[part 11 of 12: packages /E40_Platform_System_SystemPackage/Components to /E40_Platform_System_SystemPackage/Types]
AUTOSAR XML (schema 4-2-1)
package /E40_Platform_System_SystemPackage/Components  (continued)
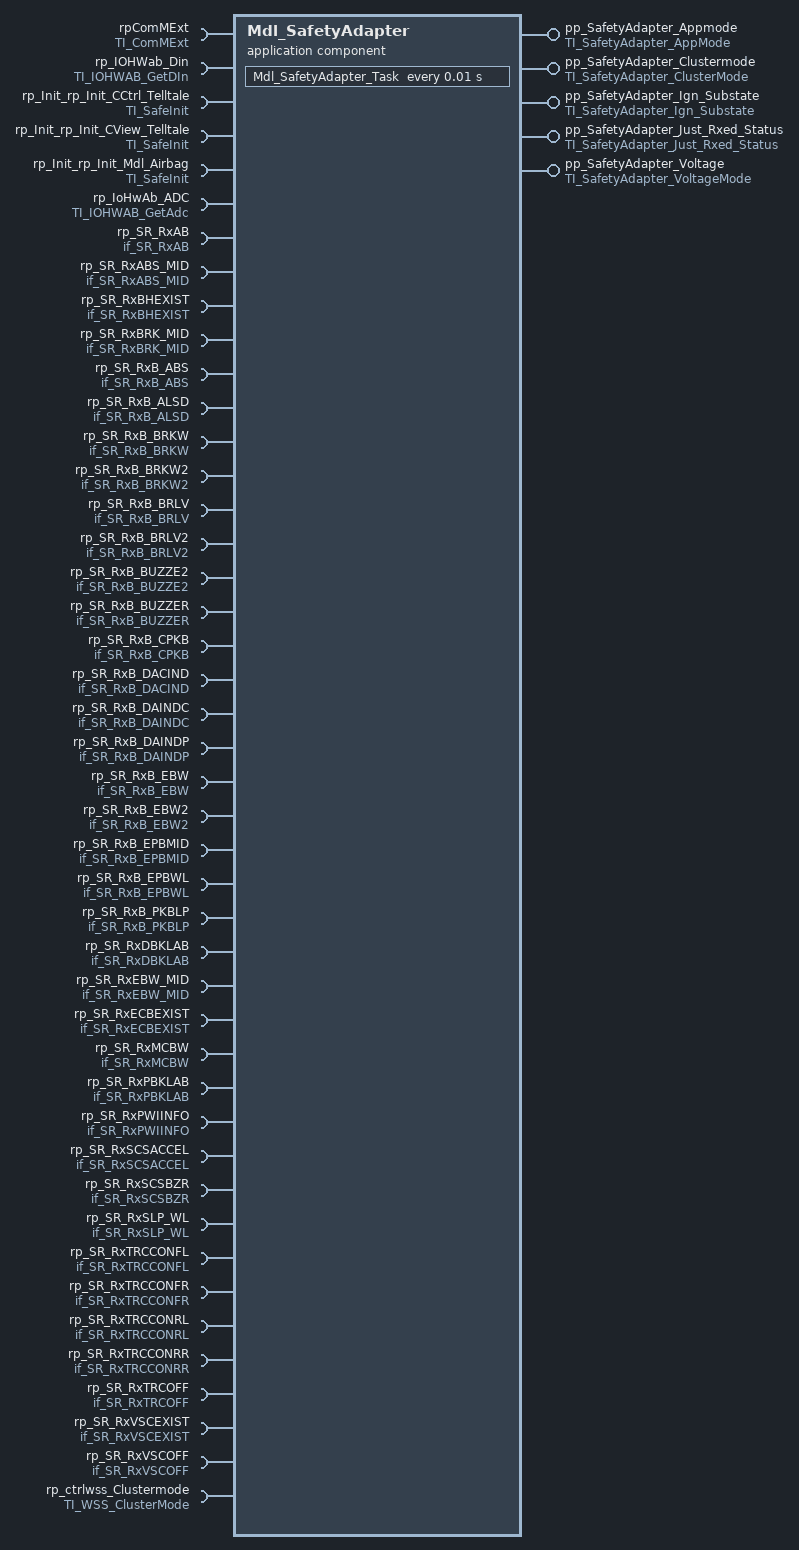
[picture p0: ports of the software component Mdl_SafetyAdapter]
  application sw component type Mdl_SafetyAdapter
    5 x provide port:
      pp_SafetyAdapter_Appmode: nonqueued-sender-com-spec{data-element=SafetyAdapter_AppMode, init-value=constant-reference=Mdl_SafetyAdapterSafetyAdapter_AppModeValue0}, provided-interface=TI_SafetyAdapter_AppMode
      pp_SafetyAdapter_Clustermode: nonqueued-sender-com-spec{data-element=SafetyAdapter_CurrentClusterMode, init-value=constant-reference=Mdl_SafetyAdapterSafetyAdapter_CurrentClusterModeValue0}, provided-interface=TI_SafetyAdapter_ClusterMode
      pp_SafetyAdapter_Ign_Substate: nonqueued-sender-com-spec{data-element=SafetyAdapter_Ign_Substate, init-value=constant-reference=Mdl_SafetyAdapterSafetyAdapter_Ign_SubstateValue0}, provided-interface=TI_SafetyAdapter_Ign_Substate
      pp_SafetyAdapter_Just_Rxed_Status: provided-interface=TI_SafetyAdapter_Just_Rxed_Status
        provided-com-specs:
          operation=TI_SafetyAdapter_Just_Rxed_Status/RxCan_SignalClearJustRcvdStatus, queue-length=1
          operation=TI_SafetyAdapter_Just_Rxed_Status/RxCan_SignalGetJustRcvdStatus, queue-length=1
      pp_SafetyAdapter_Voltage: provided-interface=TI_SafetyAdapter_VoltageMode
        provided-com-specs:
          data-element=SafetyAdapter_HVSD1, init-value=constant-reference=Mdl_SafetyAdapterSafetyAdapter_HVSD1Value0
          data-element=SafetyAdapter_LVSD1, init-value=constant-reference=Mdl_SafetyAdapterSafetyAdapter_LVSD1Value0
    44 x require port:
      rpComMExt: required-interface=TI_ComMExt
      rp_IOHWab_Din: required-interface=TI_IOHWAB_GetDIn
      rp_Init_rp_Init_CCtrl_Telltale: required-interface=TI_SafeInit
      rp_Init_rp_Init_CView_Telltale: required-interface=TI_SafeInit
      rp_Init_rp_Init_Mdl_Airbag: required-interface=TI_SafeInit
      rp_IoHwAb_ADC: required-interface=TI_IOHWAB_GetAdc
      rp_SR_RxAB: nonqueued-receiver-com-spec{data-element=AB, init-value=constant-reference=Mdl_SafetyAdapterABValue0}, required-interface=if_SR_RxAB
      rp_SR_RxABS_MID: nonqueued-receiver-com-spec{data-element=ABS_MID, init-value=constant-reference=Mdl_SafetyAdapterABS_MIDValue0}, required-interface=if_SR_RxABS_MID
      rp_SR_RxBHEXIST: nonqueued-receiver-com-spec{data-element=BHEXIST, init-value=constant-reference=Mdl_SafetyAdapterBHEXISTValue0}, required-interface=if_SR_RxBHEXIST
      rp_SR_RxBRK_MID: nonqueued-receiver-com-spec{data-element=BRK_MID, init-value=constant-reference=Mdl_SafetyAdapterBRK_MIDValue0}, required-interface=if_SR_RxBRK_MID
      rp_SR_RxB_ABS: nonqueued-receiver-com-spec{data-element=B_ABS, init-value=constant-reference=Mdl_SafetyAdapterB_ABSValue0}, required-interface=if_SR_RxB_ABS
      rp_SR_RxB_ALSD: nonqueued-receiver-com-spec{data-element=B_ALSD, init-value=constant-reference=Mdl_SafetyAdapterB_ALSDValue0}, required-interface=if_SR_RxB_ALSD
      rp_SR_RxB_BRKW: nonqueued-receiver-com-spec{data-element=B_BRKW, init-value=constant-reference=Mdl_SafetyAdapterB_BRKWValue0}, required-interface=if_SR_RxB_BRKW
      rp_SR_RxB_BRKW2: nonqueued-receiver-com-spec{data-element=B_BRKW2, init-value=constant-reference=Mdl_SafetyAdapterB_BRKW2Value0}, required-interface=if_SR_RxB_BRKW2
      rp_SR_RxB_BRLV: nonqueued-receiver-com-spec{data-element=B_BRLV, init-value=constant-reference=Mdl_SafetyAdapterB_BRLVValue0}, required-interface=if_SR_RxB_BRLV
      rp_SR_RxB_BRLV2: nonqueued-receiver-com-spec{data-element=B_BRLV2, init-value=constant-reference=Mdl_SafetyAdapterB_BRLV2Value0}, required-interface=if_SR_RxB_BRLV2
      rp_SR_RxB_BUZZE2: nonqueued-receiver-com-spec{data-element=B_BUZZE2, init-value=constant-reference=Mdl_SafetyAdapterB_BUZZE2Value0}, required-interface=if_SR_RxB_BUZZE2
      rp_SR_RxB_BUZZER: nonqueued-receiver-com-spec{data-element=B_BUZZER, init-value=constant-reference=Mdl_SafetyAdapterB_BUZZERValue0}, required-interface=if_SR_RxB_BUZZER
      rp_SR_RxB_CPKB: nonqueued-receiver-com-spec{data-element=B_CPKB, init-value=constant-reference=Mdl_SafetyAdapterB_CPKBValue0}, required-interface=if_SR_RxB_CPKB
      rp_SR_RxB_DACIND: nonqueued-receiver-com-spec{data-element=B_DACIND, init-value=constant-reference=Mdl_SafetyAdapterB_DACINDValue0}, required-interface=if_SR_RxB_DACIND
      rp_SR_RxB_DAINDC: nonqueued-receiver-com-spec{data-element=B_DAINDC, init-value=constant-reference=Mdl_SafetyAdapterB_DAINDCValue0}, required-interface=if_SR_RxB_DAINDC
      rp_SR_RxB_DAINDP: nonqueued-receiver-com-spec{data-element=B_DAINDP, init-value=constant-reference=Mdl_SafetyAdapterB_DAINDPValue0}, required-interface=if_SR_RxB_DAINDP
      rp_SR_RxB_EBW: nonqueued-receiver-com-spec{data-element=B_EBW, init-value=constant-reference=Mdl_SafetyAdapterB_EBWValue0}, required-interface=if_SR_RxB_EBW
      rp_SR_RxB_EBW2: nonqueued-receiver-com-spec{data-element=B_EBW2, init-value=constant-reference=Mdl_SafetyAdapterB_EBW2Value0}, required-interface=if_SR_RxB_EBW2
      rp_SR_RxB_EPBMID: nonqueued-receiver-com-spec{data-element=B_EPBMID, init-value=constant-reference=Mdl_SafetyAdapterB_EPBMIDValue0}, required-interface=if_SR_RxB_EPBMID
      rp_SR_RxB_EPBWL: nonqueued-receiver-com-spec{data-element=B_EPBWL, init-value=constant-reference=Mdl_SafetyAdapterB_EPBWLValue0}, required-interface=if_SR_RxB_EPBWL
      rp_SR_RxB_PKBLP: nonqueued-receiver-com-spec{data-element=B_PKBLP, init-value=constant-reference=Mdl_SafetyAdapterB_PKBLPValue0}, required-interface=if_SR_RxB_PKBLP
      rp_SR_RxDBKLAB: nonqueued-receiver-com-spec{data-element=DBKLAB, init-value=constant-reference=Mdl_SafetyAdapterDBKLABValue0}, required-interface=if_SR_RxDBKLAB
      rp_SR_RxEBW_MID: nonqueued-receiver-com-spec{data-element=EBW_MID, init-value=constant-reference=Mdl_SafetyAdapterEBW_MIDValue0}, required-interface=if_SR_RxEBW_MID
      rp_SR_RxECBEXIST: nonqueued-receiver-com-spec{data-element=ECBEXIST, init-value=constant-reference=Mdl_SafetyAdapterECBEXISTValue0}, required-interface=if_SR_RxECBEXIST
      rp_SR_RxMCBW: nonqueued-receiver-com-spec{data-element=MCBW, init-value=constant-reference=Mdl_SafetyAdapterMCBWValue0}, required-interface=if_SR_RxMCBW
      rp_SR_RxPBKLAB: nonqueued-receiver-com-spec{data-element=PBKLAB, init-value=constant-reference=Mdl_SafetyAdapterPBKLABValue0}, required-interface=if_SR_RxPBKLAB
      rp_SR_RxPWIINFO: nonqueued-receiver-com-spec{data-element=PWIINFO, init-value=constant-reference=Mdl_SafetyAdapterPWIINFOValue0}, required-interface=if_SR_RxPWIINFO
      rp_SR_RxSCSACCEL: nonqueued-receiver-com-spec{data-element=SCSACCEL, init-value=constant-reference=Mdl_SafetyAdapterSCSACCELValue0}, required-interface=if_SR_RxSCSACCEL
      rp_SR_RxSCSBZR: nonqueued-receiver-com-spec{data-element=SCSBZR, init-value=constant-reference=Mdl_SafetyAdapterSCSBZRValue0}, required-interface=if_SR_RxSCSBZR
      rp_SR_RxSLP_WL: nonqueued-receiver-com-spec{data-element=SLP_WL, init-value=constant-reference=Mdl_SafetyAdapterSLP_WLValue0}, required-interface=if_SR_RxSLP_WL
      rp_SR_RxTRCCONFL: nonqueued-receiver-com-spec{data-element=TRCCONFL, init-value=constant-reference=Mdl_SafetyAdapterTRCCONFLValue0}, required-interface=if_SR_RxTRCCONFL
      rp_SR_RxTRCCONFR: nonqueued-receiver-com-spec{data-element=TRCCONFR, init-value=constant-reference=Mdl_SafetyAdapterTRCCONFRValue0}, required-interface=if_SR_RxTRCCONFR
      rp_SR_RxTRCCONRL: nonqueued-receiver-com-spec{data-element=TRCCONRL, init-value=constant-reference=Mdl_SafetyAdapterTRCCONRLValue0}, required-interface=if_SR_RxTRCCONRL
      rp_SR_RxTRCCONRR: nonqueued-receiver-com-spec{data-element=TRCCONRR, init-value=constant-reference=Mdl_SafetyAdapterTRCCONRRValue0}, required-interface=if_SR_RxTRCCONRR
      rp_SR_RxTRCOFF: nonqueued-receiver-com-spec{data-element=TRCOFF, init-value=constant-reference=Mdl_SafetyAdapterTRCOFFValue0}, required-interface=if_SR_RxTRCOFF
      rp_SR_RxVSCEXIST: nonqueued-receiver-com-spec{data-element=VSCEXIST, init-value=constant-reference=Mdl_SafetyAdapterVSCEXISTValue0}, required-interface=if_SR_RxVSCEXIST
      rp_SR_RxVSCOFF: nonqueued-receiver-com-spec{data-element=VSCOFF, init-value=constant-reference=Mdl_SafetyAdapterVSCOFFValue0}, required-interface=if_SR_RxVSCOFF
      rp_ctrlwss_Clustermode: nonqueued-receiver-com-spec{data-element=WSSCurrentClusterMode, init-value=constant-reference=Mdl_SafetyAdapterWSSCurrentClusterModeValue0}, required-interface=TI_WSS_ClusterMode
    behavior IB_Mdl_SafetyAdapter
      4 x data received event:
        DREMdl_SafetyAdapter_OnDataRx_B_EBW2TrigByB_EBW2: start-on-event=Mdl_SafetyAdapter_OnDataRx_B_EBW2, data=rp_SR_RxB_EBW2.B_EBW2
        DREMdl_SafetyAdapter_OnDataRx_B_PKBLPTrigByB_PKBLP: start-on-event=Mdl_SafetyAdapter_OnDataRx_B_PKBLP, data=rp_SR_RxB_PKBLP.B_PKBLP
        DREMdl_SafetyAdapter_OnDataRx_SCSBZRTrigBySCSBZR: start-on-event=Mdl_SafetyAdapter_OnDataRx_SCSBZR, data=rp_SR_RxSCSBZR.SCSBZR
        DREMdl_SafetyAdapter_OnDataRx_VSCOFFTrigByVSCOFF: start-on-event=Mdl_SafetyAdapter_OnDataRx_VSCOFF, data=rp_SR_RxVSCOFF.VSCOFF
      operation invoked event OIE_pp_SafetyAdapter_Just_Rxed_Status_Mdl_SafetyAdapter_RxCan_SignalClearJustRcvdStatusTrigByRxCan_SignalClearJustRcvdStatus: start-on-event=Mdl_SafetyAdapter_RxCan_SignalClearJustRcvdStatus, operation=pp_SafetyAdapter_Just_Rxed_Status.RxCan_SignalClearJustRcvdStatus
      operation invoked event OIE_pp_SafetyAdapter_Just_Rxed_Status_Mdl_SafetyAdapter_RxCan_SignalGetJustRcvdStatusTrigByRxCan_SignalGetJustRcvdStatus: start-on-event=Mdl_SafetyAdapter_RxCan_SignalGetJustRcvdStatus, operation=pp_SafetyAdapter_Just_Rxed_Status.RxCan_SignalGetJustRcvdStatus
      timing event TEMdl_SafetyAdapter_Task: start-on-event=Mdl_SafetyAdapter_Task, period=0.01
      port-api-options:
        enable-take-address=false, indirect-api=false, port=pp_SafetyAdapter_Appmode
        enable-take-address=false, indirect-api=false, port=pp_SafetyAdapter_Clustermode
        enable-take-address=false, indirect-api=false, port=pp_SafetyAdapter_Ign_Substate
        enable-take-address=false, indirect-api=false, port=pp_SafetyAdapter_Just_Rxed_Status
        enable-take-address=false, indirect-api=false, port=pp_SafetyAdapter_Voltage
        enable-take-address=false, indirect-api=false, port=Mdl_SafetyAdapter/rpComMExt
        enable-take-address=false, indirect-api=false, port=rp_IOHWab_Din
        enable-take-address=false, indirect-api=false, port=rp_Init_rp_Init_CCtrl_Telltale
        enable-take-address=false, indirect-api=false, port=rp_Init_rp_Init_CView_Telltale
        enable-take-address=false, indirect-api=false, port=rp_Init_rp_Init_Mdl_Airbag
        enable-take-address=false, indirect-api=false, port=Mdl_SafetyAdapter/rp_IoHwAb_ADC
        enable-take-address=false, indirect-api=false, port=rp_SR_RxAB
        enable-take-address=false, indirect-api=false, port=rp_SR_RxABS_MID
        enable-take-address=false, indirect-api=false, port=rp_SR_RxBHEXIST
        enable-take-address=false, indirect-api=false, port=rp_SR_RxBRK_MID
        enable-take-address=false, indirect-api=false, port=rp_SR_RxB_ABS
        enable-take-address=false, indirect-api=false, port=rp_SR_RxB_ALSD
        enable-take-address=false, indirect-api=false, port=rp_SR_RxB_BRKW
        enable-take-address=false, indirect-api=false, port=rp_SR_RxB_BRKW2
        enable-take-address=false, indirect-api=false, port=rp_SR_RxB_BRLV
        enable-take-address=false, indirect-api=false, port=rp_SR_RxB_BRLV2
        enable-take-address=false, indirect-api=false, port=rp_SR_RxB_BUZZE2
        enable-take-address=false, indirect-api=false, port=rp_SR_RxB_BUZZER
        enable-take-address=false, indirect-api=false, port=rp_SR_RxB_CPKB
        enable-take-address=false, indirect-api=false, port=rp_SR_RxB_DACIND
        enable-take-address=false, indirect-api=false, port=rp_SR_RxB_DAINDC
        enable-take-address=false, indirect-api=false, port=rp_SR_RxB_DAINDP
        enable-take-address=false, indirect-api=false, port=rp_SR_RxB_EBW
        enable-take-address=false, indirect-api=false, port=rp_SR_RxB_EBW2
        enable-take-address=false, indirect-api=false, port=rp_SR_RxB_EPBMID
        enable-take-address=false, indirect-api=false, port=rp_SR_RxB_EPBWL
        enable-take-address=false, indirect-api=false, port=rp_SR_RxB_PKBLP
        enable-take-address=false, indirect-api=false, port=rp_SR_RxDBKLAB
        enable-take-address=false, indirect-api=false, port=rp_SR_RxEBW_MID
        enable-take-address=false, indirect-api=false, port=rp_SR_RxECBEXIST
        enable-take-address=false, indirect-api=false, port=rp_SR_RxMCBW
        enable-take-address=false, indirect-api=false, port=rp_SR_RxPBKLAB
        enable-take-address=false, indirect-api=false, port=rp_SR_RxPWIINFO
        enable-take-address=false, indirect-api=false, port=rp_SR_RxSCSACCEL
        enable-take-address=false, indirect-api=false, port=rp_SR_RxSCSBZR
        enable-take-address=false, indirect-api=false, port=rp_SR_RxSLP_WL
        enable-take-address=false, indirect-api=false, port=rp_SR_RxTRCCONFL
        enable-take-address=false, indirect-api=false, port=rp_SR_RxTRCCONFR
        enable-take-address=false, indirect-api=false, port=rp_SR_RxTRCCONRL
        enable-take-address=false, indirect-api=false, port=rp_SR_RxTRCCONRR
        enable-take-address=false, indirect-api=false, port=rp_SR_RxTRCOFF
        enable-take-address=false, indirect-api=false, port=rp_SR_RxVSCEXIST
        enable-take-address=false, indirect-api=false, port=rp_SR_RxVSCOFF
        enable-take-address=false, indirect-api=false, port=rp_ctrlwss_Clustermode
      7 x runnable, all with can-be-invoked-concurrently=true:
        Mdl_SafetyAdapter_OnDataRx_B_EBW2
        Mdl_SafetyAdapter_OnDataRx_B_PKBLP
        Mdl_SafetyAdapter_OnDataRx_SCSBZR
        Mdl_SafetyAdapter_OnDataRx_VSCOFF
        Mdl_SafetyAdapter_RxCan_SignalClearJustRcvdStatus
        Mdl_SafetyAdapter_RxCan_SignalGetJustRcvdStatus
        Mdl_SafetyAdapter_Task
          data-receive-point-by-arguments:
            38 x access:
              DRA_rp_SR_RxAB_AB: accessed-variable=rp_SR_RxAB.AB
              DRA_rp_SR_RxABS_MID_ABS_MID: accessed-variable=rp_SR_RxABS_MID.ABS_MID
              DRA_rp_SR_RxBHEXIST_BHEXIST: accessed-variable=rp_SR_RxBHEXIST.BHEXIST
              DRA_rp_SR_RxBRK_MID_BRK_MID: accessed-variable=rp_SR_RxBRK_MID.BRK_MID
              DRA_rp_SR_RxB_ABS_B_ABS: accessed-variable=rp_SR_RxB_ABS.B_ABS
              DRA_rp_SR_RxB_ALSD_B_ALSD: accessed-variable=rp_SR_RxB_ALSD.B_ALSD
              DRA_rp_SR_RxB_BRKW_B_BRKW: accessed-variable=rp_SR_RxB_BRKW.B_BRKW
              DRA_rp_SR_RxB_BRKW2_B_BRKW2: accessed-variable=rp_SR_RxB_BRKW2.B_BRKW2
              DRA_rp_SR_RxB_BRLV_B_BRLV: accessed-variable=rp_SR_RxB_BRLV.B_BRLV
              DRA_rp_SR_RxB_BRLV2_B_BRLV2: accessed-variable=rp_SR_RxB_BRLV2.B_BRLV2
              DRA_rp_SR_RxB_BUZZE2_B_BUZZE2: accessed-variable=rp_SR_RxB_BUZZE2.B_BUZZE2
              DRA_rp_SR_RxB_BUZZER_B_BUZZER: accessed-variable=rp_SR_RxB_BUZZER.B_BUZZER
              DRA_rp_SR_RxB_CPKB_B_CPKB: accessed-variable=rp_SR_RxB_CPKB.B_CPKB
              DRA_rp_SR_RxB_DACIND_B_DACIND: accessed-variable=rp_SR_RxB_DACIND.B_DACIND
              DRA_rp_SR_RxB_DAINDC_B_DAINDC: accessed-variable=rp_SR_RxB_DAINDC.B_DAINDC
              DRA_rp_SR_RxB_DAINDP_B_DAINDP: accessed-variable=rp_SR_RxB_DAINDP.B_DAINDP
              DRA_rp_SR_RxB_EBW_B_EBW: accessed-variable=rp_SR_RxB_EBW.B_EBW
              DRA_rp_SR_RxB_EBW2_B_EBW2: accessed-variable=rp_SR_RxB_EBW2.B_EBW2
              DRA_rp_SR_RxB_EPBMID_B_EPBMID: accessed-variable=rp_SR_RxB_EPBMID.B_EPBMID
              DRA_rp_SR_RxB_EPBWL_B_EPBWL: accessed-variable=rp_SR_RxB_EPBWL.B_EPBWL
              DRA_rp_SR_RxB_PKBLP_B_PKBLP: accessed-variable=rp_SR_RxB_PKBLP.B_PKBLP
              DRA_rp_SR_RxDBKLAB_DBKLAB: accessed-variable=rp_SR_RxDBKLAB.DBKLAB
              DRA_rp_SR_RxEBW_MID_EBW_MID: accessed-variable=rp_SR_RxEBW_MID.EBW_MID
              DRA_rp_SR_RxECBEXIST_ECBEXIST: accessed-variable=rp_SR_RxECBEXIST.ECBEXIST
              DRA_rp_SR_RxMCBW_MCBW: accessed-variable=rp_SR_RxMCBW.MCBW
              DRA_rp_SR_RxPBKLAB_PBKLAB: accessed-variable=rp_SR_RxPBKLAB.PBKLAB
              DRA_rp_SR_RxPWIINFO_PWIINFO: accessed-variable=rp_SR_RxPWIINFO.PWIINFO
              DRA_rp_SR_RxSCSACCEL_SCSACCEL: accessed-variable=rp_SR_RxSCSACCEL.SCSACCEL
              DRA_rp_SR_RxSCSBZR_SCSBZR: accessed-variable=rp_SR_RxSCSBZR.SCSBZR
              DRA_rp_SR_RxSLP_WL_SLP_WL: accessed-variable=rp_SR_RxSLP_WL.SLP_WL
              DRA_rp_SR_RxTRCCONFL_TRCCONFL: accessed-variable=rp_SR_RxTRCCONFL.TRCCONFL
              DRA_rp_SR_RxTRCCONFR_TRCCONFR: accessed-variable=rp_SR_RxTRCCONFR.TRCCONFR
              DRA_rp_SR_RxTRCCONRL_TRCCONRL: accessed-variable=rp_SR_RxTRCCONRL.TRCCONRL
              DRA_rp_SR_RxTRCCONRR_TRCCONRR: accessed-variable=rp_SR_RxTRCCONRR.TRCCONRR
              DRA_rp_SR_RxTRCOFF_TRCOFF: accessed-variable=rp_SR_RxTRCOFF.TRCOFF
              DRA_rp_SR_RxVSCEXIST_VSCEXIST: accessed-variable=rp_SR_RxVSCEXIST.VSCEXIST
              DRA_rp_SR_RxVSCOFF_VSCOFF: accessed-variable=rp_SR_RxVSCOFF.VSCOFF
              DRA_rp_ctrlwss_Clustermode_WSSCurrentClusterMode: accessed-variable=rp_ctrlwss_Clustermode.WSSCurrentClusterMode
          data-send-points:
            5 x access:
              DWA_pp_SafetyAdapter_Appmode_SafetyAdapter_AppMode: accessed-variable=pp_SafetyAdapter_Appmode.SafetyAdapter_AppMode
              DWA_pp_SafetyAdapter_Clustermode_SafetyAdapter_CurrentClusterMode: accessed-variable=pp_SafetyAdapter_Clustermode.SafetyAdapter_CurrentClusterMode
              DWA_pp_SafetyAdapter_Ign_Substate_SafetyAdapter_Ign_Substate: accessed-variable=pp_SafetyAdapter_Ign_Substate.SafetyAdapter_Ign_Substate
              DWA_pp_SafetyAdapter_Voltage_SafetyAdapter_HVSD1: accessed-variable=pp_SafetyAdapter_Voltage.SafetyAdapter_HVSD1
              DWA_pp_SafetyAdapter_Voltage_SafetyAdapter_LVSD1: accessed-variable=pp_SafetyAdapter_Voltage.SafetyAdapter_LVSD1
          23 x sync call, all with timeout=0:
            OA_rpComMExt_Get_MCAN_ERR_PIN_Status: operation=rpComMExt.Get_MCAN_ERR_PIN_Status
            OA_rpComMExt_Init: operation=rpComMExt.Init
            OA_rpComMExt_GetBusOffStatus: operation=rpComMExt.GetBusOffStatus
            OA_rpComMExt_CAN_RequestCommunication: operation=rpComMExt.CAN_RequestCommunication
            OA_rpComMExt_CAN_GetCurrentComMode: operation=rpComMExt.CAN_GetCurrentComMode
            OA_rpComMExt_CAN_ReleaseCommunication: operation=rpComMExt.CAN_ReleaseCommunication
            OA_rpComMExt_CAN_DeActivateSilentCommunication: operation=rpComMExt.CAN_DeActivateSilentCommunication
            OA_rpComMExt_CAN_CommControlSetDone: operation=rpComMExt.CAN_CommControlSetDone
            OA_rpComMExt_CAN_CommControlDeActivateTx: operation=rpComMExt.CAN_CommControlDeActivateTx
            OA_rpComMExt_CAN_CommControlDeActivateRx: operation=rpComMExt.CAN_CommControlDeActivateRx
            OA_rpComMExt_CAN_ActivateSilentCommunication: operation=rpComMExt.CAN_ActivateSilentCommunication
            OA_rpComMExt_CAN_CommControlActivateRx: operation=rpComMExt.CAN_CommControlActivateRx
            OA_rpComMExt_CAN_CommControlActivateTx: operation=rpComMExt.CAN_CommControlActivateTx
            OA_rp_IOHWab_Din_GetAsyncRawInput: operation=rp_IOHWab_Din.GetAsyncRawInput
            OA_rp_IOHWab_Din_GetProcessedInput: operation=rp_IOHWab_Din.GetProcessedInput
            OA_rp_IOHWab_Din_GetSyncRawInput: operation=rp_IOHWab_Din.GetSyncRawInput
            OA_rp_IOHWab_Din_GetInputGroup: operation=rp_IOHWab_Din.GetInputGroup
            OA_rp_Init_rp_Init_CCtrl_Telltale_Init: operation=rp_Init_rp_Init_CCtrl_Telltale.Init
            OA_rp_Init_rp_Init_CView_Telltale_Init: operation=rp_Init_rp_Init_CView_Telltale.Init
            OA_rp_Init_rp_Init_Mdl_Airbag_Init: operation=rp_Init_rp_Init_Mdl_Airbag.Init
            OA_rp_IoHwAb_ADC_GetAsyncRawAdc: operation=rp_IoHwAb_ADC.GetAsyncRawAdc
            OA_rp_IoHwAb_ADC_GetSyncRawAdc: operation=rp_IoHwAb_ADC.GetSyncRawAdc
            OA_rp_IoHwAb_ADC_GetProcessedAdc: operation=rp_IoHwAb_ADC.GetProcessedAdc
  43 x constant specification:
    Mdl_SafetyAdapterSafetyAdapter_AppModeValue0: value-spec=Mdl_SafetyAdapterSafetyAdapter_AppModeValue0:0
    Mdl_SafetyAdapterSafetyAdapter_CurrentClusterModeValue0: value-spec=Mdl_SafetyAdapterSafetyAdapter_CurrentClusterModeValue0:0
    Mdl_SafetyAdapterSafetyAdapter_Ign_SubstateValue0: value-spec=Mdl_SafetyAdapterSafetyAdapter_Ign_SubstateValue0:0
    Mdl_SafetyAdapterSafetyAdapter_HVSD1Value0: value-spec=Mdl_SafetyAdapterSafetyAdapter_HVSD1Value0:0
    Mdl_SafetyAdapterSafetyAdapter_LVSD1Value0: value-spec=Mdl_SafetyAdapterSafetyAdapter_LVSD1Value0:0
    Mdl_SafetyAdapterABValue0: value-spec=Mdl_SafetyAdapterABValue0:0
    Mdl_SafetyAdapterABS_MIDValue0: value-spec=Mdl_SafetyAdapterABS_MIDValue0:0
    Mdl_SafetyAdapterBHEXISTValue0: value-spec=Mdl_SafetyAdapterBHEXISTValue0:0
    Mdl_SafetyAdapterBRK_MIDValue0: value-spec=Mdl_SafetyAdapterBRK_MIDValue0:0
    Mdl_SafetyAdapterB_ABSValue0: value-spec=Mdl_SafetyAdapterB_ABSValue0:0
    Mdl_SafetyAdapterB_ALSDValue0: value-spec=Mdl_SafetyAdapterB_ALSDValue0:0
    Mdl_SafetyAdapterB_BRKWValue0: value-spec=Mdl_SafetyAdapterB_BRKWValue0:0
    Mdl_SafetyAdapterB_BRKW2Value0: value-spec=Mdl_SafetyAdapterB_BRKW2Value0:0
    Mdl_SafetyAdapterB_BRLVValue0: value-spec=Mdl_SafetyAdapterB_BRLVValue0:0
    Mdl_SafetyAdapterB_BRLV2Value0: value-spec=Mdl_SafetyAdapterB_BRLV2Value0:0
    Mdl_SafetyAdapterB_BUZZE2Value0: value-spec=Mdl_SafetyAdapterB_BUZZE2Value0:0
    Mdl_SafetyAdapterB_BUZZERValue0: value-spec=Mdl_SafetyAdapterB_BUZZERValue0:0
    Mdl_SafetyAdapterB_CPKBValue0: value-spec=Mdl_SafetyAdapterB_CPKBValue0:0
    Mdl_SafetyAdapterB_DACINDValue0: value-spec=Mdl_SafetyAdapterB_DACINDValue0:0
    Mdl_SafetyAdapterB_DAINDCValue0: value-spec=Mdl_SafetyAdapterB_DAINDCValue0:0
    Mdl_SafetyAdapterB_DAINDPValue0: value-spec=Mdl_SafetyAdapterB_DAINDPValue0:0
    Mdl_SafetyAdapterB_EBWValue0: value-spec=Mdl_SafetyAdapterB_EBWValue0:0
    Mdl_SafetyAdapterB_EBW2Value0: value-spec=Mdl_SafetyAdapterB_EBW2Value0:0
    Mdl_SafetyAdapterB_EPBMIDValue0: value-spec=Mdl_SafetyAdapterB_EPBMIDValue0:0
    Mdl_SafetyAdapterB_EPBWLValue0: value-spec=Mdl_SafetyAdapterB_EPBWLValue0:0
    Mdl_SafetyAdapterB_PKBLPValue0: value-spec=Mdl_SafetyAdapterB_PKBLPValue0:0
    Mdl_SafetyAdapterDBKLABValue0: value-spec=Mdl_SafetyAdapterDBKLABValue0:0
    Mdl_SafetyAdapterEBW_MIDValue0: value-spec=Mdl_SafetyAdapterEBW_MIDValue0:0
    Mdl_SafetyAdapterECBEXISTValue0: value-spec=Mdl_SafetyAdapterECBEXISTValue0:0
    Mdl_SafetyAdapterMCBWValue0: value-spec=Mdl_SafetyAdapterMCBWValue0:0
    Mdl_SafetyAdapterPBKLABValue0: value-spec=Mdl_SafetyAdapterPBKLABValue0:0
    Mdl_SafetyAdapterPWIINFOValue0: value-spec=Mdl_SafetyAdapterPWIINFOValue0:0
    Mdl_SafetyAdapterSCSACCELValue0: value-spec=Mdl_SafetyAdapterSCSACCELValue0:0
    Mdl_SafetyAdapterSCSBZRValue0: value-spec=Mdl_SafetyAdapterSCSBZRValue0:0
    Mdl_SafetyAdapterSLP_WLValue0: value-spec=Mdl_SafetyAdapterSLP_WLValue0:0
    Mdl_SafetyAdapterTRCCONFLValue0: value-spec=Mdl_SafetyAdapterTRCCONFLValue0:0
    Mdl_SafetyAdapterTRCCONFRValue0: value-spec=Mdl_SafetyAdapterTRCCONFRValue0:0
    Mdl_SafetyAdapterTRCCONRLValue0: value-spec=Mdl_SafetyAdapterTRCCONRLValue0:0
    Mdl_SafetyAdapterTRCCONRRValue0: value-spec=Mdl_SafetyAdapterTRCCONRRValue0:0
    Mdl_SafetyAdapterTRCOFFValue0: value-spec=Mdl_SafetyAdapterTRCOFFValue0:0
    Mdl_SafetyAdapterVSCEXISTValue0: value-spec=Mdl_SafetyAdapterVSCEXISTValue0:0
    Mdl_SafetyAdapterVSCOFFValue0: value-spec=Mdl_SafetyAdapterVSCOFFValue0:0
    Mdl_SafetyAdapterWSSCurrentClusterModeValue0: value-spec=Mdl_SafetyAdapterWSSCurrentClusterModeValue0:0
  swc implementation IMPL_Mdl_SafetyAdapter: programming-language=C, behavior=IB_Mdl_SafetyAdapter
    code-descriptors:
      code CodeDescriptor
  constant specification SFastGaugeInfo_InitValue: value-spec={short-label=SFastGaugeInfo_InitValue, fields=[fields=[0, 0, 0, 0, 0], fields=[0, 0, 0, 0, 0]]}
package /E40_Platform_System_SystemPackage/Compositions
  composition sw component type E40_Platform_System
    64 x component:
      CBacklightCdd: type=CBacklightCdd
      CCDD_BswFit: type=CCDD_BswFit
      CCDD_EcuBatteryM: type=CCDD_EcuBatteryM
      CCDD_EcuPowerM: type=CCDD_EcuPowerM
      CCDD_FitManager: type=CCDD_FitManager
      CCDD_McuFit: type=CCDD_McuFit
      CComAbsCtrl: type=CComAbsCtrl
      CComAbsMdl: type=CComAbsMdl
      CComAbsMdlSafe: type=CComAbsMdlSafe
      CCtrl_Telltale: type=CCtrl_Telltale
      DcmApp: type=DcmApp
      DemApp: type=DemApp
      CDisplayCdd: type=CDisplayCdd
      CFltM: type=CFltM
      CFltMExt: type=CFltMExt
      GdtCdd: type=GdtCdd
      CIoExp: type=CIoExp
      CMeetCdd: type=CMeetCdd
      CPmicCdd: type=CPmicCdd
      CRstM: type=CRstM
      RtcCdd: type=RtcCdd
      SafeNvM: type=SafeNvM
      CSigCdd: type=CSigCdd
      CSndCdd: type=CSndCdd
      CSwcDispMonSf: type=CSwcDispMonSf
      CUpdateCdd: type=CUpdateCdd
      CView_Telltale: type=CView_Telltale
      CWarnMsg_Core_Observer: type=CWarnMsg_Core_Observer
      ComCallout: type=ComCallout
      ComMExt: type=ComMExt
      CorTst: type=CorTst
      Ctrl_Illumination: type=Ctrl_Illumination
      Ctrl_WSS: type=Ctrl_WSS
      Ctrl_warning: type=Ctrl_warning
      DcmExt: type=DcmExt
      DemExt: type=DemExt
      Dlt: type=Dlt
      DltExt: type=DltExt
      DmnMgr: type=DmnMgr
      EcuAppM: type=EcuAppM
      EcuMExt: type=EcuMExt
      FastGaugeAdapter: type=FastGaugeAdapter
      FlsTst: type=FlsTst
      IoHwAb: type=IoHwAb
      Mdl_Airbag: type=Mdl_Airbag
      Mdl_Dim: type=Mdl_Dim
      Mdl_Gear: type=Mdl_Gear
      Mdl_Linear_Interpolation: type=Mdl_Linear_Interpolation
      Mdl_SafetyAdapter: type=Mdl_SafetyAdapter
      Mdl_Speed: type=Mdl_Speed
      Mdl_Tacho: type=Mdl_Tacho
      Mdl_TurnHazard: type=Mdl_TurnHazard
      Mdl_wAirbag: type=Mdl_wAirbag
      Mdl_wFuelLidOpen: type=Mdl_wFuelLidOpen
      MemAbstractMdl: type=MemAbstractMdl
      NvMExt: type=NvMExt
      RamTst: type=RamTst
      SlowGaugeAdapter: type=SlowGaugeAdapter
      SysTst: type=SysTst
      TmExt: type=TmExt
      UclProxyCdd: type=UclProxyCdd
      View_Illumination: type=View_Illumination
      View_Speed: type=View_Speed
      WarnMsg_Core_TmrSupport: type=WarnMsg_Core_TmrSupport
    connect IoHwAb.ppIoHwAb_Din -> CBacklightCdd.rpIoHwAb_Din
    connect IoHwAb.ppIoHwAb_DOut -> CBacklightCdd.rpIoHwAb_DOut
    connect IoHwAb.ppIoHwAb_PWM -> CBacklightCdd.rpIoHwAb_PWM
    connect CBacklightCdd.pp_CmpLibCmd_CBacklightCdd -> EcuAppM.rp_CmpLibCmd_rp_CmpLibCmd_CBacklightCdd
    connect IoHwAb.ppIoHwAb_ADC -> CCDD_EcuBatteryM.rpIoHwAb_ADC
    connect IoHwAb.ppIoHwAb_Din -> CCDD_EcuBatteryM.rpIoHwAb_Din
    connect IoHwAb.ppIoHwAb_DOut -> CCDD_EcuBatteryM.rpIoHwAb_DOut
    connect IoHwAb.ppIoHwAb_PWM -> CCDD_EcuBatteryM.rpIoHwAb_PWM
    connect CCDD_EcuBatteryM.pp_CmpLibCmd -> EcuAppM.rp_CmpLibCmd_rp_CmpLibCmd_CCDD_EcuBatteryM
    connect IoHwAb.ppIoHwAb_Din -> CCDD_EcuPowerM.rpIoHwAb_Din
    connect IoHwAb.ppIoHwAb_DOut -> CCDD_EcuPowerM.rpIoHwAb_DOut
    connect IoHwAb.ppIoHwAb_PWM -> CCDD_EcuPowerM.rpIoHwAb_PWM
    connect IoHwAb.ppIoHwAb_ADC -> CCDD_EcuPowerM.rpIoHwAb_ADC
    connect CCDD_EcuPowerM.pp_CmpLibCmd -> EcuAppM.rp_CmpLibCmd_rp_CmpLibCmd_CCDD_EcuPowerM
    connect IoHwAb.ppIoHwAb_Din -> CComAbsCtrl.rp_CS_IoHwAb_Din
    connect ComMExt.ppComMExt -> CComAbsCtrl.rpCSComMExt
    connect MemAbstractMdl.pp_CS_MemAbsGet -> CComAbsMdl.rp_CS_MemAbsGet
    connect CComAbsMdl.pp_CS_RxCanMdl -> CComAbsCtrl.rpCSRxCanMdl
    connect CComAbsMdl.pp_CS_TxCanMdl -> CComAbsCtrl.rpCSTxCanMdl
    connect MemAbstractMdl.pp_CS_MemAbsGet -> CComAbsMdlSafe.rp_CS_MemAbsGet
    connect CComAbsMdlSafe.pp_CS_RxCanMdlSafe -> CComAbsCtrl.rpCS_RxCanMdlSafe
    connect CComAbsMdlSafe.pp_CS_TxCanMdlSafe -> CComAbsCtrl.rpCS_TxCanMdlSafe
    connect CComAbsCtrl.pp_CmpLibCmd_CComAbsCtrl -> EcuAppM.rp_CmpLibCmd_rp_CmpLibCmd_CComAbsCtrl
    connect CComAbsMdl.pp_CmpLibCmd_CComAbsMdl -> EcuAppM.rp_CmpLibCmd_rp_CmpLibCmd_CComAbsMdl
    connect CComAbsMdlSafe.pp_CmpLibCmd_CComAbsMdlSafe -> EcuAppM.rp_CmpLibCmd_rp_CmpLibCmd_CComAbsMdlSafe
    connect IoHwAb.ppIoHwAb_PWM -> Ctrl_Illumination.rp_PwmSetDuty
    assembly sw connector E40_Platform_System_CS_Mdl_Dimrp_CS_RxCanMdl_CComAbsMdlpp_CS_RxCanMdl_if_CS_ComAbsRx: requester=Mdl_Dim.rp_CS_RxCanMdl
    assembly sw connector E40_Platform_System_CS_Ctrl_WSSrp_CS_RxCanMdl_CComAbsMdlpp_CS_RxCanMdl_if_CS_ComAbsRx: requester=Ctrl_WSS.rp_CS_RxCanMdl
    connect IoHwAb.ppIoHwAb_Din -> Ctrl_WSS.rpIoHwAb_Din
    connect ComMExt.ppComMExt -> Ctrl_WSS.rpComMExt
    connect NvMExt.pp_CS_NvMExt_SleepOperations -> Ctrl_WSS.rp_CS_NvMExt_SleepOperations
    connect TmExt.pp_CS_TmExt_Timer_Stop -> Ctrl_WSS.rp_CS_TmExt_Timer_Stop
    connect TmExt.pp_CS_TmExt_Timer_IsElapsed -> Ctrl_WSS.rp_CS_TmExt_Timer_Elapsed
    connect TmExt.pp_CS_TmExt_Timer_Start -> Ctrl_WSS.rp_CS_TmExt_Timer_Start
    connect TmExt.pp_CS_TmExt_Timer_IsStarted -> Ctrl_WSS.rp_CS_TmExt_Timer_Started
    connect IoHwAb.ppIoHwAb_ADC -> Ctrl_WSS.rpIoHwAb_ADC
    connect Mdl_Dim.pp_IlumDayNightStatus -> Ctrl_WSS.rp_IlumDayNightStatus
    connect Ctrl_WSS.pp_ClusterMode -> CWarnMsg_Core_Observer.rp_ClusterMode
    connect Ctrl_WSS.ppIgnSubstate -> CWarnMsg_Core_Observer.rpIgnSubstate
    connect Ctrl_WSS.pp_ClusterMode -> Ctrl_warning.rp_ClusterMode
    connect Ctrl_WSS.ppIgnSubstate -> Ctrl_warning.rpIgnSubstate
    connect Ctrl_warning.ppWarningActiveStatus -> CWarnMsg_Core_Observer.rp_ActiveWarningSts
    connect Ctrl_warning.ppWarnDisplayStatus -> CWarnMsg_Core_Observer.rp_UpdateDisplayStatus
    connect UclProxyCdd.pSR_HealthDomainFatalError -> DmnMgr.rSR_HealthDomainFatalError
    connect UclProxyCdd.pSR_HealthDomainHeartbeat -> DmnMgr.rSR_HealthDomainHeartbeat
    connect UclProxyCdd.pSR_HealthDumpData -> DmnMgr.rSR_HealthDumpData
    connect UclProxyCdd.pSR_HealthDumpHdrInfo -> DmnMgr.rSR_HealthDumpHdrInfo
    connect UclProxyCdd.pSR_PowerExtendShutdownTime -> DmnMgr.rSR_PowerExtendShutdownTime
    connect UclProxyCdd.pSR_PowerKeepSystemAwake -> DmnMgr.rSR_PowerKeepSystemAwake
    connect UclProxyCdd.pSR_PowerSystemState -> DmnMgr.rSR_PowerSystemState
    connect UclProxyCdd.ppCS_UclInitShutdown -> DmnMgr.rpCS_UclInitShutdown
    connect DmnMgr.ppSR_DmnInfo -> DmnMgr.rpSR_DmnInfo
    connect Ctrl_WSS.pp_SleepOperation -> DmnMgr.rp_CS_SleepOperation
    connect DmnMgr.ppCS_UclSystemCallbacks -> UclProxyCdd.rCS_UclSystemCallbacks
    connect DmnMgr.pSR_HealthDumpGetHdr -> UclProxyCdd.rSR_HealthDumpGetHdr
    connect DmnMgr.pSR_HealthDumpGetData -> UclProxyCdd.rSR_HealthDumpGetData
    connect IoHwAb.ppIoHwAb_ADC -> CMeetCdd.rpIoHwAb_ADC
    connect IoHwAb.ppIoHwAb_Din -> CMeetCdd.rpIoHwAb_Din
    connect IoHwAb.ppIoHwAb_DOut -> CMeetCdd.rpIoHwAb_DOut
    connect IoHwAb.ppIoHwAb_PWM -> CMeetCdd.rpIoHwAb_PWM
    connect MemAbstractMdl.pp_CS_MemAbsGet -> CMeetCdd.rp_CS_MemAbsGet
    connect MemAbstractMdl.pp_CS_MemAbsSet -> CMeetCdd.rp_CS_MemAbsSet
    connect MemAbstractMdl.pp_SR_JobStatus -> CMeetCdd.rp_SR_JobStatus
    connect UclProxyCdd.pSR_DiagResponse -> CMeetCdd.rSR_DiagResponse
    connect CMeetCdd.pSR_DiagDIDRequest -> UclProxyCdd.rSR_DiagDIDRequest
    connect CMeetCdd.pSR_DiagRoutineRequest -> UclProxyCdd.rSR_DiagRoutineRequest
    connect CMeetCdd.pSR_DiagIOCtrlRequest -> UclProxyCdd.rSR_DiagIOCtrlRequest
    connect DmnMgr.pSR_PowerSystemStateReqChange -> UclProxyCdd.rSR_PowerSystemStateReqChange
    connect Ctrl_WSS.ppIgnSubstate -> Mdl_Gear.rpIgnSubstate
    connect Ctrl_WSS.pp_VehicleAppMode -> Mdl_Gear.rpVehicleAppMode
    assembly sw connector E40_Platform_System_CS_Mdl_Gearrp_CS_RxCanMdl_CComAbsMdlpp_CS_RxCanMdl_if_CS_ComAbsRx: requester=Mdl_Gear.rp_CS_RxCanMdl
    connect Ctrl_WSS.pp_Variant_status -> Mdl_Gear.rp_Variant_Status
    connect CComAbsMdl.pp_CS_RxCanMdl -> Mdl_Gear.rp_CS_CanRx
    connect Ctrl_WSS.pp_ClusterMode -> Mdl_Gear.rp_ClusterMode
    connect Ctrl_WSS.pp_HMIReady -> Mdl_Gear.rp_HMI_Ready_Status
    connect Mdl_Gear.pp_Shiftpos_ShiftPosIndStatus -> UclProxyCdd.rSR_ShiftPosIndStatus
    connect IoHwAb.ppIoHwAb_PWM -> View_Illumination.rp_PwmSetDuty
    assembly sw connector E40_Platform_System_CS_View_Illuminationrp_GetNVM_IlluminationElement_MemAbstractMdlpp_CS_MemAbsGet_if_CS_MemAbsGet: requester=View_Illumination.rp_GetNVM_IlluminationElement
    connect MemAbstractMdl.pp_CS_MemAbsSet -> View_Illumination.rp_SetNVM_IlluminationElement
    connect IoHwAb.ppIoHwAb_Din -> View_Illumination.rpIoHwAb_Din
    connect Ctrl_WSS.ppIgnSubstate -> View_Illumination.rpIgnSubstate
    connect Ctrl_WSS.pp_VehicleAppMode -> View_Illumination.rpVehicleAppMode
    connect Mdl_Dim.pp_RheostatDayStep -> View_Illumination.rp_RheostatDayStep
    connect Mdl_Dim.pp_RheostatNightStep -> View_Illumination.rp_RheostatNightStep
    connect Mdl_Dim.pp_illum_rheostat_change -> View_Illumination.rp_Rheostat_Change
    connect Ctrl_WSS.pp_TFTDisplayOn -> View_Illumination.rp_TFTDisplayOn
    connect MemAbstractMdl.pp_CS_MemAbsGet -> View_Illumination.rp_CS_MemAbsGet
    connect TmExt.pp_CS_TmExt_Timer_IsElapsed -> View_Illumination.rp_TmExt_Timer_IsElapsed
    connect TmExt.pp_CS_TmExt_Timer_IsStarted -> View_Illumination.rp_TmExt_Timer_IsStarted
    connect TmExt.pp_CS_TmExt_Timer_Start -> View_Illumination.rp_TmExt_Timer_Start
    connect TmExt.pp_CS_TmExt_Timer_Stop -> View_Illumination.rp_TmExt_Timer_Stop
    connect Ctrl_Illumination.pp_IllumCtrl_Op -> View_Illumination.rp_IllumCtrl_Op
    connect CCDD_EcuBatteryM.ppCS_EcuBatteryOutData -> View_Illumination.rp_CS_EcuBatteryOutData
    connect CBacklightCdd.pp_CS_Backlight_service -> View_Illumination.rp_CS_Backlight_service
    connect View_Illumination.pp_UCL_IlluminationData -> UclProxyCdd.rSR_IlluminationData
    connect CWarnMsg_Core_Observer.pp_HUDWarningDisplay -> UclProxyCdd.rSR_HudWarningDisplay
    connect CWarnMsg_Core_Observer.pp_TPMSWarnPayload -> UclProxyCdd.rSR_TpmsWarningData
    connect CWarnMsg_Core_Observer.pp_WarningDisplay -> UclProxyCdd.rSR_WarningDisplay
    connect Ctrl_WSS.pp_ClusterMode -> CView_Telltale.rp_ClusterMode
    connect Ctrl_WSS.ppIgnSubstate -> Mdl_Airbag.rpIgnSubstate
    connect Ctrl_WSS.pp_VehicleAppMode -> Mdl_Airbag.rp_VehicleAppMode
    connect CComAbsMdlSafe.pp_CS_RxCanMdlSafe -> Mdl_Airbag.rp_CS_CanAdapterRx
    connect Ctrl_WSS.pp_ClusterMode -> Mdl_Airbag.rp_ClusterMode
    connect CComAbsMdl.pp_CS_RxCanMdl -> Mdl_Airbag.rp_CS_CanRx
    connect Mdl_Airbag.pp_Airbag_TT_Status -> CView_Telltale.rpTelltlaeStatus_rp_Airbag_TT_Status
    connect Ctrl_WSS.pp_ClusterMode -> Mdl_TurnHazard.rp_ClusterMode
    connect IoHwAb.ppIoHwAb_Din -> Mdl_TurnHazard.rpCS_IoHwAbInp
    connect CComAbsMdl.pp_CS_RxCanMdl -> Mdl_TurnHazard.rp_CS_CanRx
    connect Mdl_TurnHazard.pp_TurnHazard_LeftInd_Sts -> CView_Telltale.rpTelltlaeStatus_rp_TurnHazard_LeftInd_Sts
    connect Mdl_TurnHazard.pp_TurnHazard_RightInd_Sts -> CView_Telltale.rpTelltlaeStatus_rp_TurnHazard_RightInd_Sts
    connect Ctrl_WSS.ppIgnSubstate -> CCtrl_Telltale.rpIgnSubstate
    connect Mdl_Airbag.pp_Airbag_TT_Status -> CCtrl_Telltale.rpTelltlaeStatus_rp_Airbag_TT_Status
    connect Mdl_TurnHazard.pp_TurnHazard_LeftInd_Sts -> CCtrl_Telltale.rpTelltlaeStatus_rp_TurnHazard_LeftInd_Sts
    connect Mdl_TurnHazard.pp_TurnHazard_RightInd_Sts -> CCtrl_Telltale.rpTelltlaeStatus_rp_TurnHazard_RightInd_Sts
    connect Ctrl_WSS.pp_ClusterMode -> CCtrl_Telltale.rp_ClusterMode
    connect Ctrl_WSS.pp_HMIReady -> CCtrl_Telltale.rpHmiReadyState
    connect CCDD_EcuBatteryM.ppCS_EcuBatteryOutData -> CCtrl_Telltale.rp_CS_EcuBatteryOutData
    connect CCtrl_Telltale.ppBlinkStatusArray -> CView_Telltale.rpBlinkStatusArray
    connect CCtrl_Telltale.ppTelltaleStatusOP -> CView_Telltale.rpTelltaleStatusOP
    connect Ctrl_WSS.pp_HMIReady -> CView_Telltale.rp_HMIReady
    connect CView_Telltale.ppTelltaleSts -> UclProxyCdd.rSR_TT_Status
    connect Ctrl_WSS.ppIgnSubstate -> FastGaugeAdapter.rpIgnSubstate
    connect Ctrl_WSS.pp_ClusterMode -> FastGaugeAdapter.rp_ClusterMode
    connect Ctrl_WSS.ppIgnSubstate -> View_Speed.rpIgnSubstate
    connect MemAbstractMdl.pp_CS_MemAbsGet -> View_Speed.rp_CS_MemAbsGet
    connect Ctrl_WSS.ppIgnSubstate -> Mdl_Speed.rpIgnSubstate
    connect MemAbstractMdl.pp_CS_MemAbsGet -> Mdl_Speed.rp_CS_MemAbsGet
    connect CComAbsMdlSafe.pp_CS_RxCanMdlSafe -> Mdl_Speed.rp_CS_CanRx
    connect Ctrl_WSS.pp_ClusterMode -> Mdl_Speed.rp_ClusterMode
    connect Mdl_Linear_Interpolation.pp_LinearInterpolateWord -> Mdl_Speed.rp_CS_LinerInterpolation
    connect IoHwAb.ppIoHwAb_ADC -> Mdl_Speed.rpIoHwAb_ADC
    connect Mdl_Speed.pp_SPD_SP1_In_Status -> View_Speed.rp_SPD_SP1_In_Status
    connect Mdl_Speed.pp_SPD_Target_Status -> View_Speed.rp_SPD_Target_Status
    connect Mdl_Speed.pp_SPD_Trim_Status -> View_Speed.rp_SPD_Trim_Status
    connect CComAbsMdlSafe.pp_CS_TxCanMdlSafe -> View_Speed.rp_CS_TxCanMdl
    connect CComAbsMdlSafe.pp_CS_RxCanMdlSafe -> View_Speed.rp_CS_RxCanMdl
    connect Ctrl_WSS.pp_ClusterMode -> View_Speed.rp_ClusterMode
    connect Mdl_Speed.pp_SPD_Target2_Status -> View_Speed.rp_SPD_Target2_Status
    connect Mdl_Speed.pp_SPD_Trim2_Status -> View_Speed.rp_SPD_Trim2_Status
    connect Mdl_Speed.pp_SPD_Selection_Table -> View_Speed.rp_SPD_Selection_Table
    connect View_Speed.pp_Display_speed_Value -> FastGaugeAdapter.rp_Display_speed_Value
    connect View_Speed.pp_SubDisplaySpeed_Value -> FastGaugeAdapter.rp_SubDisplaySpeed_Value
    connect Ctrl_WSS.ppIgnSubstate -> Mdl_Tacho.rpIgnSubstate
    connect CComAbsMdl.pp_CS_RxCanMdl -> Mdl_Tacho.rp_CS_RxCanMdl
    connect Ctrl_WSS.pp_ClusterMode -> Mdl_Tacho.rp_ClusterMode
    connect Mdl_Speed.pp_SPD_SP1_In_Status -> Mdl_Tacho.rp_SPD_SP1_In_Status
    connect Mdl_Tacho.pp_Analog_Tacho -> FastGaugeAdapter.rp_Analog_Tacho
    connect Mdl_Tacho.pp_Digital_Tacho -> FastGaugeAdapter.rp_Digital_Tacho
    connect Mdl_Tacho.pp_Needle_Transparent -> FastGaugeAdapter.rp_Needle_Transparent
    connect Mdl_Tacho.pp_Tacho_RED_Start_RPM -> FastGaugeAdapter.rp_Tacho_RED_Start_RPM
    connect Mdl_Tacho.pp_TC_Unit -> FastGaugeAdapter.rp_TC_Unit
    connect Mdl_Tacho.pp_Tacho_RPM_MAX -> FastGaugeAdapter.rp_Tacho_RPM_MAX
    connect Ctrl_WSS.pp_HMIReady -> FastGaugeAdapter.rp_HMIReadyState
    connect FastGaugeAdapter.pp_FastGaugeInfo -> UclProxyCdd.rSR_FastGaugeInfo
    connect Ctrl_WSS.ppIgnSubstate -> SlowGaugeAdapter.rpIgnSubstate
    connect Ctrl_WSS.pp_ClusterMode -> SlowGaugeAdapter.rp_ClusterMode
    connect Ctrl_WSS.pp_HMIReady -> SlowGaugeAdapter.rp_HMIReadyState
    connect SlowGaugeAdapter.pp_SlowGaugeInfo -> UclProxyCdd.rSR_SlowGaugeInfo
    connect UclProxyCdd.pSR_UpdateShortServiceResp -> CUpdateCdd.rp_SR_UpdateShortServiceResponse
    connect CUpdateCdd.pp_SR_UpdateShortServiceRequest -> UclProxyCdd.rSR_UpdateShortServiceReq
    connect CUpdateCdd.pp_SR_UpdateLongServiceRequest -> UclProxyCdd.rSR_UpdateLongServiceReq
    connect MemAbstractMdl.pp_CS_MemAbsGet -> DltExt.rp_CS_MemAbsGet
    connect MemAbstractMdl.pp_CS_MemAbsSet -> DltExt.rp_CS_MemAbsSet
    connect MemAbstractMdl.pp_CS_MemAbs_NvMWriteStatus -> DltExt.rp_CS_MemAbs_NvMWriteStatus
    connect UclProxyCdd.pSR_DLTControlMessageRequest -> DltExt.rSR_DLTControlMessageRequest
    connect UclProxyCdd.pSR_DLTMessageReadAck -> DltExt.rSR_DLTMessageReadAck
    connect DltExt.pSR_DLTMessageReadRequest -> UclProxyCdd.rSR_DLTMessageReadRequest
    connect DltExt.pSR_DLTControlMessageReponse -> UclProxyCdd.rSR_DLTControlMessageReponse
    connect UclProxyCdd.pSR_WarningStatus -> CWarnMsg_Core_Observer.rp_WarningStatus
    connect Mdl_Dim.pp_illumStarterstatus -> CWarnMsg_Core_Observer.rp_IllumStartSts
    connect Ctrl_WSS.pp_HMIReady -> CWarnMsg_Core_Observer.rp_HMIReadySts
    connect Ctrl_warning.ppWarnDisplayPayload -> CWarnMsg_Core_Observer.rp_UpdateDisplayPayload
    connect Ctrl_warning.ppActiveWarningStatus -> CWarnMsg_Core_Observer.rpActiveWarningStatus
    connect CComAbsMdl.pp_CS_TxCanMdl -> CWarnMsg_Core_Observer.rp_CS_TxCanMdl
    connect UclProxyCdd.pSR_HudWarningStatus -> CWarnMsg_Core_Observer.rp_HUDWarningStatus
    connect CWarnMsg_Core_Observer.pp_Init -> Ctrl_WSS.rp_Init_rp_Init_CWarnMsg_Core_Observer
    connect Ctrl_Illumination.pp_Init -> Ctrl_WSS.rp_Init_rp_Init_Ctrl_Illumination
    connect Ctrl_warning.pp_Init -> Ctrl_WSS.rp_Init_rp_Init_Ctrl_warning
    connect FastGaugeAdapter.pp_Init -> Ctrl_WSS.rp_Init_rp_Init_FastGaugeAdapter
    connect Mdl_Dim.pp_Init -> Ctrl_WSS.rp_Init_rp_Init_Mdl_Dim
    connect Mdl_Gear.pp_Init -> Ctrl_WSS.rp_Init_rp_Init_Mdl_Gear
    connect Mdl_Linear_Interpolation.pp_Init -> Ctrl_WSS.rp_Init_rp_Init_Mdl_Linear_Interpolation
    connect Mdl_Speed.pp_Init -> Ctrl_WSS.rp_Init_rp_Init_Mdl_Speed
    connect Mdl_Tacho.pp_Init -> Ctrl_WSS.rp_Init_rp_Init_Mdl_Tacho
    connect Mdl_TurnHazard.pp_Init -> Ctrl_WSS.rp_Init_rp_Init_Mdl_TurnHazard
    connect Ctrl_warning.ppCtrlWarningStatus -> Mdl_wAirbag.rpUpdateAirbagWarning
    connect Ctrl_WSS.ppIgnSubstate -> Mdl_wAirbag.rpIgnSubstate
    connect Ctrl_WSS.pp_ClusterMode -> Mdl_wAirbag.rp_ClusterMode
    connect CComAbsMdlSafe.pp_CS_RxCanMdlSafe -> Mdl_wAirbag.rp_CS_CanAdapterSafeRx
    connect Ctrl_WSS.pp_VehicleAppMode -> Mdl_wAirbag.rp_Vehiclestate
    connect Mdl_wAirbag.pp_Init -> Ctrl_WSS.rp_Init_rp_Init_Mdl_wAirbag
    connect Ctrl_warning.ppCtrlWarningStatus -> Mdl_wFuelLidOpen.rpUpdateFuelLidOpenWarning
    connect Ctrl_WSS.ppIgnSubstate -> Mdl_wFuelLidOpen.rpIgnSubstate
    connect CComAbsMdl.pp_CS_RxCanMdl -> Mdl_wFuelLidOpen.rp_CS_RxCanAdapterMdl
    connect Ctrl_WSS.pp_ClusterMode -> Mdl_wFuelLidOpen.rp_ClusterMode
    connect Mdl_wFuelLidOpen.pp_Init -> Ctrl_WSS.rp_Init_rp_Init_Mdl_wFuelLidOpen
    connect SlowGaugeAdapter.pp_Init -> Ctrl_WSS.rp_Init_rp_Init_SlowGaugeAdapter
    connect View_Speed.pp_Init -> Ctrl_WSS.rp_Init_rp_Init_View_Speed
    connect TmExt.pp_CS_TmExt_Timer_IsElapsed -> WarnMsg_Core_TmrSupport.rp_CS_TmExt_Timer_Elapsed
    connect TmExt.pp_CS_TmExt_Timer_Start -> WarnMsg_Core_TmrSupport.rp_CS_TmExt_Timer_Start
    connect TmExt.pp_CS_TmExt_Timer_IsStarted -> WarnMsg_Core_TmrSupport.rp_CS_TmExt_Timer_Started
    connect TmExt.pp_CS_TmExt_Timer_Stop -> WarnMsg_Core_TmrSupport.rp_CS_TmExt_Timer_Stop
    connect WarnMsg_Core_TmrSupport.pp_Init -> Ctrl_WSS.rp_Init_rp_Init_WarnMsg_Core_TmrSupport
    connect CComAbsMdl.pp_CS_RxCanMdl -> Ctrl_WSS.rp_CS_ComAbsRx
    connect MemAbstractMdl.pp_CS_MemAbs_NvMWriteStatus -> Ctrl_WSS.rp_CS_MemAbs_NvMWriteStatus
    connect NvMExt.pp_CS_NvMExt_GetNvMExtReadAllStatus -> Ctrl_WSS.rp_CS_NvMExt_GetNvMExtReadAllStatus
    connect NvMExt.ppSRPhasedRead_Status_phase1readcompleted -> Ctrl_WSS.rpSRPhasedRead_Status_phase1readcompleted
    connect NvMExt.ppSRPhasedRead_Status_phase2readcompleted -> Ctrl_WSS.rpSRPhasedRead_Status_phase2readcompleted
    connect Mdl_TurnHazard.pp_TurnHazard_TurnL_Sts -> Ctrl_WSS.rp_TurnHzdTurnL_Status
    connect Mdl_TurnHazard.pp_TurnHazard_TurnR_Sts -> Ctrl_WSS.rp_TurnHzdTurnR_Status
    connect Mdl_Gear.pp_ShiftPositionDisplay -> Ctrl_WSS.rp_ShiftPositionDisp
    connect CCtrl_Telltale.ppTelltaleStatusOP -> Ctrl_WSS.rpTelltaleStatusOP
    connect CCtrl_Telltale.ppBlinkStatusArray -> Ctrl_WSS.rp_BlinkStsArray
    connect UclProxyCdd.pSR_MainHMIReadyStatus -> Ctrl_WSS.rpUclHMIReadySts
    connect NvMExt.ppSRPhasedRead_Status_phase3readcompleted -> Ctrl_WSS.rpSRPhasedRead_Status_phase3readcompleted
    connect Ctrl_WSS.ppIgnSubstate -> Mdl_Dim.rpIgnSubstate
    connect Ctrl_WSS.pp_VehicleAppMode -> Mdl_Dim.rpVehicleAppMode
    connect Ctrl_WSS.pp_TFTDisplayOn -> Mdl_Dim.rp_TFTDisplayOn
    connect Ctrl_WSS.pp_Variant_status -> Mdl_Dim.rp_Variant_Status
    connect Ctrl_Illumination.pp_StopPwmUpdate -> Mdl_Dim.rp_StopPwmUpdate
    connect Ctrl_WSS.pp_AppMdl_Sleep -> Mdl_Dim.rp_ILL_ReadyToSleep
    connect CComAbsMdl.pp_CS_RxCanMdl -> Mdl_Dim.rp_CS_CanRx
    connect Ctrl_WSS.pp_ClusterMode -> Mdl_Dim.rp_ClusterMode
    connect IoHwAb.ppIoHwAb_Din -> Mdl_Dim.rpIoHwAb_Din
    assembly sw connector E40_Platform_System_CS_Mdl_Dimrp_CS_MemAbsSet_MemAbstractMdlpp_CS_MemAbsSet_if_CS_MemAbsSet: requester=Mdl_Dim.rp_CS_MemAbsSet
    assembly sw connector E40_Platform_System_CS_Mdl_Dimrp_CS_MemAbsGet_MemAbstractMdlpp_CS_MemAbsGet_if_CS_MemAbsGet: requester=Mdl_Dim.rp_CS_MemAbsGet
    connect Ctrl_warning.ppCtrlWarningStatus -> Mdl_Dim.rpUpdateDIMWarning
    connect MemAbstractMdl.pp_CS_MemAbsGet -> Mdl_Dim.rp_GetNVM_IlluminationData
    connect IoHwAb.ppIoHwAb_ADC -> Mdl_Dim.rp_IoHwAb_ADC
    connect Ctrl_Illumination.pp_IlumDayNightRequired -> Mdl_Dim.rp_IlumDayNightRequired
    connect Ctrl_Illumination.pp_IlumDayNightStatus -> Mdl_Dim.rp_IlumDayNightStatus
    connect Ctrl_Illumination.pp_Ctrl_Ready_to_Sleep -> Mdl_Dim.rp_Ctrl_Ready_to_Sleep
    connect MemAbstractMdl.pp_CS_MemAbsSet -> Mdl_Dim.rp_SetNVM_IlluminationData
    connect Mdl_Dim.pp_IlumStep -> Ctrl_Illumination.rp_IlumStep
    assembly sw connector E40_Platform_System_CS_Ctrl_Illuminationrp_GetNVM_IlluminationElement_MemAbstractMdlpp_CS_MemAbsGet_if_CS_MemAbsGet: requester=Ctrl_Illumination.rp_GetNVM_IlluminationElement
    connect MemAbstractMdl.pp_CS_MemAbsSet -> Ctrl_Illumination.rp_SetNVM_IlluminationElement
    connect IoHwAb.ppIoHwAb_Din -> Ctrl_Illumination.rpIoHwAb_Din
    connect Ctrl_WSS.pp_ClusterMode -> Ctrl_Illumination.rp_ClusterMode
    connect Ctrl_WSS.ppIgnSubstate -> Ctrl_Illumination.rpIgnSubstate
    connect Ctrl_WSS.pp_VehicleAppMode -> Ctrl_Illumination.rpVehicleAppMode
    connect CComAbsMdl.pp_CS_RxCanMdl -> Ctrl_Illumination.rp_CS_CanRx
    connect Mdl_Dim.pp_RheostatDayStep -> Ctrl_Illumination.rp_RheostatDayStep
    connect Mdl_Dim.pp_RheostatNightStep -> Ctrl_Illumination.rp_RheostatNightStep
    connect Mdl_Dim.pp_illum_rheostat_change -> Ctrl_Illumination.rp_Rheostat_Change
    connect Ctrl_WSS.pp_TFTDisplayOn -> Ctrl_Illumination.rp_TFTDisplayOn
    connect Ctrl_WSS.pp_AppMdl_Sleep -> Ctrl_Illumination.rp_ILL_ReadyToSleep
    connect MemAbstractMdl.pp_CS_MemAbsGet -> Ctrl_Illumination.rp_CS_MemAbsGet
    connect TmExt.pp_CS_TmExt_Timer_IsElapsed -> Ctrl_Illumination.rp_TmExt_Timer_IsElapsed
    connect TmExt.pp_CS_TmExt_Timer_IsStarted -> Ctrl_Illumination.rp_TmExt_Timer_IsStarted
    connect TmExt.pp_CS_TmExt_Timer_Start -> Ctrl_Illumination.rp_TmExt_Timer_Start
    connect TmExt.pp_CS_TmExt_Timer_Stop -> Ctrl_Illumination.rp_TmExt_Timer_Stop
    connect Mdl_Dim.pp_IllumCtrl_Ip -> Ctrl_Illumination.rp_IllumCtrl_Ip
    connect CCDD_EcuBatteryM.ppCS_EcuBatteryOutData -> Ctrl_Illumination.rp_CS_EcuBatteryOutData
    connect Ctrl_Illumination.pp_CmpLibCmd_CCtrl_Illumination -> EcuAppM.rp_CmpLibCmd_rp_CmpLibCmd_CCtrl_Illumination
    connect CCtrl_Telltale.pp_CmpLibCmd -> EcuAppM.rp_CmpLibCmd_rp_CmpLibCmd_CCtrl_Telltale
    connect DcmApp.pp_CmpLibCmd_CDcmApp -> EcuAppM.rp_CmpLibCmd_rp_CmpLibCmd_CDcmArp
    connect DemExt.pp_CS_DemExt_ClearDTC -> DemApp.rp_CS_DemExt_ClearDTC
    connect DemExt.pp_CS_DemExt_SetEventStatus -> DemApp.rp_CS_DemExt_SetEventStatus
    connect DemExt.pp_CS_DemExt_SetOperationCycleState -> DemApp.rp_CS_DemExt_SetOperationCycleState
    connect DemApp.pp_CmpLibCmd_CDemApp -> EcuAppM.rp_CmpLibCmd_rp_CmpLibCmd_CDemArp
    connect CBacklightCdd.pp_CS_Backlight_Status -> CDisplayCdd.rp_CS_Backlight_Status
    connect CBacklightCdd.pp_CS_Backlight_Notify -> CDisplayCdd.rp_CS_Backlight_Notify
    connect IoHwAb.ppIoHwAb_DOut -> CDisplayCdd.rpIoHwAb_SetDout
    connect UclProxyCdd.pSR_DisplayCurrentState -> CDisplayCdd.rpSRDisplayCurrentState
    connect CDisplayCdd.pp_CmpLibCmd_CDisplayCdd -> EcuAppM.rp_CmpLibCmd_rp_CmpLibCmd_CDisplayCdd
    connect DmnMgr.pp_CmpLibCmd_CDmnMgr -> EcuAppM.rp_CmpLibCmd_rp_CmpLibCmd_CDmnMgr
    connect EcuMExt.ppCS_EcumExt_GetResetReason -> Dlt.rpCS_EcumExt_GetResetReason
    connect Dlt.ppCS_Dlt_SendLogMessage -> CRstM.rp_CS_Dlt_SendLogMessage
    connect DltExt.ppCs_DltExt_GetResetInfo -> CRstM.rp_CS_DltExt_GetResetInfo
    connect CRstM.pp_CS_RstM_GetResetCount -> CFltM.rp_CS_RstM_GetResetCount
    connect CRstM.pp_CS_RstM_RequestSwReset -> CFltM.rp_CS_RstM_RequestSwReset
    connect CRstM.pp_CS_RstM_GetLastResetReason -> CFltM.rp_CS_RstM_GetLastResetReason
    connect DemExt.pp_CS_DemExt_SetEventStatus -> CFltM.rp_CS_DemExt_SetEventStatus
    connect CRstM.pp_CS_RstM_GetResetHistory -> CFltM.rp_CS_RstM_GetResetHistory
    connect CRstM.pp_CS_RstM_ClearResetHistory -> CFltM.rp_CS_RstM_ClearResetHistory
    connect Dlt.ppCS_Dlt_SendLogMessage -> CFltM.rp_CS_Dlt_SendLogMessage
    connect CFltM.pp_CmpLibCmd_CFltM -> EcuAppM.rp_CmpLibCmd_rp_CmpLibCmd_CFltM
    connect CFltM.pp_CS_FltM_ReportFault -> CFltMExt.rp_CS_FltM_ReportFault
    connect CCDD_EcuBatteryM.ppCS_EcuBatteryOutData -> CFltMExt.rp_CS_EcuBatteryOutData
    connect CFltMExt.pp_CmpLibCmd_CFltMExt -> EcuAppM.rp_CmpLibCmd_rp_CmpLibCmd_CFltMExt
    connect TmExt.pp_CS_TmExt_Timer_GetElapsedTime -> GdtCdd.rp_GdtCddTimer_getElapsedTime
    connect TmExt.pp_CS_TmExt_Timer_Start -> GdtCdd.rp_GdtCddTimer_Start
    connect TmExt.pp_CS_TmExt_Timer_Stop -> GdtCdd.rp_GdtTimerStop
    connect GdtCdd.pp_CmpLibCmd_CGdtCdd -> EcuAppM.rp_CmpLibCmd_rp_CmpLibCmd_CGdtCdd
    connect CIoExp.pp_CmpLibCmd_CIoExp -> EcuAppM.rp_CmpLibCmd_rp_CmpLibCmd_CIoExp
    connect CPmicCdd.pp_CmpLibCmd_CPmicCdd -> EcuAppM.rp_CmpLibCmd_rp_CmpLibCmd_CPmicCdd
    connect IoHwAb.ppIoHwAb_ADC -> RtcCdd.rp_CS_IoHwAb_ADC
    connect IoHwAb.ppIoHwAb_Din -> RtcCdd.rp_IoHwAb_Din
    connect IoHwAb.ppIoHwAb_DOut -> RtcCdd.rp_IoHwAb_DOut
    connect RtcCdd.pp_CmpLibCmd_CRTCCdd -> EcuAppM.rp_CmpLibCmd_rp_CmpLibCmd_CRTCCdd
    connect CRstM.pp_CmpLibCmd_CRstM -> EcuAppM.rp_CmpLibCmd_rp_CmpLibCmd_CRstM
    connect SafeNvM.pp_CmpLibCmd_CSafeNvM -> EcuAppM.rp_CmpLibCmd_rp_CmpLibCmd_CSafeNvM
    connect CSigCdd.pp_SigCddCrc -> CSwcDispMonSf.rp_SigCddCrc
    connect CSigCdd.pp_SigCddSts -> CSwcDispMonSf.rp_SigCddSts
    connect CSwcDispMonSf.pp_SigData -> CSigCdd.rp_SigData
    connect CSigCdd.pp_CmpLibCmd_CSigCdd -> EcuAppM.rp_CmpLibCmd_rp_CmpLibCmd_CSigCdd
    connect CSndCdd.pp_CmpLibCmd_CSndCdd -> EcuAppM.rp_CmpLibCmd_rp_CmpLibCmd_CSndCdd
    connect CSwcDispMonSf.pp_CmpLibCmd_CSwcDispMonSf -> EcuAppM.rp_CmpLibCmd_rp_CmpLibCmd_CSwcDispMonSf
    connect UclProxyCdd.pp_CmpLibCmd_CUclProxyCdd -> EcuAppM.rp_CmpLibCmd_rp_CmpLibCmd_CUclProxyCdd
    connect CUpdateCdd.pp_CmpLibCmd_CUpdateCdd -> EcuAppM.rp_CmpLibCmd_rp_CmpLibCmd_CUpdateCdd
    connect View_Illumination.pp_CmpLibCmd_CView_Illumination -> EcuAppM.rp_CmpLibCmd_rp_CmpLibCmd_CView_Illumination
    connect CView_Telltale.pp_CmpLibCmd -> EcuAppM.rp_CmpLibCmd_rp_CmpLibCmd_CView_Telltale
    connect CWarnMsg_Core_Observer.pp_CmpLibCmd -> EcuAppM.rp_CmpLibCmd_rp_CmpLibCmd_CWarnMsg_Core_Observer
    connect CorTst.pp_CmpLibCmd_CorTst -> EcuAppM.rp_CmpLibCmd_rp_CmpLibCmd_CorTst
    connect Ctrl_WSS.pp_CmpLibCmd -> EcuAppM.rp_CmpLibCmd_rp_CmpLibCmd_Ctrl_WSS
    connect FlsTst.pp_CmpLibCmd_FlsTst -> EcuAppM.rp_CmpLibCmd_rp_CmpLibCmd_FlsTst
    connect CMeetCdd.pp_CmpLibCmd_MeetCdd -> EcuAppM.rp_CmpLibCmd_rp_CmpLibCmd_MeetCdd
    connect MemAbstractMdl.pp_CmpLibCmd_MemAbstractMdl -> EcuAppM.rp_CmpLibCmd_rp_CmpLibCmd_MemAbstractMdl
    connect RamTst.pp_CmpLibCmd_RamTst -> EcuAppM.rp_CmpLibCmd_rp_CmpLibCmd_RamTst
    connect SysTst.pp_CmpLibCmd_SysTst -> EcuAppM.rp_CmpLibCmd_rp_CmpLibCmd_SysTst
    connect CBacklightCdd.pp_CS_Backlight_service -> EcuAppM.rp_CS_Backlight_service
    connect CCDD_EcuPowerM.ppCS_RequestPower -> EcuAppM.rpCS_RequestPower
    connect NvMExt.pp_CS_NvmExtStartReadAll -> EcuAppM.rp_CS_NvmExtStartReadAll
    connect NvMExt.pp_CS_NvMExt_SleepOperations -> EcuAppM.rp_CS_NvMExt_SleepOperations
    connect NvMExt.pp_CS_NvMExt_GetNvMExtReadAllStatus -> EcuAppM.rp_CS_NvMExt_GetNvMExtReadAllStatus
    connect EcuMExt.ppCS_EcumExt_ReleaseRUN -> EcuAppM.rpCS_EcumExt_ReleaseRUN
    connect EcuMExt.ppCS_EcumExt_RequestRUN -> EcuAppM.rpCS_EcumExt_RequestRUN
    connect Ctrl_WSS.pp_SleepOperation -> EcuAppM.rp_CS_SleepOperation
    connect Ctrl_WSS.pp_NotifySleepStatus -> EcuAppM.rp_NotifySleepStatus
    connect EcuAppM.ppCS_EcuAppM -> EcuMExt.rpCS_EcuAppM
    connect EcuMExt.ppCS_EcumExt_RequestRUN -> CCDD_BswFit.rpCS_EcumExt_RequestRUN
    connect CCDD_BswFit.ppCS_FitHandler -> CCDD_FitManager.rpCS_FitHandler_rpCS_FitHandler_CCDD_BswFit
    connect EcuMExt.ppCS_EcumExt_RequestRUN -> CCDD_McuFit.rpCS_EcumExt_RequestRUN
    connect CCDD_McuFit.ppCS_FitHandler -> CCDD_FitManager.rpCS_FitHandler_rpCS_FitHandler_CCDD_McuFit
    connect MemAbstractMdl.pp_SR_JobStatus -> DcmExt.rp_SR_JobStatus
    connect CMeetCdd.pp_CS_RID_DiagAction -> DcmExt.rp_CS_RID_DiagAction
    connect MemAbstractMdl.pp_CS_MemAbsSet -> DcmExt.rp_CS_MemAbsSet
    connect MemAbstractMdl.pp_CS_MemAbsGet -> DcmExt.rp_CS_MemAbsGet
    connect CMeetCdd.pp_CS_DID_DiagAction -> DcmExt.rp_CS_DID_DiagAction
    connect DcmApp.pp_CS_DID_App_Diag_Action -> DcmExt.rp_CS_DID_App_DiagAction
    connect DcmApp.pp_CS_RID_App_Diag_Action -> DcmExt.rp_CS_RID_App_DiagAction
    connect DcmApp.pp_CS_DiagEntryStatus -> DcmExt.rp_CS_DiagEntryStatus
    connect CUpdateCdd.pp_CS_UpdateCdd_GenericDIDRequestHandler -> DcmExt.rp_CS_UpdateCdd_DID_DiagAction
    connect CUpdateCdd.pp_CS_UpdateCdd_GenericRIDRequestHandler -> DcmExt.rp_CS_UpdateCdd_RID_DiagAction
    connect CUpdateCdd.pp_CS_UpdateCdd_GenericDownloadRequestHandler -> DcmExt.rp_CS_UpdateCdd_Service_0x34_Handler
    connect CUpdateCdd.pp_CS_UpdateCdd_GenericTransferDataHandler -> DcmExt.rp_CS_UpdateCdd_Service_0x36_Handler
    connect CUpdateCdd.pp_CS_UpdateCdd_GenericTransferExitHandler -> DcmExt.rp_CS_UpdateCdd_Service_0x37_Handler
    connect CUpdateCdd.pp_CS_UpdateCdd_GenericProgSessionRequest -> DcmExt.rp_CS_UpdateCdd_Service_0x10_Handler
    connect IoHwAb.ppIoHwAb_Din -> Mdl_SafetyAdapter.rp_IOHWab_Din
    connect IoHwAb.ppIoHwAb_ADC -> Mdl_SafetyAdapter.rp_IoHwAb_ADC
    connect ComMExt.ppComMExt -> Mdl_SafetyAdapter.rpComMExt
    connect Ctrl_WSS.pp_ClusterMode -> Mdl_SafetyAdapter.rp_ctrlwss_Clustermode
    connect CCtrl_Telltale.pp_Init -> Mdl_SafetyAdapter.rp_Init_rp_Init_CCtrl_Telltale
    connect CView_Telltale.pp_Init -> Mdl_SafetyAdapter.rp_Init_rp_Init_CView_Telltale
    connect Mdl_Airbag.pp_Init -> Mdl_SafetyAdapter.rp_Init_rp_Init_Mdl_Airbag
package /E40_Platform_System_SystemPackage/Types
  impl type EDisplayType: category=VALUE, base-type=uint8, compu {0=e_Display10Inch, 1=e_DisplayMaxDevice}, range raw 0..1
  impl type EDisplayPowerState: category=VALUE, base-type=uint8, compu {0=eDisplayIdle, 1=eDisplayPowerON, 2=eDisplayNormal, 3=eDisplayPowerOFF, 4=eDisplayFault_Handle, 5=eDisplayMaxPowerState}, range raw 0..5
  client server interface TI_Backlight_NotifyDispaly
    operation NotifyDisplayPowerState: possible-error=TI_Backlight_NotifyDispaly/E_NOT_OK
      arg DeviceId: implementation-data-type=EDisplayType, type=EDisplayType, direction=IN
      arg CompletedPowerState: implementation-data-type=EDisplayPowerState, type=EDisplayPowerState, direction=IN
    error E_NOT_OK: error-code=1
  impl type EDeviceStatus: category=VALUE, base-type=uint8, compu {0=eDeviceNotReady, 1=eDeviceInitialized, 2=eDeviceReady, 3=eDeviceBusy, 4=eDeviceFault, 5=eDeviceMaxState}, range raw 0..5
  client server interface TI_Backlight_Status
    operation GetStatus: possible-error=TI_Backlight_Status/E_NOT_OK
      arg DeviceName: implementation-data-type=EDisplayType, type=EDisplayType, direction=IN
      arg DeviceStatus: implementation-data-type=EDeviceStatus, type=EDeviceStatus, direction=OUT
    error E_NOT_OK: error-code=1
  client server interface TI_Backlight_Service
    operation GetBrightnessValue: possible-error=TI_Backlight_Service/E_NOT_OK
      arg DeviceName: implementation-data-type=EDisplayType, type=EDisplayType, direction=IN
      arg BrightnessPercentValue: implementation-data-type=UInt16, type=UInt16, direction=OUT
    operation GetThermalValue: possible-error=TI_Backlight_Service/E_NOT_OK
      arg DeviceName: implementation-data-type=EDisplayType, type=EDisplayType, direction=IN
      arg TempValueInMilliCelsius: implementation-data-type=UInt32, type=UInt32, direction=OUT
    operation SetBrightnessValue: possible-error=TI_Backlight_Service/E_NOT_OK
      arg DeviceName: implementation-data-type=EDisplayType, type=EDisplayType, direction=IN
      arg BrightnessPercentValue: implementation-data-type=UInt16, type=UInt16, direction=IN
    error E_NOT_OK: error-code=1
  impl type ECmpCmd: category=VALUE, base-type=uint8, compu {0=eCmpCmd_Init, 1=eCmpCmd_DeInit, 2=eCmpCmd_Activate, 3=eCmpCmd_DeActivate}, range raw 0..3
  client server interface if_CS_ModeOnCommand
    operation Impl_OnCommand: possible-error=if_CS_ModeOnCommand/E_NOT_OK
      arg cmdP: implementation-data-type=ECmpCmd, type=ECmpCmd, direction=IN
    error E_NOT_OK: error-code=1
  impl type IoHwAb_DOutGroupIdType: category=VALUE, base-type=sint32, compu {0=eIO_DOutGroupIdCount}, range raw -2147483647..2147483647
  impl type IoHwAb_ErrorType: category=VALUE, base-type=uint8, compu {2=E_NO_ERROR, 3=E_ERROR, 4=E_ADC_ERROR, 5=E_DOUT_ID_INVALID, 6=E_DIN_ID_INVALID, 7=E_ADC_ID_INVALID, 8=IOHWAB_E_ADC_ERROR, 9=IOHWAB_E_ADC_ID_INVALID, 10=IOHWAB_E_ERROR, 11=IOHWAB_E_DOUT_ID_INVALID, 12=IOHWAB_E_NO_ERROR, 13=IOHWAB_E_DIN_ID_INVALID}, range raw 2..13
  impl type IoHwAb_DOutSignalIdType:
    category=VALUE
    base-type=uint8
    compu {0=eIO_DOUT_DO_5VSW2_3V3_EN, 1=eIO_DOUT_PARK_BRAKE_TT_OUT, 2=eIO_DOUT_DO_SYC1, 3=eIO_DOUT_SEAT_BELT_TT_MCUOUT, 4=eIO_DOUT_TURN_LEFT_TT_MCUOUT, 5=eIO_DOUT_DO_LCD_BL_PWR_EN, 6=eIO_DOUT_DO_3V3_DISP_SW_EN, 7=eIO_DOUT_AMP_SHTD, 8=eIO_DOUT_FUEL_RHEO_SUP_EN, 9=eIO_DOUT_DO_LCD_STBYB, 10=eIO_DOUT_SBATT2_EN, 11=eIO_DOUT_BRAKE_TT_MCUOUT, 12=eIO_DOUT_AIRBAG_TT_MCUOUT, 13=eIO_DOUT_TURN_RIGHT_TT_MCUOUT, 14=eIO_DOUT_DO_SMPS_5V_SW_EN, 15=eIO_DOUT_PCS_OFF_TT_MCUOUT, 16=eIO_DOUT_ABS_TT_MCUOUT, 17=eIO_DOUT_SLIP_TT_MCUOUT, 18=eIO_DOUT_VCS_OFF_TT_MCUOUT, 19=eIO_DOUT_ECB_EPB_TT_MCUOUT, 20=eIO_DOUT_Flasher_FL_RL_OUT, 21=eIO_DOUT_Flasher_DEN1, 22=eIO_DOUT_Flasher_DSEL1, 23=eIO_DOUT_Flasher_FR_RR_OUT, 24=eIO_DOUT_DO_LCD_RST, 25=eIO_DOUT_DO_SMPS_1V2_EN, 26=eIO_DO_MAX, 27=eIO_DOUT_DO_DISP_RESET, 28=eIO_DOUT_DO_DISP_STBY, 29=eIO_DOUT_DO_TFT_BL_EN, 30=eIO_DOUT_DO_PWM_DIMMING, 31=eIO_DOUT_DO_RTC_INTN, 32=eIO_DOUT_DO_SOC_PWR_LATCH, 33=eIO_DOUT_DO_1V2_EN, 34=eIO_DOUT_DO_EN_5V, 35=eIO_DOUT_DO_ENET_EN, 36=eIO_DOUT_DO_LIN_NSLP, 37=eIO_DOUT_DO_MCU_RESETSTAZ, 38=eIO_DOUT_DO_3V3_DISP, 39=eIO_DOUT_DO_MD_TOUCH_RST, 40=eIO_DOUT_DO_VPP_EN, 41=eIO_DOUT_DO_MD_GNSS_BOOT_EN, 42=eIO_DOUT_DO_MD_GNSS_RESETP, 43=eIO_DOUT_DO_MD_GNSS_PWR_EN, 44=eIO_DOUT_DO_BLU_OPAMP_PWR_EN, 45=eIO_DOUT_DO_BLU_DWALED_EN, 46=eIO_DOUT_DO_TCON_BYPASS_MODE, 47=eIO_DOUT_DO_TCON_BYPASS_SEL0, 48=eIO_DOUT_DO_TCON_BYPASS_SEL1, 49=eIO_DOUT_DO_SOC_FPDLINK3_PDB, 50=eIO_DOUT_DO_SOC_FPDLINK3_INTB, 51=eIO_DOUT_DO_SOC_FPDLINK3_BISTEN, 52=eIO_DOUT_DO_ENET_RSTB, 53=eIO_DOUT_DO_EN_BUCK_FALD, 54=eIO_DOUT_DO_MCU_AMUX_S1, 55=eIO_DOUT_DO_MCU_AMUX_S0, 56=eIO_DOUT_DO_TCON_SPI0_CS0, 57=eIO_DOUT_DO_SPI_CAN_CS, 58=eIO_DOUT_DESER_SPI1_DO, 59=eIO_DOUT_DO_SOC_TCON_GRBN, 60=eIO_DOUT_DO_TFT_CSB}
    range raw 0..60
  client server interface TI_IOHWAB_SetDout
    operation SetOutputGroup: possible-error=TI_IOHWAB_SetDout/E_NOT_OK
      arg InputId: implementation-data-type=IoHwAb_DOutGroupIdType, type=IoHwAb_DOutGroupIdType, direction=IN
      arg OutputGroup: implementation-data-type=UInt32, type=UInt32, direction=IN
      arg ErrorStatus: implementation-data-type=IoHwAb_ErrorType, type=IoHwAb_ErrorType, direction=OUT
    operation SetOutputPin: possible-error=TI_IOHWAB_SetDout/E_NOT_OK
      arg InputId: implementation-data-type=IoHwAb_DOutSignalIdType, type=IoHwAb_DOutSignalIdType, direction=IN
      arg OutputSignal: implementation-data-type=Boolean, type=Boolean, direction=IN
      arg ErrorStatus: implementation-data-type=IoHwAb_ErrorType, type=IoHwAb_ErrorType, direction=OUT
    error E_NOT_OK: error-code=1
  impl type IoHwAb_DInSignalIdType:
    category=VALUE
    base-type=uint8
    compu {0=eIO_DIN_DI_AL_HAZARD, 1=eIO_DIN_DI_AH_IGNITION, 2=eIO_DIN_DI_SMPS_3V3_PG, 3=eIO_DIN_STOP_LAMP_MCU, 4=eIO_DIN_DI_AL_BRAKE_LEVEL, 5=eIO_DIN_DI_AL_OIL_W, 6=eIO_DIN_DI_AL_DRV_SEAT_BUCKLE, 7=eIO_DIN_DI_AL_WASHER_LEVEL_SW, 8=eIO_DIN_ODO_TripKnobInput, 9=eIO_DIN_DI_AL_VACUUM, 10=eIO_DIN_DI_LCD_BL_PWR_FAULT, 11=eIO_DIN_DI_AL_FUEL_LID_EFI_ECU, 12=eIO_DIN_DI_TT_SHIFT_ERR, 13=eIO_DIN_MAX, 14=eIO_DIN_DI_PMIC_INTN, 15=eIO_DIN_DI_MCU_PORZ, 16=eIO_DIN_DI_SBATT2_ERR, 17=eIO_DIN_DI_FALD_PG, 18=eIO_DIN_DI_MD_TOUCH_INTN, 19=eIO_DIN_DI_BL_FAULT, 20=eIO_DIN_DI_SOC_FPDLINK3_LOCK, 21=eIO_DIN_DI_SOC_FPDLINK3_PASS, 22=eIO_DIN_DI_ENET_MII_INT, 23=eIO_DIN_DI_IGN_MON, 24=eIO_DIN_DI_CABLE_DETECT, 25=eIO_DIN_DI_TCON_IND_OUT, 26=eIO_DIN_DI_SPI_CAN_TCON_SDI, 27=eIO_DIN_DI_MCU_FALD_CONN_CHK, 28=eIO_DIN_DI_LDO_1V2_FAULTN, 29=eIO_DIN_DI_TFT_ER_DET}
    range raw 0..29
  impl type IoHwAb_DInGroupIdType: category=VALUE, base-type=sint32, compu {0=eIO_DInGroupIdCount}, range raw -2147483647..2147483647
  client server interface TI_IOHWAB_GetDIn
    4 x operation, all with possible-error=TI_IOHWAB_GetDIn/E_NOT_OK:
      GetAsyncRawInput
        arg InputId: implementation-data-type=IoHwAb_DInSignalIdType, type=IoHwAb_DInSignalIdType, direction=IN
        arg AsyncInput: implementation-data-type=Boolean, type=Boolean, direction=OUT
        arg ErrorStatus: implementation-data-type=IoHwAb_ErrorType, type=IoHwAb_ErrorType, direction=OUT
      GetInputGroup
        arg InputId: implementation-data-type=IoHwAb_DInGroupIdType, type=IoHwAb_DInGroupIdType, direction=IN
        arg SyncInput: implementation-data-type=UInt32, type=UInt32, direction=OUT
        arg ErrorStatus: implementation-data-type=IoHwAb_ErrorType, type=IoHwAb_ErrorType, direction=OUT
      GetProcessedInput
        arg InputId: implementation-data-type=IoHwAb_DInSignalIdType, type=IoHwAb_DInSignalIdType, direction=IN
        arg InputSignal: implementation-data-type=Boolean, type=Boolean, direction=OUT
        arg ErrorStatus: implementation-data-type=IoHwAb_ErrorType, type=IoHwAb_ErrorType, direction=OUT
      GetSyncRawInput
        arg InputId: implementation-data-type=IoHwAb_DInSignalIdType, type=IoHwAb_DInSignalIdType, direction=IN
        arg SyncInput: implementation-data-type=Boolean, type=Boolean, direction=OUT
        arg ErrorStatus: implementation-data-type=IoHwAb_ErrorType, type=IoHwAb_ErrorType, direction=OUT
    error E_NOT_OK: error-code=1
  impl type IoHwAb_PwmSignalIdType: category=VALUE, base-type=uint8, compu {0=eIO_PWM_MCU_BUZZER_AMPLCTRL, 1=eIO_PWM_HIGH_BEAM_TT_MCUOUT, 2=eIO_PWM_FUEL_TEMP_GAUG_TEXT_PWM_OUT, 3=eIO_PWM_PWM_OUT_ILL2, 4=eIO_PWM_PWM_OUT_ILL1, 5=eIO_PWM_BG_Dimming_PWM, 6=eIO_PWM_PWM_GREEN_TT_DIMMING, 7=eIO_PWM_CXPI_CLK, 8=eIO_PWM_PWM_LCD_BL_DIMMING, 9=eIO_PWM_MAX}, range raw 0..9
  client server interface TI_IOHWAB_PWM
    operation PwmSetDuty: possible-error=TI_IOHWAB_PWM/E_NOT_OK
      arg PwmId: implementation-data-type=IoHwAb_PwmSignalIdType, type=IoHwAb_PwmSignalIdType, direction=IN
      arg Pwm_Duty: implementation-data-type=UInt16, type=UInt16, direction=IN
      arg ErrorStatus: implementation-data-type=IoHwAb_ErrorType, type=IoHwAb_ErrorType, direction=OUT
    operation PwmSetDutyAndPeriod: possible-error=TI_IOHWAB_PWM/E_NOT_OK
      4 x arg:
        PwmId: implementation-data-type=IoHwAb_PwmSignalIdType, type=IoHwAb_PwmSignalIdType, direction=IN
        Pwm_Period: implementation-data-type=UInt32, type=UInt32, direction=IN
        Pwm_Duty: implementation-data-type=UInt16, type=UInt16, direction=IN
        ErrorStatus: implementation-data-type=IoHwAb_ErrorType, type=IoHwAb_ErrorType, direction=OUT
    operation PwmSetIdeal: possible-error=TI_IOHWAB_PWM/E_NOT_OK
      arg PwmId: implementation-data-type=IoHwAb_PwmSignalIdType, type=IoHwAb_PwmSignalIdType, direction=IN
      arg ErrorStatus: implementation-data-type=IoHwAb_ErrorType, type=IoHwAb_ErrorType, direction=OUT
    error E_NOT_OK: error-code=1
  impl type IoHwAb_AdcSignalIdType:
    category=VALUE
    base-type=uint8
    compu {16=eIO_ADC_ADC_FUEL_5V_MON, 17=eIO_ADC_ADC_FUEL_MAIN, 2=eIO_ADC_IGN_AD, 3=eIO_ADC_FUEL_SEND_SUB_MICRO_AD, 4=eIO_ADC_AI_BATTERY, 5=eIO_ADC_AI_LCD_NTC, 6=eIO_ADC_AI_TEMP_RTC, 7=eIO_ADC_Flasher_Diag_sense_1, 8=eIO_ADC_STR_SW2_ADIN, 9=eIO_ADC_STR_SW1_ADIN, 10=eIO_ADC_RHEO_SW_IN_ADIN, 11=eIO_ADC_ADC_RHEO_5V_MON_ADIN, 12=eIO_ADC_Flasher_Diag_sense_2, 13=eIO_ADC_AdcChannel_Vdb, 14=eIO_ADC_AdcChannel_Vtemp, 15=eIO_ADC_MAX, 0=eIO_ADC_AI_SAMPLE_1, 1=eIO_ADC_AI_SAMPLE_2}
    range raw 0..17
  client server interface TI_IOHWAB_GetAdc
    operation GetAsyncRawAdc: possible-error=TI_IOHWAB_GetAdc/E_NOT_OK
      arg AdcId: implementation-data-type=IoHwAb_AdcSignalIdType, type=IoHwAb_AdcSignalIdType, direction=IN
      arg AsyncRawAdc: implementation-data-type=UInt16, type=UInt16, direction=OUT
      arg ErrorStatus: implementation-data-type=IoHwAb_ErrorType, type=IoHwAb_ErrorType, direction=OUT
    operation GetProcessedAdc: possible-error=TI_IOHWAB_GetAdc/E_NOT_OK
      arg AdcId: implementation-data-type=IoHwAb_AdcSignalIdType, type=IoHwAb_AdcSignalIdType, direction=IN
      arg ProcessedAdc: implementation-data-type=SInt32, type=SInt32, direction=OUT
      arg ErrorStatus: implementation-data-type=IoHwAb_ErrorType, type=IoHwAb_ErrorType, direction=OUT
    operation GetSyncRawAdc: possible-error=TI_IOHWAB_GetAdc/E_NOT_OK
      arg AdcId: implementation-data-type=IoHwAb_AdcSignalIdType, type=IoHwAb_AdcSignalIdType, direction=IN
      arg SyncRawAdc: implementation-data-type=UInt16, type=UInt16, direction=OUT
      arg ErrorStatus: implementation-data-type=IoHwAb_ErrorType, type=IoHwAb_ErrorType, direction=OUT
    error E_NOT_OK: error-code=1
  impl type eIOPulseInputId: category=VALUE, base-type=sint32, compu {0=eIOPulseInputIdCount}, range raw -2147483647..2147483647
  impl type SPulseInputConfigParam: category=STRUCTURE
    16 x element, all with category=TYPE_REFERENCE:
      MissingRecoveryTimeoutInMicroSec: implementation-data-type=UInt32
      ValidPeriodMinInMicroSec: implementation-data-type=UInt32
      ValidPeriodMaxInMicroSec: implementation-data-type=UInt32
      HystLimitForPeriodMinInMicroSec: implementation-data-type=UInt32
      HystRcvryForPeriodMinInMicroSec: implementation-data-type=UInt32
      HystLimitForPeriodMaxInMicroSec: implementation-data-type=UInt32
      HystRcvryForPeriodMaxInMicroSec: implementation-data-type=UInt32
      ValidDutyMinInPercentage: implementation-data-type=UInt16
      ValidDutyMaxInPercentage: implementation-data-type=UInt16
      HystLimitForDutyMinInPercentage: implementation-data-type=UInt16
      HystRcvryForDutyMinInPercentage: implementation-data-type=UInt16
      HystLimitForDutyMaxInPercentage: implementation-data-type=UInt16
      HystRcvryForDutyMaxInPercentage: implementation-data-type=UInt16
      InValidTimeoutInMilliSec: implementation-data-type=UInt16
      InValidRecoveryTimeoutInMilliSec: implementation-data-type=UInt16
      MissingTimeoutInMilliSec: implementation-data-type=UInt16
  impl type SSpeedCalcParam: category=STRUCTURE
    element Pulses_Per_Revolution: implementation-data-type=UInt32
    element Revolutions_Per_Unit: implementation-data-type=UInt32
    element Tuning_Factor: implementation-data-type=UInt32
  client server interface TI_IOHWAB_Pulse
    7 x operation, all with possible-error=TI_IOHWAB_Pulse/E_NOT_OK:
      GetCurrentSignalStatus_PulseInput
        arg PulseInputId: implementation-data-type=eIOPulseInputId, type=eIOPulseInputId, direction=IN
        arg SignalStatus: implementation-data-type=UInt16, type=UInt16, direction=OUT
        arg ErrorStatus: implementation-data-type=IoHwAb_ErrorType, type=IoHwAb_ErrorType, direction=OUT
      GetCurrentSpeed_PulseInput
        arg PulseInputId: implementation-data-type=eIOPulseInputId, type=eIOPulseInputId, direction=IN
        arg SpeedVal: implementation-data-type=UInt32, type=UInt32, direction=OUT
        arg ErrorStatus: implementation-data-type=IoHwAb_ErrorType, type=IoHwAb_ErrorType, direction=OUT
      GetRollingCount_PulseInput
        arg PulseInputId: implementation-data-type=eIOPulseInputId, type=eIOPulseInputId, direction=IN
        arg EdgeCount: implementation-data-type=DataTypes/UInt8, type=DataTypes/UInt8, direction=OUT
        arg ErrorStatus: implementation-data-type=IoHwAb_ErrorType, type=IoHwAb_ErrorType, direction=OUT
      ResetRollingCount_PulseInput
        arg PulseInputId: implementation-data-type=eIOPulseInputId, type=eIOPulseInputId, direction=IN
        arg ErrorStatus: implementation-data-type=IoHwAb_ErrorType, type=IoHwAb_ErrorType, direction=OUT
      Start_Signal_Measurement_PulseInput
        4 x arg:
          PulseInputId: implementation-data-type=eIOPulseInputId, type=eIOPulseInputId, direction=IN
          PulseInputChnlCfgParam: implementation-data-type=SPulseInputConfigParam, type=SPulseInputConfigParam, direction=OUT
          SpdCalParam: implementation-data-type=SSpeedCalcParam, type=SSpeedCalcParam, direction=OUT
          ErrorStatus: implementation-data-type=IoHwAb_ErrorType, type=IoHwAb_ErrorType, direction=OUT
      Stop_Signal_Measurement_PulseInput
        arg PulseInputId: implementation-data-type=eIOPulseInputId, type=eIOPulseInputId, direction=IN
        arg ErrorStatus: implementation-data-type=IoHwAb_ErrorType, type=IoHwAb_ErrorType, direction=OUT
      Update_CalibParam_PulseInput
        arg PulseInputId: implementation-data-type=eIOPulseInputId, type=eIOPulseInputId, direction=IN
        arg SpdCalParam: implementation-data-type=SSpeedCalcParam, type=SSpeedCalcParam, direction=OUT
        arg ErrorStatus: implementation-data-type=IoHwAb_ErrorType, type=IoHwAb_ErrorType, direction=OUT
    error E_NOT_OK: error-code=1
  client server interface TI_FaultInjectionHandler
    operation FaultInjectionHandler: possible-error=TI_FaultInjectionHandler/E_NOT_OK
      arg StartStopData: implementation-data-type=DataTypes/UInt8, type=DataTypes/UInt8, direction=IN
      arg TestListID: implementation-data-type=DataTypes/UInt8, type=DataTypes/UInt8, direction=IN
      arg Data: implementation-data-type=DataTypes/UInt8, type=DataTypes/UInt8, direction=OUT
    error E_NOT_OK: error-code=1
  impl type EcuM_UserType: category=VALUE, base-type=uint8, range raw 0..255
  12 x client server interface:
    TI_EcuMExt_RequestRUN
      operation RequestRUN: possible-error=TI_EcuMExt_RequestRUN/E_NOT_OK
        arg user: implementation-data-type=EcuM_UserType, type=EcuM_UserType, direction=IN
      error E_NOT_OK: error-code=1
    TI_EcuMExt_GetResetReason
      operation GetResetReason: possible-error=TI_EcuMExt_GetResetReason/E_NOT_OK
      error E_NOT_OK: error-code=1
    TI_EcuMExt_ReleaseRUN
      operation ReleaseRUN: possible-error=TI_EcuMExt_ReleaseRUN/E_NOT_OK
        arg user: implementation-data-type=EcuM_UserType, type=EcuM_UserType, direction=IN
      error E_NOT_OK: error-code=1
    if_CS_EcuAppM
      operation EcuAppM_SetWakeupSources
        arg WakeupSource: implementation-data-type=UInt32, type=UInt32, direction=IN
      operation Init
    TI_EcuPowerM
      operation EcuPowerM_GetDeviceStatus: possible-error=TI_EcuPowerM/E_NOT_OK
        arg device: implementation-data-type=DataTypes/UInt8, type=DataTypes/UInt8, direction=IN
        arg status: implementation-data-type=DataTypes/UInt8, type=DataTypes/UInt8, direction=OUT
      operation EcuPowerM_RequestPower: possible-error=TI_EcuPowerM/E_NOT_OK
        arg device: implementation-data-type=DataTypes/UInt8, type=DataTypes/UInt8, direction=IN
        arg request: implementation-data-type=DataTypes/UInt8, type=DataTypes/UInt8, direction=IN
      error E_NOT_OK: error-code=1
    TI_NvMExt_GetReadAllStatus
      operation NvmExt_GetNvMReadAllStatus
        arg Status: implementation-data-type=Boolean, type=Boolean, direction=OUT
    TI_NvMExt_SleepOperations
      operation NvMExt_CancelSleep: possible-error=TI_NvMExt_SleepOperations/E_NOT_OK
      operation NvMExt_ReadytoSleep: possible-error=TI_NvMExt_SleepOperations/E_NOT_OK
      operation NvMExt_RequestSleep: possible-error=TI_NvMExt_SleepOperations/E_NOT_OK
      error E_NOT_OK: error-code=1
    TI_NvmExt_StartNvmReadAll
      operation NvMExt_ReadAll
    TI_WSS_SleepOperations
      operation CtrlWSS_CancelSleep: possible-error=TI_WSS_SleepOperations/E_NOT_OK
      operation CtrlWSS_ReadytoSleep: possible-error=TI_WSS_SleepOperations/E_NOT_OK
      operation CtrlWSS_RequestSleep: possible-error=TI_WSS_SleepOperations/E_NOT_OK
      error E_NOT_OK: error-code=1
    TI_WSS_SWCNotifySleepStatus
      operation CtrlWSS_NotifyNetworkSleep: possible-error=TI_WSS_SWCNotifySleepStatus/E_NOT_OK
        arg NotifyStatus: implementation-data-type=DataTypes/UInt8, type=DataTypes/UInt8, direction=OUT
      error E_NOT_OK: error-code=1
    TI_EcuBatteryMData
      operation EcuBatteryM_GetChannelStatus: possible-error=TI_EcuBatteryMData/E_NOT_OK
        arg Channel: implementation-data-type=DataTypes/UInt8, type=DataTypes/UInt8, direction=IN
        arg Status: implementation-data-type=DataTypes/UInt8, type=DataTypes/UInt8, direction=OUT
      operation EcuBatteryM_GetDIOStatus: possible-error=TI_EcuBatteryMData/E_NOT_OK
        arg InputId: implementation-data-type=DataTypes/UInt8, type=DataTypes/UInt8, direction=IN
        arg Status: implementation-data-type=DataTypes/UInt8, type=DataTypes/UInt8, direction=OUT
      error E_NOT_OK: error-code=1
    TI_ComMExt
      13 x operation:
        CAN_ActivateSilentCommunication: possible-error=TI_ComMExt/E_NOT_OK
          arg Channel: implementation-data-type=DataTypes/UInt8, type=DataTypes/UInt8, direction=IN
        CAN_CommControlActivateRx: possible-error=TI_ComMExt/E_NOT_OK
          arg Channel: implementation-data-type=DataTypes/UInt8, type=DataTypes/UInt8, direction=IN
        CAN_CommControlActivateTx: possible-error=TI_ComMExt/E_NOT_OK
          arg Channel: implementation-data-type=DataTypes/UInt8, type=DataTypes/UInt8, direction=IN
        CAN_CommControlDeActivateRx: possible-error=TI_ComMExt/E_NOT_OK
          arg Channel: implementation-data-type=DataTypes/UInt8, type=DataTypes/UInt8, direction=IN
        CAN_CommControlDeActivateTx: possible-error=TI_ComMExt/E_NOT_OK
          arg Channel: implementation-data-type=DataTypes/UInt8, type=DataTypes/UInt8, direction=IN
        CAN_CommControlSetDone
          arg PduInitRequest: implementation-data-type=Boolean, type=Boolean, direction=IN
        CAN_DeActivateSilentCommunication: possible-error=TI_ComMExt/E_NOT_OK
          arg Channel: implementation-data-type=DataTypes/UInt8, type=DataTypes/UInt8, direction=IN
        CAN_GetCurrentComMode: possible-error=TI_ComMExt/E_NOT_OK
          arg Channel: implementation-data-type=DataTypes/UInt8, type=DataTypes/UInt8, direction=IN
          arg ComMode: implementation-data-type=DataTypes/UInt8, type=DataTypes/UInt8, direction=OUT
        CAN_ReleaseCommunication: possible-error=TI_ComMExt/E_NOT_OK
          arg Channel: implementation-data-type=DataTypes/UInt8, type=DataTypes/UInt8, direction=IN
        CAN_RequestCommunication: possible-error=TI_ComMExt/E_NOT_OK
          arg Channel: implementation-data-type=DataTypes/UInt8, type=DataTypes/UInt8, direction=IN
        GetBusOffStatus: possible-error=TI_ComMExt/E_NOT_OK
          arg Channel: implementation-data-type=DataTypes/UInt8, type=DataTypes/UInt8, direction=IN
          arg BusOffStatus: implementation-data-type=Boolean, type=Boolean, direction=OUT
        Get_MCAN_ERR_PIN_Status: possible-error=TI_ComMExt/E_NOT_OK
          arg fl_pin_status_BOOL: implementation-data-type=Boolean, type=Boolean, direction=OUT
        Init
      error E_NOT_OK: error-code=1
  impl type tRxSignalId: category=VALUE, base-type=uint8, compu {0=eDayNightModeIn, 1=eIllumination_levelIn, 2=eAmbient_Light_levelIn, 3=ePowerModeIn, 4=eTransportModeIn, 5=eGearModeIn, 6=eGearRecommendationIn, 7=eGearIn, 8=eWarningIn, 9=eGearStatusIn, 10=eEngineSpeedIn, 11=eTurn_Indicator_ControlIn, 12=eEndOfRxSignal}, range raw 0..12
  impl type tRxSignalStatus: category=VALUE, base-type=uint8, compu {0=eSIGNAL_OK, 1=eSIGNAL_MISSING, 2=eSIGNAL_NEVER_RECEIVED, 4=eSIGNAL_INVALID}, range raw 0..4
  impl type tRxSignalJustRcvdStatus: category=VALUE, base-type=uint8, compu {0=eJust_Received, 1=eNot_Just_Received}, range raw 0..1
  client server interface if_CS_ComAbsRx
    9 x operation:
      RxCan_GetSignalValue: possible-error=if_CS_ComAbsRx/E_NOT_OK
        arg SignalId: implementation-data-type=tRxSignalId, type=tRxSignalId, direction=IN
        arg pSignalValue: implementation-data-type=DataTypes/UInt8, type=DataTypes/UInt8, direction=OUT
        arg pSignalStatus: implementation-data-type=tRxSignalStatus, type=tRxSignalStatus, direction=OUT
      RxCan_GetSignalValueU8Arr: possible-error=if_CS_ComAbsRx/E_NOT_OK
        4 x arg:
          SignalId: implementation-data-type=tRxSignalId, type=tRxSignalId, direction=IN
          pSignalValue: implementation-data-type=DataTypes/UInt8, type=DataTypes/UInt8, direction=OUT
          pSignalStatus: implementation-data-type=tRxSignalStatus, type=tRxSignalStatus, direction=OUT
          pSignalLength: implementation-data-type=UInt32, type=UInt32, direction=OUT
      RxCan_SetSignalInitValue: possible-error=if_CS_ComAbsRx/E_NOT_OK
        arg SignalId: implementation-data-type=tRxSignalId, type=tRxSignalId, direction=IN
        arg pSignalValue: implementation-data-type=DataTypes/UInt8, type=DataTypes/UInt8, direction=OUT
      RxCan_SetSignalInitValueU8Arr: possible-error=if_CS_ComAbsRx/E_NOT_OK
        arg SignalId: implementation-data-type=tRxSignalId, type=tRxSignalId, direction=IN
        arg pSignaValue: implementation-data-type=DataTypes/UInt8, type=DataTypes/UInt8, direction=OUT
        arg pSignalLength: implementation-data-type=UInt32, type=UInt32, direction=OUT
      RxCan_SignalClearJustRcvdStatus
        arg SignalId: implementation-data-type=tRxSignalId, type=tRxSignalId, direction=IN
      RxCan_SignalGetJustRcvdStatus
        arg SignalId: implementation-data-type=tRxSignalId, type=tRxSignalId, direction=IN
        arg pJustRcvdStatus: implementation-data-type=tRxSignalJustRcvdStatus, type=tRxSignalJustRcvdStatus, direction=INOUT
      RxCan_SignalInvalidProcessingControl
        arg SignalId: implementation-data-type=tRxSignalId, type=tRxSignalId, direction=IN
        arg Status: implementation-data-type=Boolean, type=Boolean, direction=IN
      RxCan_SignalMissingProcessingControl
        arg SignalId: implementation-data-type=tRxSignalId, type=tRxSignalId, direction=IN
        arg Status: implementation-data-type=Boolean, type=Boolean, direction=IN
      RxCan_SignalNRProcessingControl
        arg SignalId: implementation-data-type=tRxSignalId, type=tRxSignalId, direction=IN
        arg Status: implementation-data-type=Boolean, type=Boolean, direction=IN
    error E_NOT_OK: error-code=1
  impl type tTxSignalId:
    category=VALUE
    base-type=uint8
    compu {0=eSecureTxByte0Out, 1=eSecureTxByte1Out, 2=eSecureTxByte2Out, 3=eSecureTxByte3Out, 4=eMAC_TxOut, 5=eFV_TxOut, 6=eOdometerOut, 7=eVehicleSpeedICOut, 8=eIllumination_PWMOut, 9=eDebug1_Byte0Out, 10=eDebug1_Byte1Out, 11=eDebug1_Byte2Out, 12=eDebug1_Byte3Out, 13=eDebug1_Byte4Out, 14=eDebug1_Byte5Out, 15=eDebug1_Byte6Out, 16=eDebug1_Byte7Out, 17=eDebug2_Byte0Out, 18=eDebug2_Byte1Out, 19=eDebug2_Byte2Out, 20=eDebug2_Byte3Out, 21=eDebug2_Byte4Out, 22=eDebug2_Byte5Out, 23=eDebug2_Byte6Out, 24=eDebug2_Byte7Out, 25=eDebug3_Byte0Out, 26=eDebug3_Byte1Out, 27=eDebug3_Byte2Out, 28=eDebug3_Byte3Out, 29=eDebug3_Byte4Out, 30=eDebug3_Byte5Out, 31=eDebug3_Byte6Out, 32=eDebug3_Byte7Out, 33=eDebug4_Byte0Out, 34=eDebug4_Byte1Out, 35=eDebug4_Byte2Out, 36=eDebug4_Byte3Out, 37=eDebug4_Byte4Out, 38=eDebug4_Byte5Out, 39=eDebug4_Byte6Out, 40=eDebug4_Byte7Out, 41=eDebug5_Byte0Out, 42=eDebug5_Byte1Out, 43=eDebug5_Byte2Out, 44=eDebug5_Byte3Out, 45=eDebug5_Byte4Out, 46=eDebug5_Byte5Out, 47=eDebug5_Byte6Out, 48=eDebug5_Byte7Out, 49=eEndOfTxSignal}
    range raw 0..49
  compu method sc_tTxSigConfirmStatus: 0=eTxSigConfirmStatus_Cleared, 1=eTxSigConfirmStatus_Set, 2=eTxSigConfirmStatus_NotSupported
  impl type tTxSigConfirmStatus: category=VALUE, base-type=uint8, compu-method=Types/sc_tTxSigConfirmStatus, range raw 0..2
  client server interface if_CS_ComAbsTx
    5 x operation:
      TxCan_ClearCanSignalTxConfirmation
        arg SignalId: implementation-data-type=tTxSignalId, type=tTxSignalId, direction=IN
      TxCan_GetCanSignalTxConfirmation
        arg SignalId: implementation-data-type=tTxSignalId, type=tTxSignalId, direction=IN
        arg pStatus: implementation-data-type=Types/tTxSigConfirmStatus, type=Types/tTxSigConfirmStatus, direction=OUT
      TxCan_SetSignalFromRetentionBuffer: possible-error=if_CS_ComAbsTx/E_NOT_OK
        arg SignalId: implementation-data-type=tTxSignalId, type=tTxSignalId, direction=IN
      TxCan_SetSignalValue: possible-error=if_CS_ComAbsTx/E_NOT_OK
        arg SignalId: implementation-data-type=tTxSignalId, type=tTxSignalId, direction=IN
        arg pTxSignalData: implementation-data-type=DataTypes/UInt8, type=DataTypes/UInt8, direction=INOUT
      TxCan_SetSignalValueU8Arr: possible-error=if_CS_ComAbsTx/E_NOT_OK
        arg SignalId: implementation-data-type=tTxSignalId, type=tTxSignalId, direction=IN
        arg pTxSignalData: implementation-data-type=DataTypes/UInt8, type=DataTypes/UInt8, direction=INOUT
        arg SignalLength: implementation-data-type=UInt32, type=UInt32, direction=IN
    error E_NOT_OK: error-code=1
  impl type tSafeRxSignalId: category=VALUE, base-type=uint8, compu {0=eVehicleSpeedABSIn, 1=eAirbagIn, 2=eAlive_101In, 3=eCRC_101In, 4=eEndOfSafeRxSignal}, range raw 0..4
  impl type tSafeRxSignalStatus: category=VALUE, base-type=uint8, compu {0=eSIGNAL_OK, 1=eSIGNAL_MISSING, 2=eSIGNAL_NEVER_RECEIVED, 3=eSIGNAL_INVALID, 4=eSIGNAL_INVALID_CRC, 5=eSIGNAL_INVALID_ALIVE_COUNTER, 6=eSIGNAL_REPEATED}, range raw 0..6
  impl type tSafeRxSignalJustRcvdStatus: category=VALUE, base-type=uint8, compu {0=eJust_Received, 1=eNot_Just_Received}, range raw 0..1
  client server interface if_CS_ComAbsRxSafe
    9 x operation:
      RxCan_GetSignalValue: possible-error=if_CS_ComAbsRxSafe/E_NOT_OK
        arg SignalId: implementation-data-type=tSafeRxSignalId, type=tSafeRxSignalId, direction=IN
        arg pSignalValue: implementation-data-type=DataTypes/UInt8, type=DataTypes/UInt8, direction=OUT
        arg pSignalStatus: implementation-data-type=tSafeRxSignalStatus, type=tSafeRxSignalStatus, direction=OUT
      RxCan_GetSignalValueU8Arr: possible-error=if_CS_ComAbsRxSafe/E_NOT_OK
        4 x arg:
          SignalId: implementation-data-type=tSafeRxSignalId, type=tSafeRxSignalId, direction=IN
          pSignalValue: implementation-data-type=DataTypes/UInt8, type=DataTypes/UInt8, direction=OUT
          pSignalStatus: implementation-data-type=tSafeRxSignalStatus, type=tSafeRxSignalStatus, direction=OUT
          pSignalLength: implementation-data-type=UInt32, type=UInt32, direction=OUT
      RxCan_SetSignalInitValue: possible-error=if_CS_ComAbsRxSafe/E_NOT_OK
        arg SignalId: implementation-data-type=tSafeRxSignalId, type=tSafeRxSignalId, direction=IN
        arg pSignalValue: implementation-data-type=DataTypes/UInt8, type=DataTypes/UInt8, direction=OUT
      RxCan_SetSignalInitValueU8Arr: possible-error=if_CS_ComAbsRxSafe/E_NOT_OK
        arg SignalId: implementation-data-type=tSafeRxSignalId, type=tSafeRxSignalId, direction=IN
        arg pSignaValue: implementation-data-type=DataTypes/UInt8, type=DataTypes/UInt8, direction=OUT
        arg pSignalLength: implementation-data-type=UInt32, type=UInt32, direction=OUT
      RxCan_SignalClearJustRcvdStatus
        arg SignalId: implementation-data-type=tSafeRxSignalId, type=tSafeRxSignalId, direction=IN
      RxCan_SignalGetJustRcvdStatus
        arg SignalId: implementation-data-type=tSafeRxSignalId, type=tSafeRxSignalId, direction=IN
        arg pJustRcvdStatus: implementation-data-type=tSafeRxSignalJustRcvdStatus, type=tSafeRxSignalJustRcvdStatus, direction=INOUT
      RxCan_SignalInvalidProcessingControl
        arg SignalId: implementation-data-type=tSafeRxSignalId, type=tSafeRxSignalId, direction=IN
        arg Status: implementation-data-type=Boolean, type=Boolean, direction=IN
      RxCan_SignalMissingProcessingControl
        arg SignalId: implementation-data-type=tSafeRxSignalId, type=tSafeRxSignalId, direction=IN
        arg Status: implementation-data-type=Boolean, type=Boolean, direction=IN
      RxCan_SignalNRProcessingControl
        arg SignalId: implementation-data-type=tSafeRxSignalId, type=tSafeRxSignalId, direction=IN
        arg Status: implementation-data-type=Boolean, type=Boolean, direction=IN
    error E_NOT_OK: error-code=1
  impl type tSafeTxSignalId: category=VALUE, base-type=uint8, compu {0=eBattery_VoltageOut, 1=eAlive_200Out, 2=eCRC_200Out, 3=eEndofSafeTxSignals}, range raw 0..3
  compu method sc_tTxSigConfirmStatus: 0=eTxSigConfirmStatus_Cleared, 1=eTxSigConfirmStatus_Set, 2=eTxSigConfirmStatus_NotSupported
  impl type tTxSigConfirmStatus: category=VALUE, base-type=uint8, compu-method=Types/sc_tTxSigConfirmStatus, range raw 0..2
  client server interface if_CS_ComAbsTxSafe
    5 x operation:
      TxCan_ClearCanSignalTxConfirmation
        arg SignalId: implementation-data-type=tSafeTxSignalId, type=tSafeTxSignalId, direction=IN
      TxCan_GetCanSignalTxConfirmation
        arg SignalId: implementation-data-type=tSafeTxSignalId, type=tSafeTxSignalId, direction=IN
        arg pStatus: implementation-data-type=Types/tTxSigConfirmStatus, type=Types/tTxSigConfirmStatus, direction=OUT
      TxCan_SetSignalFromRetentionBuffer: possible-error=if_CS_ComAbsTxSafe/E_NOT_OK
        arg SignalId: implementation-data-type=tSafeTxSignalId, type=tSafeTxSignalId, direction=IN
      TxCan_SetSignalValue: possible-error=if_CS_ComAbsTxSafe/E_NOT_OK
        arg SignalId: implementation-data-type=tSafeTxSignalId, type=tSafeTxSignalId, direction=IN
        arg pTxSignalData: implementation-data-type=DataTypes/UInt8, type=DataTypes/UInt8, direction=INOUT
      TxCan_SetSignalValueU8Arr: possible-error=if_CS_ComAbsTxSafe/E_NOT_OK
        arg SignalId: implementation-data-type=tSafeTxSignalId, type=tSafeTxSignalId, direction=IN
        arg pTxSignalData: implementation-data-type=DataTypes/UInt8, type=DataTypes/UInt8, direction=INOUT
        arg SignalLength: implementation-data-type=UInt32, type=UInt32, direction=IN
    error E_NOT_OK: error-code=1
  19 x impl type, all with category=ARRAY:
    Arr_u8_128
      element ArrayElement: category=VALUE, array-size=128, array-size-semantics=FIXED-SIZE, base-type=uint8
    Arr_u8_28
      element ArrayElement: category=VALUE, array-size=28, array-size-semantics=FIXED-SIZE, base-type=uint8
    Arr_u8_64
      element ArrayElement: category=VALUE, array-size=64, array-size-semantics=FIXED-SIZE, base-type=uint8
    Arr_u8_32
      element ArrayElement: category=VALUE, array-size=32, array-size-semantics=FIXED-SIZE, base-type=uint8
    Arr_u16_7
      element ArrayElement: category=VALUE, array-size=7, array-size-semantics=FIXED-SIZE, base-type=uint16
    T_NV_Temperature_Conversion
      element ArrayElement: category=VALUE, array-size=2, array-size-semantics=FIXED-SIZE, base-type=uint32
    Arr_u8_48
      element ArrayElement: category=VALUE, array-size=48, array-size-semantics=FIXED-SIZE, base-type=uint8
    Arr_u8_2048
      element ArrayElement: category=VALUE, array-size=2048, array-size-semantics=FIXED-SIZE, base-type=uint8
    Arr_u8_1024
      element ArrayElement: category=VALUE, array-size=1024, array-size-semantics=FIXED-SIZE, base-type=uint8
    Arr_u8_100
      element ArrayElement: category=VALUE, array-size=100, array-size-semantics=FIXED-SIZE, base-type=uint8
    Arr_u8_8
      element ArrayElement: category=VALUE, array-size=8, array-size-semantics=FIXED-SIZE, base-type=uint8
    Arr_u8_16
      element ArrayElement: category=VALUE, array-size=16, array-size-semantics=FIXED-SIZE, base-type=uint8
    Arr_u8_3
      element ArrayElement: category=VALUE, array-size=3, array-size-semantics=FIXED-SIZE, base-type=uint8
    Arr_u8_61
      element ArrayElement: category=VALUE, array-size=61, array-size-semantics=FIXED-SIZE, base-type=uint8
    Arr_u8_9
      element ArrayElement: category=VALUE, array-size=9, array-size-semantics=FIXED-SIZE, base-type=uint8
    Arr_u8_10
      element ArrayElement: category=VALUE, array-size=10, array-size-semantics=FIXED-SIZE, base-type=uint8
    Arr_u8_256
      element ArrayElement: category=VALUE, array-size=256, array-size-semantics=FIXED-SIZE, base-type=uint8
    Arr_u8_46
      element ArrayElement: category=VALUE, array-size=46, array-size-semantics=FIXED-SIZE, base-type=uint8
    Arr_u8_17
      element ArrayElement: category=VALUE, array-size=17, array-size-semantics=FIXED-SIZE, base-type=uint8
  4 x client server interface:
    if_CS_MemAbsGet
      94 x operation, all with possible-error=if_CS_MemAbsGet/E_NOT_OK:
        Get_BsConst_Audio_Element
          arg Ptr: implementation-data-type=Arr_u8_128, type=Arr_u8_128, direction=OUT
        Get_BsConst_BsConst_Illumination_ReservedByte
          arg Ptr: implementation-data-type=Arr_u8_28, type=Arr_u8_28, direction=OUT
        Get_BsConst_BsConst_Illumination_ReservedByte_SafeCopy1
          arg Ptr: implementation-data-type=Arr_u8_28, type=Arr_u8_28, direction=OUT
        Get_BsConst_BsConst_Illumination_ReservedByte_SafeCopy2
          arg Ptr: implementation-data-type=Arr_u8_28, type=Arr_u8_28, direction=OUT
        Get_BsConst_Communication_Element
          arg Ptr: implementation-data-type=Arr_u8_64, type=Arr_u8_64, direction=OUT
        Get_BsConst_Compensation_Line_Shift_b
          arg Ptr: implementation-data-type=UInt32, type=UInt32, direction=OUT
        Get_BsConst_Compensation_Line_Shift_b_SafeCopy1
          arg Ptr: implementation-data-type=UInt32, type=UInt32, direction=OUT
        Get_BsConst_Compensation_Line_Shift_b_SafeCopy2
          arg Ptr: implementation-data-type=UInt32, type=UInt32, direction=OUT
        Get_BsConst_Compensation_Line_Slope_m
          arg Ptr: implementation-data-type=UInt32, type=UInt32, direction=OUT
        Get_BsConst_Compensation_Line_Slope_m_SafeCopy1
          arg Ptr: implementation-data-type=UInt32, type=UInt32, direction=OUT
        Get_BsConst_Compensation_Line_Slope_m_SafeCopy2
          arg Ptr: implementation-data-type=UInt32, type=UInt32, direction=OUT
        Get_BsConst_Derating_Backlight_Disable
          arg Ptr: implementation-data-type=DataTypes/UInt8, type=DataTypes/UInt8, direction=OUT
        Get_BsConst_Derating_Backlight_Disable_SafeCopy1
          arg Ptr: implementation-data-type=DataTypes/UInt8, type=DataTypes/UInt8, direction=OUT
        Get_BsConst_Derating_Backlight_Disable_SafeCopy2
          arg Ptr: implementation-data-type=DataTypes/UInt8, type=DataTypes/UInt8, direction=OUT
        Get_BsConst_Display_Illum_Max_Level
          arg Ptr: implementation-data-type=UInt16, type=UInt16, direction=OUT
        Get_BsConst_Display_Illum_Max_Level_SafeCopy1
          arg Ptr: implementation-data-type=UInt16, type=UInt16, direction=OUT
        Get_BsConst_Display_Illum_Max_Level_SafeCopy2
          arg Ptr: implementation-data-type=UInt16, type=UInt16, direction=OUT
        Get_BsConst_EngOffTimer_Element
          arg Ptr: implementation-data-type=Arr_u8_32, type=Arr_u8_32, direction=OUT
        Get_BsConst_FuelGauge_Element
          arg Ptr: implementation-data-type=Arr_u8_128, type=Arr_u8_128, direction=OUT
        Get_BsConst_Lookup_Curve_HotSpot_Coef_X
          arg Ptr: implementation-data-type=Arr_u16_7, type=Arr_u16_7, direction=OUT
        Get_BsConst_Lookup_Curve_HotSpot_Coef_X_SafeCopy1
          arg Ptr: implementation-data-type=Arr_u16_7, type=Arr_u16_7, direction=OUT
        Get_BsConst_Lookup_Curve_HotSpot_Coef_X_SafeCopy2
          arg Ptr: implementation-data-type=Arr_u16_7, type=Arr_u16_7, direction=OUT
        Get_BsConst_Lookup_Curve_HotSpot_Coef_Y
          arg Ptr: implementation-data-type=Arr_u16_7, type=Arr_u16_7, direction=OUT
        Get_BsConst_Lookup_Curve_HotSpot_Coef_Y_SafeCopy1
          arg Ptr: implementation-data-type=Arr_u16_7, type=Arr_u16_7, direction=OUT
        Get_BsConst_Lookup_Curve_HotSpot_Coef_Y_SafeCopy2
          arg Ptr: implementation-data-type=Arr_u16_7, type=Arr_u16_7, direction=OUT
        Get_BsConst_OilGauge_Element
          arg Ptr: implementation-data-type=Arr_u8_64, type=Arr_u8_64, direction=OUT
        Get_BsConst_PCB_Temperature_Sensor_Conv
          arg Ptr: implementation-data-type=T_NV_Temperature_Conversion, type=T_NV_Temperature_Conversion, direction=OUT
        Get_BsConst_PCB_Temperature_Sensor_Conv_SafeCopy1
          arg Ptr: implementation-data-type=T_NV_Temperature_Conversion, type=T_NV_Temperature_Conversion, direction=OUT
        Get_BsConst_PCB_Temperature_Sensor_Conv_SafeCopy2
          arg Ptr: implementation-data-type=T_NV_Temperature_Conversion, type=T_NV_Temperature_Conversion, direction=OUT
        Get_BsConst_PWM_boost_bypass_duty
          arg Ptr: implementation-data-type=DataTypes/UInt8, type=DataTypes/UInt8, direction=OUT
        Get_BsConst_PWM_boost_bypass_duty_SafeCopy1
          arg Ptr: implementation-data-type=DataTypes/UInt8, type=DataTypes/UInt8, direction=OUT
        Get_BsConst_PWM_boost_bypass_duty_SafeCopy2
          arg Ptr: implementation-data-type=DataTypes/UInt8, type=DataTypes/UInt8, direction=OUT
        Get_BsConst_PowerGauge_Element
          arg Ptr: implementation-data-type=Arr_u8_64, type=Arr_u8_64, direction=OUT
        Get_BsConst_Power_Element
          arg Ptr: implementation-data-type=Arr_u8_32, type=Arr_u8_32, direction=OUT
        Get_BsConst_RealTimeClock_Element
          arg Ptr: implementation-data-type=Arr_u8_48, type=Arr_u8_48, direction=OUT
        Get_BsConst_ServiceReminder_Element
          arg Ptr: implementation-data-type=Arr_u8_48, type=Arr_u8_48, direction=OUT
        Get_BsConst_SpeedoGauge_Element
          arg Ptr: implementation-data-type=Arr_u8_64, type=Arr_u8_64, direction=OUT
        Get_BsConst_TachoGauge_Element
          arg Ptr: implementation-data-type=Arr_u8_64, type=Arr_u8_64, direction=OUT
        Get_BsConst_TempGauge_Element
          arg Ptr: implementation-data-type=Arr_u8_64, type=Arr_u8_64, direction=OUT
        Get_BsConst_Temp_Threshold_Hysteresis_Derating
          arg Ptr: implementation-data-type=DataTypes/UInt8, type=DataTypes/UInt8, direction=OUT
        Get_BsConst_Temp_Threshold_Hysteresis_Derating_SafeCopy1
          arg Ptr: implementation-data-type=DataTypes/UInt8, type=DataTypes/UInt8, direction=OUT
        Get_BsConst_Temp_Threshold_Hysteresis_Derating_SafeCopy2
          arg Ptr: implementation-data-type=DataTypes/UInt8, type=DataTypes/UInt8, direction=OUT
        Get_BsConst_Temperature_Sensor_Conv
          arg Ptr: implementation-data-type=T_NV_Temperature_Conversion, type=T_NV_Temperature_Conversion, direction=OUT
        Get_BsConst_Temperature_Sensor_Conv_SafeCopy1
          arg Ptr: implementation-data-type=T_NV_Temperature_Conversion, type=T_NV_Temperature_Conversion, direction=OUT
        Get_BsConst_Temperature_Sensor_Conv_SafeCopy2
          arg Ptr: implementation-data-type=T_NV_Temperature_Conversion, type=T_NV_Temperature_Conversion, direction=OUT
        Get_BsConst_TripComputer_Element
          arg Ptr: implementation-data-type=Arr_u8_64, type=Arr_u8_64, direction=OUT
        Get_BsConst_Warning_Element
          arg Ptr: implementation-data-type=Arr_u8_64, type=Arr_u8_64, direction=OUT
        Get_BsCys_Certicificate_Element
          arg Ptr: implementation-data-type=Arr_u8_64, type=Arr_u8_64, direction=OUT
        Get_BsDiag_Dtc_Element
          arg Ptr: implementation-data-type=Arr_u8_2048, type=Arr_u8_2048, direction=OUT
        Get_BsDiag_ErrorRecord_Element
          arg Ptr: implementation-data-type=Arr_u8_1024, type=Arr_u8_1024, direction=OUT
        Get_BsReten_Audio_Element
          arg Ptr: implementation-data-type=Arr_u8_100, type=Arr_u8_100, direction=OUT
        Get_BsReten_Communication_Element
          arg Ptr: implementation-data-type=Arr_u8_100, type=Arr_u8_100, direction=OUT
        Get_BsReten_Display_Element
          arg Ptr: implementation-data-type=Arr_u8_100, type=Arr_u8_100, direction=OUT
        Get_BsReten_Gauges_Element
          arg Ptr: implementation-data-type=Arr_u8_100, type=Arr_u8_100, direction=OUT
        Get_BsReten_Illumination_Element
          arg Ptr: implementation-data-type=Arr_u8_100, type=Arr_u8_100, direction=OUT
        Get_BsReten_Odometer_Element
          arg Ptr: implementation-data-type=Arr_u8_100, type=Arr_u8_100, direction=OUT
        Get_BsReten_Personalization_Element
          arg Ptr: implementation-data-type=Arr_u8_100, type=Arr_u8_100, direction=OUT
        Get_BsReten_Power_Element
          arg Ptr: implementation-data-type=Arr_u8_100, type=Arr_u8_100, direction=OUT
        Get_BsReten_RealTimeClock_Element
          arg Ptr: implementation-data-type=Arr_u8_100, type=Arr_u8_100, direction=OUT
        Get_BsReten_Tripcomputer_Element
          arg Ptr: implementation-data-type=Arr_u8_100, type=Arr_u8_100, direction=OUT
        Get_BsReten_Warning_Element
          arg Ptr: implementation-data-type=Arr_u8_100, type=Arr_u8_100, direction=OUT
        Get_BsRt_CusDlt_Element
          arg Ptr: implementation-data-type=Arr_u8_128, type=Arr_u8_128, direction=OUT
        Get_BsRt_FuelGauge_Element
          arg Ptr: implementation-data-type=Arr_u8_32, type=Arr_u8_32, direction=OUT
        Get_BsRt_Illumination_Element
          arg Ptr: implementation-data-type=Arr_u8_100, type=Arr_u8_100, direction=OUT
        Get_BsRt_Odometer_Element
          arg Ptr: implementation-data-type=Arr_u8_128, type=Arr_u8_128, direction=OUT
        Get_BsRt_OilGauge_Element
          arg Ptr: implementation-data-type=Arr_u8_8, type=Arr_u8_8, direction=OUT
        Get_BsRt_Personalization_Element
          arg Ptr: implementation-data-type=Arr_u8_128, type=Arr_u8_128, direction=OUT
        Get_BsRt_PowerGauge_Element
          arg Ptr: implementation-data-type=Arr_u8_32, type=Arr_u8_32, direction=OUT
        Get_BsRt_RealTimeClock_Element
          arg Ptr: implementation-data-type=Arr_u8_48, type=Arr_u8_48, direction=OUT
        Get_BsRt_SpeedoGauge_Element
          arg Ptr: implementation-data-type=Arr_u8_8, type=Arr_u8_8, direction=OUT
        Get_BsRt_TachoGauge_Element
          arg Ptr: implementation-data-type=Arr_u8_16, type=Arr_u8_16, direction=OUT
        Get_BsRt_TempGauge_Element
          arg Ptr: implementation-data-type=Arr_u8_32, type=Arr_u8_32, direction=OUT
        Get_BsRt_TripComputer_Element
          arg Ptr: implementation-data-type=Arr_u8_64, type=Arr_u8_64, direction=OUT
        Get_BsRt_Warning_Element
          arg Ptr: implementation-data-type=Arr_u8_32, type=Arr_u8_32, direction=OUT
        Get_BsShare_AssemblyManufacturingDate
          arg Ptr: implementation-data-type=Arr_u8_3, type=Arr_u8_3, direction=OUT
        Get_BsShare_AssemblyPlantNumber
          arg Ptr: implementation-data-type=Arr_u8_3, type=Arr_u8_3, direction=OUT
        Get_BsShare_EcuPartNumber_Element
          arg Ptr: implementation-data-type=Arr_u8_61, type=Arr_u8_61, direction=OUT
        Get_BsShare_HWModification
          arg Ptr: implementation-data-type=UInt16, type=UInt16, direction=OUT
        Get_BsShare_PCBSerialNumber
          arg Ptr: implementation-data-type=Arr_u8_9, type=Arr_u8_9, direction=OUT
        Get_BsShare_ProductSerialNumber
          arg Ptr: implementation-data-type=Arr_u8_10, type=Arr_u8_10, direction=OUT
        Get_BsShare_SMTManufacturingDate
          arg Ptr: implementation-data-type=Arr_u8_3, type=Arr_u8_3, direction=OUT
        Get_BsShare_SMTPlantNumber
          arg Ptr: implementation-data-type=Arr_u8_3, type=Arr_u8_3, direction=OUT
        Get_BsShare_SwUpdFotaFinPrint_Element
          arg Ptr: implementation-data-type=Arr_u8_32, type=Arr_u8_32, direction=OUT
        Get_BsShare_SwUpdFotaMode_Element
          arg Ptr: implementation-data-type=Arr_u8_16, type=Arr_u8_16, direction=OUT
        Get_BsShare_SwUpdFotaStatus_Element
          arg Ptr: implementation-data-type=Arr_u8_48, type=Arr_u8_48, direction=OUT
        Get_BsShare_SwUpdFotadecrypt_Element
          arg Ptr: implementation-data-type=Arr_u8_64, type=Arr_u8_64, direction=OUT
        Get_BsShare_SwUpdReflash_Element
          arg Ptr: implementation-data-type=Arr_u8_8, type=Arr_u8_8, direction=OUT
        Get_BsShare_VehicleConfig_Element
          arg Ptr: implementation-data-type=Arr_u8_256, type=Arr_u8_256, direction=OUT
        Get_BsShare_VisMeet_EOLEntry_Element
          arg Ptr: implementation-data-type=UInt16, type=UInt16, direction=OUT
        Get_BsShare_VisMeet_Element
          arg Ptr: implementation-data-type=Arr_u8_46, type=Arr_u8_46, direction=OUT
        Get_BsShare_VisteonPCBPartNumber
          arg Ptr: implementation-data-type=Arr_u8_17, type=Arr_u8_17, direction=OUT
        Get_BsShare_VisteonPartNumber
          arg Ptr: implementation-data-type=Arr_u8_17, type=Arr_u8_17, direction=OUT
        Get_RefCys_Certicificate1_Element
          arg Ptr: implementation-data-type=Arr_u8_64, type=Arr_u8_64, direction=OUT
        Get_RefCys_Certicificate_Element
          arg Ptr: implementation-data-type=Arr_u8_64, type=Arr_u8_64, direction=OUT
      error E_NOT_OK: error-code=1
    if_CS_MemAbsGetDefault
      94 x operation, all with possible-error=if_CS_MemAbsGetDefault/E_NOT_OK:
        Get_Default_BsConst_Audio_Element
          arg Ptr: implementation-data-type=Arr_u8_128, type=Arr_u8_128, direction=OUT
        Get_Default_BsConst_BsConst_Illumination_ReservedByte
          arg Ptr: implementation-data-type=Arr_u8_28, type=Arr_u8_28, direction=OUT
        Get_Default_BsConst_BsConst_Illumination_ReservedByte_SafeCopy1
          arg Ptr: implementation-data-type=Arr_u8_28, type=Arr_u8_28, direction=OUT
        Get_Default_BsConst_BsConst_Illumination_ReservedByte_SafeCopy2
          arg Ptr: implementation-data-type=Arr_u8_28, type=Arr_u8_28, direction=OUT
        Get_Default_BsConst_Communication_Element
          arg Ptr: implementation-data-type=Arr_u8_64, type=Arr_u8_64, direction=OUT
        Get_Default_BsConst_Compensation_Line_Shift_b
          arg Ptr: implementation-data-type=UInt32, type=UInt32, direction=OUT
        Get_Default_BsConst_Compensation_Line_Shift_b_SafeCopy1
          arg Ptr: implementation-data-type=UInt32, type=UInt32, direction=OUT
        Get_Default_BsConst_Compensation_Line_Shift_b_SafeCopy2
          arg Ptr: implementation-data-type=UInt32, type=UInt32, direction=OUT
        Get_Default_BsConst_Compensation_Line_Slope_m
          arg Ptr: implementation-data-type=UInt32, type=UInt32, direction=OUT
        Get_Default_BsConst_Compensation_Line_Slope_m_SafeCopy1
          arg Ptr: implementation-data-type=UInt32, type=UInt32, direction=OUT
        Get_Default_BsConst_Compensation_Line_Slope_m_SafeCopy2
          arg Ptr: implementation-data-type=UInt32, type=UInt32, direction=OUT
        Get_Default_BsConst_Derating_Backlight_Disable
          arg Ptr: implementation-data-type=DataTypes/UInt8, type=DataTypes/UInt8, direction=OUT
        Get_Default_BsConst_Derating_Backlight_Disable_SafeCopy1
          arg Ptr: implementation-data-type=DataTypes/UInt8, type=DataTypes/UInt8, direction=OUT
        Get_Default_BsConst_Derating_Backlight_Disable_SafeCopy2
          arg Ptr: implementation-data-type=DataTypes/UInt8, type=DataTypes/UInt8, direction=OUT
        Get_Default_BsConst_Display_Illum_Max_Level
          arg Ptr: implementation-data-type=UInt16, type=UInt16, direction=OUT
        Get_Default_BsConst_Display_Illum_Max_Level_SafeCopy1
          arg Ptr: implementation-data-type=UInt16, type=UInt16, direction=OUT
        Get_Default_BsConst_Display_Illum_Max_Level_SafeCopy2
          arg Ptr: implementation-data-type=UInt16, type=UInt16, direction=OUT
        Get_Default_BsConst_EngOffTimer_Element
          arg Ptr: implementation-data-type=Arr_u8_32, type=Arr_u8_32, direction=OUT
        Get_Default_BsConst_FuelGauge_Element
          arg Ptr: implementation-data-type=Arr_u8_128, type=Arr_u8_128, direction=OUT
        Get_Default_BsConst_Lookup_Curve_HotSpot_Coef_X
          arg Ptr: implementation-data-type=Arr_u16_7, type=Arr_u16_7, direction=OUT
        Get_Default_BsConst_Lookup_Curve_HotSpot_Coef_X_SafeCopy1
          arg Ptr: implementation-data-type=Arr_u16_7, type=Arr_u16_7, direction=OUT
        Get_Default_BsConst_Lookup_Curve_HotSpot_Coef_X_SafeCopy2
          arg Ptr: implementation-data-type=Arr_u16_7, type=Arr_u16_7, direction=OUT
        Get_Default_BsConst_Lookup_Curve_HotSpot_Coef_Y
          arg Ptr: implementation-data-type=Arr_u16_7, type=Arr_u16_7, direction=OUT
        Get_Default_BsConst_Lookup_Curve_HotSpot_Coef_Y_SafeCopy1
          arg Ptr: implementation-data-type=Arr_u16_7, type=Arr_u16_7, direction=OUT
        Get_Default_BsConst_Lookup_Curve_HotSpot_Coef_Y_SafeCopy2
          arg Ptr: implementation-data-type=Arr_u16_7, type=Arr_u16_7, direction=OUT
        Get_Default_BsConst_OilGauge_Element
          arg Ptr: implementation-data-type=Arr_u8_64, type=Arr_u8_64, direction=OUT
        Get_Default_BsConst_PCB_Temperature_Sensor_Conv
          arg Ptr: implementation-data-type=T_NV_Temperature_Conversion, type=T_NV_Temperature_Conversion, direction=OUT
        Get_Default_BsConst_PCB_Temperature_Sensor_Conv_SafeCopy1
          arg Ptr: implementation-data-type=T_NV_Temperature_Conversion, type=T_NV_Temperature_Conversion, direction=OUT
        Get_Default_BsConst_PCB_Temperature_Sensor_Conv_SafeCopy2
          arg Ptr: implementation-data-type=T_NV_Temperature_Conversion, type=T_NV_Temperature_Conversion, direction=OUT
        Get_Default_BsConst_PWM_boost_bypass_duty
          arg Ptr: implementation-data-type=DataTypes/UInt8, type=DataTypes/UInt8, direction=OUT
        Get_Default_BsConst_PWM_boost_bypass_duty_SafeCopy1
          arg Ptr: implementation-data-type=DataTypes/UInt8, type=DataTypes/UInt8, direction=OUT
        Get_Default_BsConst_PWM_boost_bypass_duty_SafeCopy2
          arg Ptr: implementation-data-type=DataTypes/UInt8, type=DataTypes/UInt8, direction=OUT
        Get_Default_BsConst_PowerGauge_Element
          arg Ptr: implementation-data-type=Arr_u8_64, type=Arr_u8_64, direction=OUT
        Get_Default_BsConst_Power_Element
          arg Ptr: implementation-data-type=Arr_u8_32, type=Arr_u8_32, direction=OUT
        Get_Default_BsConst_RealTimeClock_Element
          arg Ptr: implementation-data-type=Arr_u8_48, type=Arr_u8_48, direction=OUT
        Get_Default_BsConst_ServiceReminder_Element
          arg Ptr: implementation-data-type=Arr_u8_48, type=Arr_u8_48, direction=OUT
        Get_Default_BsConst_SpeedoGauge_Element
          arg Ptr: implementation-data-type=Arr_u8_64, type=Arr_u8_64, direction=OUT
        Get_Default_BsConst_TachoGauge_Element
          arg Ptr: implementation-data-type=Arr_u8_64, type=Arr_u8_64, direction=OUT
        Get_Default_BsConst_TempGauge_Element
          arg Ptr: implementation-data-type=Arr_u8_64, type=Arr_u8_64, direction=OUT
        Get_Default_BsConst_Temp_Threshold_Hysteresis_Derating
          arg Ptr: implementation-data-type=DataTypes/UInt8, type=DataTypes/UInt8, direction=OUT
        Get_Default_BsConst_Temp_Threshold_Hysteresis_Derating_SafeCopy1
          arg Ptr: implementation-data-type=DataTypes/UInt8, type=DataTypes/UInt8, direction=OUT
        Get_Default_BsConst_Temp_Threshold_Hysteresis_Derating_SafeCopy2
          arg Ptr: implementation-data-type=DataTypes/UInt8, type=DataTypes/UInt8, direction=OUT
        Get_Default_BsConst_Temperature_Sensor_Conv
          arg Ptr: implementation-data-type=T_NV_Temperature_Conversion, type=T_NV_Temperature_Conversion, direction=OUT
        Get_Default_BsConst_Temperature_Sensor_Conv_SafeCopy1
          arg Ptr: implementation-data-type=T_NV_Temperature_Conversion, type=T_NV_Temperature_Conversion, direction=OUT
        Get_Default_BsConst_Temperature_Sensor_Conv_SafeCopy2
          arg Ptr: implementation-data-type=T_NV_Temperature_Conversion, type=T_NV_Temperature_Conversion, direction=OUT
        Get_Default_BsConst_TripComputer_Element
          arg Ptr: implementation-data-type=Arr_u8_64, type=Arr_u8_64, direction=OUT
        Get_Default_BsConst_Warning_Element
          arg Ptr: implementation-data-type=Arr_u8_64, type=Arr_u8_64, direction=OUT
        Get_Default_BsCys_Certicificate_Element
          arg Ptr: implementation-data-type=Arr_u8_64, type=Arr_u8_64, direction=OUT
        Get_Default_BsDiag_Dtc_Element
          arg Ptr: implementation-data-type=Arr_u8_2048, type=Arr_u8_2048, direction=OUT
        Get_Default_BsDiag_ErrorRecord_Element
          arg Ptr: implementation-data-type=Arr_u8_1024, type=Arr_u8_1024, direction=OUT
        Get_Default_BsReten_Audio_Element
          arg Ptr: implementation-data-type=Arr_u8_100, type=Arr_u8_100, direction=OUT
        Get_Default_BsReten_Communication_Element
          arg Ptr: implementation-data-type=Arr_u8_100, type=Arr_u8_100, direction=OUT
        Get_Default_BsReten_Display_Element
          arg Ptr: implementation-data-type=Arr_u8_100, type=Arr_u8_100, direction=OUT
        Get_Default_BsReten_Gauges_Element
          arg Ptr: implementation-data-type=Arr_u8_100, type=Arr_u8_100, direction=OUT
        Get_Default_BsReten_Illumination_Element
          arg Ptr: implementation-data-type=Arr_u8_100, type=Arr_u8_100, direction=OUT
        Get_Default_BsReten_Odometer_Element
          arg Ptr: implementation-data-type=Arr_u8_100, type=Arr_u8_100, direction=OUT
        Get_Default_BsReten_Personalization_Element
          arg Ptr: implementation-data-type=Arr_u8_100, type=Arr_u8_100, direction=OUT
        Get_Default_BsReten_Power_Element
          arg Ptr: implementation-data-type=Arr_u8_100, type=Arr_u8_100, direction=OUT
        Get_Default_BsReten_RealTimeClock_Element
          arg Ptr: implementation-data-type=Arr_u8_100, type=Arr_u8_100, direction=OUT
        Get_Default_BsReten_Tripcomputer_Element
          arg Ptr: implementation-data-type=Arr_u8_100, type=Arr_u8_100, direction=OUT
        Get_Default_BsReten_Warning_Element
          arg Ptr: implementation-data-type=Arr_u8_100, type=Arr_u8_100, direction=OUT
        Get_Default_BsRt_CusDlt_Element
          arg Ptr: implementation-data-type=Arr_u8_128, type=Arr_u8_128, direction=OUT
        Get_Default_BsRt_FuelGauge_Element
          arg Ptr: implementation-data-type=Arr_u8_32, type=Arr_u8_32, direction=OUT
        Get_Default_BsRt_Illumination_Element
          arg Ptr: implementation-data-type=Arr_u8_100, type=Arr_u8_100, direction=OUT
        Get_Default_BsRt_Odometer_Element
          arg Ptr: implementation-data-type=Arr_u8_128, type=Arr_u8_128, direction=OUT
        Get_Default_BsRt_OilGauge_Element
          arg Ptr: implementation-data-type=Arr_u8_8, type=Arr_u8_8, direction=OUT
        Get_Default_BsRt_Personalization_Element
          arg Ptr: implementation-data-type=Arr_u8_128, type=Arr_u8_128, direction=OUT
        Get_Default_BsRt_PowerGauge_Element
          arg Ptr: implementation-data-type=Arr_u8_32, type=Arr_u8_32, direction=OUT
        Get_Default_BsRt_RealTimeClock_Element
          arg Ptr: implementation-data-type=Arr_u8_48, type=Arr_u8_48, direction=OUT
        Get_Default_BsRt_SpeedoGauge_Element
          arg Ptr: implementation-data-type=Arr_u8_8, type=Arr_u8_8, direction=OUT
        Get_Default_BsRt_TachoGauge_Element
          arg Ptr: implementation-data-type=Arr_u8_16, type=Arr_u8_16, direction=OUT
        Get_Default_BsRt_TempGauge_Element
          arg Ptr: implementation-data-type=Arr_u8_32, type=Arr_u8_32, direction=OUT
        Get_Default_BsRt_TripComputer_Element
          arg Ptr: implementation-data-type=Arr_u8_64, type=Arr_u8_64, direction=OUT
        Get_Default_BsRt_Warning_Element
          arg Ptr: implementation-data-type=Arr_u8_32, type=Arr_u8_32, direction=OUT
        Get_Default_BsShare_AssemblyManufacturingDate
          arg Ptr: implementation-data-type=Arr_u8_3, type=Arr_u8_3, direction=OUT
        Get_Default_BsShare_AssemblyPlantNumber
          arg Ptr: implementation-data-type=Arr_u8_3, type=Arr_u8_3, direction=OUT
        Get_Default_BsShare_EcuPartNumber_Element
          arg Ptr: implementation-data-type=Arr_u8_61, type=Arr_u8_61, direction=OUT
        Get_Default_BsShare_HWModification
          arg Ptr: implementation-data-type=UInt16, type=UInt16, direction=OUT
        Get_Default_BsShare_PCBSerialNumber
          arg Ptr: implementation-data-type=Arr_u8_9, type=Arr_u8_9, direction=OUT
        Get_Default_BsShare_ProductSerialNumber
          arg Ptr: implementation-data-type=Arr_u8_10, type=Arr_u8_10, direction=OUT
        Get_Default_BsShare_SMTManufacturingDate
          arg Ptr: implementation-data-type=Arr_u8_3, type=Arr_u8_3, direction=OUT
        Get_Default_BsShare_SMTPlantNumber
          arg Ptr: implementation-data-type=Arr_u8_3, type=Arr_u8_3, direction=OUT
        Get_Default_BsShare_SwUpdFotaFinPrint_Element
          arg Ptr: implementation-data-type=Arr_u8_32, type=Arr_u8_32, direction=OUT
        Get_Default_BsShare_SwUpdFotaMode_Element
          arg Ptr: implementation-data-type=Arr_u8_16, type=Arr_u8_16, direction=OUT
        Get_Default_BsShare_SwUpdFotaStatus_Element
          arg Ptr: implementation-data-type=Arr_u8_48, type=Arr_u8_48, direction=OUT
        Get_Default_BsShare_SwUpdFotadecrypt_Element
          arg Ptr: implementation-data-type=Arr_u8_64, type=Arr_u8_64, direction=OUT
        Get_Default_BsShare_SwUpdReflash_Element
          arg Ptr: implementation-data-type=Arr_u8_8, type=Arr_u8_8, direction=OUT
        Get_Default_BsShare_VehicleConfig_Element
          arg Ptr: implementation-data-type=Arr_u8_256, type=Arr_u8_256, direction=OUT
        Get_Default_BsShare_VisMeet_EOLEntry_Element
          arg Ptr: implementation-data-type=UInt16, type=UInt16, direction=OUT
        Get_Default_BsShare_VisMeet_Element
          arg Ptr: implementation-data-type=Arr_u8_46, type=Arr_u8_46, direction=OUT
        Get_Default_BsShare_VisteonPCBPartNumber
          arg Ptr: implementation-data-type=Arr_u8_17, type=Arr_u8_17, direction=OUT
        Get_Default_BsShare_VisteonPartNumber
          arg Ptr: implementation-data-type=Arr_u8_17, type=Arr_u8_17, direction=OUT
        Get_Default_RefCys_Certicificate1_Element
          arg Ptr: implementation-data-type=Arr_u8_64, type=Arr_u8_64, direction=OUT
        Get_Default_RefCys_Certicificate_Element
          arg Ptr: implementation-data-type=Arr_u8_64, type=Arr_u8_64, direction=OUT
      error E_NOT_OK: error-code=1
    if_CS_MemAbsSet
      94 x operation:
        Set_BsConst_Audio_Element
          arg BsConst_Audio_Element: implementation-data-type=Arr_u8_128, type=Arr_u8_128, direction=IN
        Set_BsConst_BsConst_Illumination_ReservedByte
          arg BsConst_BsConst_Illumination_ReservedByte: implementation-data-type=Arr_u8_28, type=Arr_u8_28, direction=IN
        Set_BsConst_BsConst_Illumination_ReservedByte_SafeCopy1
          arg BsConst_BsConst_Illumination_ReservedByte_SafeCopy1: implementation-data-type=Arr_u8_28, type=Arr_u8_28, direction=IN
        Set_BsConst_BsConst_Illumination_ReservedByte_SafeCopy2
          arg BsConst_BsConst_Illumination_ReservedByte_SafeCopy2: implementation-data-type=Arr_u8_28, type=Arr_u8_28, direction=IN
        Set_BsConst_Communication_Element
          arg BsConst_Communication_Element: implementation-data-type=Arr_u8_64, type=Arr_u8_64, direction=IN
        Set_BsConst_Compensation_Line_Shift_b
          arg BsConst_Compensation_Line_Shift_b: implementation-data-type=UInt32, type=UInt32, direction=IN
        Set_BsConst_Compensation_Line_Shift_b_SafeCopy1
          arg BsConst_Compensation_Line_Shift_b_SafeCopy1: implementation-data-type=UInt32, type=UInt32, direction=IN
        Set_BsConst_Compensation_Line_Shift_b_SafeCopy2
          arg BsConst_Compensation_Line_Shift_b_SafeCopy2: implementation-data-type=UInt32, type=UInt32, direction=IN
        Set_BsConst_Compensation_Line_Slope_m
          arg BsConst_Compensation_Line_Slope_m: implementation-data-type=UInt32, type=UInt32, direction=IN
        Set_BsConst_Compensation_Line_Slope_m_SafeCopy1
          arg BsConst_Compensation_Line_Slope_m_SafeCopy1: implementation-data-type=UInt32, type=UInt32, direction=IN
        Set_BsConst_Compensation_Line_Slope_m_SafeCopy2
          arg BsConst_Compensation_Line_Slope_m_SafeCopy2: implementation-data-type=UInt32, type=UInt32, direction=IN
        Set_BsConst_Derating_Backlight_Disable
          arg BsConst_Derating_Backlight_Disable: implementation-data-type=DataTypes/UInt8, type=DataTypes/UInt8, direction=IN
        Set_BsConst_Derating_Backlight_Disable_SafeCopy1
          arg BsConst_Derating_Backlight_Disable_SafeCopy1: implementation-data-type=DataTypes/UInt8, type=DataTypes/UInt8, direction=IN
        Set_BsConst_Derating_Backlight_Disable_SafeCopy2
          arg BsConst_Derating_Backlight_Disable_SafeCopy2: implementation-data-type=DataTypes/UInt8, type=DataTypes/UInt8, direction=IN
        Set_BsConst_Display_Illum_Max_Level
          arg BsConst_Display_Illum_Max_Level: implementation-data-type=UInt16, type=UInt16, direction=IN
        Set_BsConst_Display_Illum_Max_Level_SafeCopy1
          arg BsConst_Display_Illum_Max_Level_SafeCopy1: implementation-data-type=UInt16, type=UInt16, direction=IN
        Set_BsConst_Display_Illum_Max_Level_SafeCopy2
          arg BsConst_Display_Illum_Max_Level_SafeCopy2: implementation-data-type=UInt16, type=UInt16, direction=IN
        Set_BsConst_EngOffTimer_Element
          arg BsConst_EngOffTimer_Element: implementation-data-type=Arr_u8_32, type=Arr_u8_32, direction=IN
        Set_BsConst_FuelGauge_Element
          arg BsConst_FuelGauge_Element: implementation-data-type=Arr_u8_128, type=Arr_u8_128, direction=IN
        Set_BsConst_Lookup_Curve_HotSpot_Coef_X
          arg BsConst_Lookup_Curve_HotSpot_Coef_X: implementation-data-type=Arr_u16_7, type=Arr_u16_7, direction=IN
        Set_BsConst_Lookup_Curve_HotSpot_Coef_X_SafeCopy1
          arg BsConst_Lookup_Curve_HotSpot_Coef_X_SafeCopy1: implementation-data-type=Arr_u16_7, type=Arr_u16_7, direction=IN
        Set_BsConst_Lookup_Curve_HotSpot_Coef_X_SafeCopy2
          arg BsConst_Lookup_Curve_HotSpot_Coef_X_SafeCopy2: implementation-data-type=Arr_u16_7, type=Arr_u16_7, direction=IN
        Set_BsConst_Lookup_Curve_HotSpot_Coef_Y
          arg BsConst_Lookup_Curve_HotSpot_Coef_Y: implementation-data-type=Arr_u16_7, type=Arr_u16_7, direction=IN
        Set_BsConst_Lookup_Curve_HotSpot_Coef_Y_SafeCopy1
          arg BsConst_Lookup_Curve_HotSpot_Coef_Y_SafeCopy1: implementation-data-type=Arr_u16_7, type=Arr_u16_7, direction=IN
        Set_BsConst_Lookup_Curve_HotSpot_Coef_Y_SafeCopy2
          arg BsConst_Lookup_Curve_HotSpot_Coef_Y_SafeCopy2: implementation-data-type=Arr_u16_7, type=Arr_u16_7, direction=IN
        Set_BsConst_OilGauge_Element
          arg BsConst_OilGauge_Element: implementation-data-type=Arr_u8_64, type=Arr_u8_64, direction=IN
        Set_BsConst_PCB_Temperature_Sensor_Conv
          arg BsConst_PCB_Temperature_Sensor_Conv: implementation-data-type=T_NV_Temperature_Conversion, type=T_NV_Temperature_Conversion, direction=IN
        Set_BsConst_PCB_Temperature_Sensor_Conv_SafeCopy1
          arg BsConst_PCB_Temperature_Sensor_Conv_SafeCopy1: implementation-data-type=T_NV_Temperature_Conversion, type=T_NV_Temperature_Conversion, direction=IN
        Set_BsConst_PCB_Temperature_Sensor_Conv_SafeCopy2
          arg BsConst_PCB_Temperature_Sensor_Conv_SafeCopy2: implementation-data-type=T_NV_Temperature_Conversion, type=T_NV_Temperature_Conversion, direction=IN
        Set_BsConst_PWM_boost_bypass_duty
          arg BsConst_PWM_boost_bypass_duty: implementation-data-type=DataTypes/UInt8, type=DataTypes/UInt8, direction=IN
        Set_BsConst_PWM_boost_bypass_duty_SafeCopy1
          arg BsConst_PWM_boost_bypass_duty_SafeCopy1: implementation-data-type=DataTypes/UInt8, type=DataTypes/UInt8, direction=IN
        Set_BsConst_PWM_boost_bypass_duty_SafeCopy2
          arg BsConst_PWM_boost_bypass_duty_SafeCopy2: implementation-data-type=DataTypes/UInt8, type=DataTypes/UInt8, direction=IN
        Set_BsConst_PowerGauge_Element
          arg BsConst_PowerGauge_Element: implementation-data-type=Arr_u8_64, type=Arr_u8_64, direction=IN
        Set_BsConst_Power_Element
          arg BsConst_Power_Element: implementation-data-type=Arr_u8_32, type=Arr_u8_32, direction=IN
        Set_BsConst_RealTimeClock_Element
          arg BsConst_RealTimeClock_Element: implementation-data-type=Arr_u8_48, type=Arr_u8_48, direction=IN
        Set_BsConst_ServiceReminder_Element
          arg BsConst_ServiceReminder_Element: implementation-data-type=Arr_u8_48, type=Arr_u8_48, direction=IN
        Set_BsConst_SpeedoGauge_Element
          arg BsConst_SpeedoGauge_Element: implementation-data-type=Arr_u8_64, type=Arr_u8_64, direction=IN
        Set_BsConst_TachoGauge_Element
          arg BsConst_TachoGauge_Element: implementation-data-type=Arr_u8_64, type=Arr_u8_64, direction=IN
        Set_BsConst_TempGauge_Element
          arg BsConst_TempGauge_Element: implementation-data-type=Arr_u8_64, type=Arr_u8_64, direction=IN
        Set_BsConst_Temp_Threshold_Hysteresis_Derating
          arg BsConst_Temp_Threshold_Hysteresis_Derating: implementation-data-type=DataTypes/UInt8, type=DataTypes/UInt8, direction=IN
        Set_BsConst_Temp_Threshold_Hysteresis_Derating_SafeCopy1
          arg BsConst_Temp_Threshold_Hysteresis_Derating_SafeCopy1: implementation-data-type=DataTypes/UInt8, type=DataTypes/UInt8, direction=IN
        Set_BsConst_Temp_Threshold_Hysteresis_Derating_SafeCopy2
          arg BsConst_Temp_Threshold_Hysteresis_Derating_SafeCopy2: implementation-data-type=DataTypes/UInt8, type=DataTypes/UInt8, direction=IN
        Set_BsConst_Temperature_Sensor_Conv
          arg BsConst_Temperature_Sensor_Conv: implementation-data-type=T_NV_Temperature_Conversion, type=T_NV_Temperature_Conversion, direction=IN
        Set_BsConst_Temperature_Sensor_Conv_SafeCopy1
          arg BsConst_Temperature_Sensor_Conv_SafeCopy1: implementation-data-type=T_NV_Temperature_Conversion, type=T_NV_Temperature_Conversion, direction=IN
        Set_BsConst_Temperature_Sensor_Conv_SafeCopy2
          arg BsConst_Temperature_Sensor_Conv_SafeCopy2: implementation-data-type=T_NV_Temperature_Conversion, type=T_NV_Temperature_Conversion, direction=IN
        Set_BsConst_TripComputer_Element
          arg BsConst_TripComputer_Element: implementation-data-type=Arr_u8_64, type=Arr_u8_64, direction=IN
        Set_BsConst_Warning_Element
          arg BsConst_Warning_Element: implementation-data-type=Arr_u8_64, type=Arr_u8_64, direction=IN
        Set_BsCys_Certicificate_Element
          arg BsCys_Certicificate_Element: implementation-data-type=Arr_u8_64, type=Arr_u8_64, direction=IN
        Set_BsDiag_Dtc_Element
          arg BsDiag_Dtc_Element: implementation-data-type=Arr_u8_2048, type=Arr_u8_2048, direction=IN
        Set_BsDiag_ErrorRecord_Element
          arg BsDiag_ErrorRecord_Element: implementation-data-type=Arr_u8_1024, type=Arr_u8_1024, direction=IN
        Set_BsReten_Audio_Element
          arg BsReten_Audio_Element: implementation-data-type=Arr_u8_100, type=Arr_u8_100, direction=IN
        Set_BsReten_Communication_Element
          arg BsReten_Communication_Element: implementation-data-type=Arr_u8_100, type=Arr_u8_100, direction=IN
        Set_BsReten_Display_Element
          arg BsReten_Display_Element: implementation-data-type=Arr_u8_100, type=Arr_u8_100, direction=IN
        Set_BsReten_Gauges_Element
          arg BsReten_Gauges_Element: implementation-data-type=Arr_u8_100, type=Arr_u8_100, direction=IN
        Set_BsReten_Illumination_Element
          arg BsReten_Illumination_Element: implementation-data-type=Arr_u8_100, type=Arr_u8_100, direction=IN
        Set_BsReten_Odometer_Element
          arg BsReten_Odometer_Element: implementation-data-type=Arr_u8_100, type=Arr_u8_100, direction=IN
        Set_BsReten_Personalization_Element
          arg BsReten_Personalization_Element: implementation-data-type=Arr_u8_100, type=Arr_u8_100, direction=IN
        Set_BsReten_Power_Element
          arg BsReten_Power_Element: implementation-data-type=Arr_u8_100, type=Arr_u8_100, direction=IN
        Set_BsReten_RealTimeClock_Element
          arg BsReten_RealTimeClock_Element: implementation-data-type=Arr_u8_100, type=Arr_u8_100, direction=IN
        Set_BsReten_Tripcomputer_Element
          arg BsReten_Tripcomputer_Element: implementation-data-type=Arr_u8_100, type=Arr_u8_100, direction=IN
        Set_BsReten_Warning_Element
          arg BsReten_Warning_Element: implementation-data-type=Arr_u8_100, type=Arr_u8_100, direction=IN
        Set_BsRt_CusDlt_Element
          arg BsRt_CusDlt_Element: implementation-data-type=Arr_u8_128, type=Arr_u8_128, direction=IN
        Set_BsRt_FuelGauge_Element
          arg BsRt_FuelGauge_Element: implementation-data-type=Arr_u8_32, type=Arr_u8_32, direction=IN
        Set_BsRt_Illumination_Element
          arg BsRt_Illumination_Element: implementation-data-type=Arr_u8_100, type=Arr_u8_100, direction=IN
        Set_BsRt_Odometer_Element
          arg BsRt_Odometer_Element: implementation-data-type=Arr_u8_128, type=Arr_u8_128, direction=IN
        Set_BsRt_OilGauge_Element
          arg BsRt_OilGauge_Element: implementation-data-type=Arr_u8_8, type=Arr_u8_8, direction=IN
        Set_BsRt_Personalization_Element
          arg BsRt_Personalization_Element: implementation-data-type=Arr_u8_128, type=Arr_u8_128, direction=IN
        Set_BsRt_PowerGauge_Element
          arg BsRt_PowerGauge_Element: implementation-data-type=Arr_u8_32, type=Arr_u8_32, direction=IN
        Set_BsRt_RealTimeClock_Element
          arg BsRt_RealTimeClock_Element: implementation-data-type=Arr_u8_48, type=Arr_u8_48, direction=IN
        Set_BsRt_SpeedoGauge_Element
          arg BsRt_SpeedoGauge_Element: implementation-data-type=Arr_u8_8, type=Arr_u8_8, direction=IN
        Set_BsRt_TachoGauge_Element
          arg BsRt_TachoGauge_Element: implementation-data-type=Arr_u8_16, type=Arr_u8_16, direction=IN
        Set_BsRt_TempGauge_Element
          arg BsRt_TempGauge_Element: implementation-data-type=Arr_u8_32, type=Arr_u8_32, direction=IN
        Set_BsRt_TripComputer_Element
          arg BsRt_TripComputer_Element: implementation-data-type=Arr_u8_64, type=Arr_u8_64, direction=IN
        Set_BsRt_Warning_Element
          arg BsRt_Warning_Element: implementation-data-type=Arr_u8_32, type=Arr_u8_32, direction=IN
        Set_BsShare_AssemblyManufacturingDate
          arg BsShare_AssemblyManufacturingDate: implementation-data-type=Arr_u8_3, type=Arr_u8_3, direction=IN
        Set_BsShare_AssemblyPlantNumber
          arg BsShare_AssemblyPlantNumber: implementation-data-type=Arr_u8_3, type=Arr_u8_3, direction=IN
        Set_BsShare_EcuPartNumber_Element
          arg BsShare_EcuPartNumber_Element: implementation-data-type=Arr_u8_61, type=Arr_u8_61, direction=IN
        Set_BsShare_HWModification
          arg BsShare_HWModification: implementation-data-type=UInt16, type=UInt16, direction=IN
        Set_BsShare_PCBSerialNumber
          arg BsShare_PCBSerialNumber: implementation-data-type=Arr_u8_9, type=Arr_u8_9, direction=IN
        Set_BsShare_ProductSerialNumber
          arg BsShare_ProductSerialNumber: implementation-data-type=Arr_u8_10, type=Arr_u8_10, direction=IN
        Set_BsShare_SMTManufacturingDate
          arg BsShare_SMTManufacturingDate: implementation-data-type=Arr_u8_3, type=Arr_u8_3, direction=IN
        Set_BsShare_SMTPlantNumber
          arg BsShare_SMTPlantNumber: implementation-data-type=Arr_u8_3, type=Arr_u8_3, direction=IN
        Set_BsShare_SwUpdFotaFinPrint_Element
          arg BsShare_SwUpdFotaFinPrint_Element: implementation-data-type=Arr_u8_32, type=Arr_u8_32, direction=IN
        Set_BsShare_SwUpdFotaMode_Element
          arg BsShare_SwUpdFotaMode_Element: implementation-data-type=Arr_u8_16, type=Arr_u8_16, direction=IN
        Set_BsShare_SwUpdFotaStatus_Element
          arg BsShare_SwUpdFotaStatus_Element: implementation-data-type=Arr_u8_48, type=Arr_u8_48, direction=IN
        Set_BsShare_SwUpdFotadecrypt_Element
          arg BsShare_SwUpdFotadecrypt_Element: implementation-data-type=Arr_u8_64, type=Arr_u8_64, direction=IN
        Set_BsShare_SwUpdReflash_Element
          arg BsShare_SwUpdReflash_Element: implementation-data-type=Arr_u8_8, type=Arr_u8_8, direction=IN
        Set_BsShare_VehicleConfig_Element
          arg BsShare_VehicleConfig_Element: implementation-data-type=Arr_u8_256, type=Arr_u8_256, direction=IN
        Set_BsShare_VisMeet_EOLEntry_Element
          arg BsShare_VisMeet_EOLEntry_Element: implementation-data-type=UInt16, type=UInt16, direction=IN
        Set_BsShare_VisMeet_Element
          arg BsShare_VisMeet_Element: implementation-data-type=Arr_u8_46, type=Arr_u8_46, direction=IN
        Set_BsShare_VisteonPCBPartNumber
          arg BsShare_VisteonPCBPartNumber: implementation-data-type=Arr_u8_17, type=Arr_u8_17, direction=IN
        Set_BsShare_VisteonPartNumber
          arg BsShare_VisteonPartNumber: implementation-data-type=Arr_u8_17, type=Arr_u8_17, direction=IN
        Set_RefCys_Certicificate1_Element
          arg RefCys_Certicificate1_Element: implementation-data-type=Arr_u8_64, type=Arr_u8_64, direction=IN
        Set_RefCys_Certicificate_Element
          arg RefCys_Certicificate_Element: implementation-data-type=Arr_u8_64, type=Arr_u8_64, direction=IN
    if_CS_MemAbs_NvMWriteStatus
      operation NvmWriteStatus: possible-error=if_CS_MemAbs_NvMWriteStatus/E_NOT_OK
      error E_NOT_OK: error-code=1
  5 x sender receiver interface:
    if_SR_JobStatus
      94 x data, all with implementation-data-type=DataTypes/UInt8, type=DataTypes/UInt8:
        JobStatus_BsConst_Audio_Element
        JobStatus_BsConst_BsConst_Illumination_ReservedByte
        JobStatus_BsConst_BsConst_Illumination_ReservedByte_SafeCopy1
        JobStatus_BsConst_BsConst_Illumination_ReservedByte_SafeCopy2
        JobStatus_BsConst_Communication_Element
        JobStatus_BsConst_Compensation_Line_Shift_b
        JobStatus_BsConst_Compensation_Line_Shift_b_SafeCopy1
        JobStatus_BsConst_Compensation_Line_Shift_b_SafeCopy2
        JobStatus_BsConst_Compensation_Line_Slope_m
        JobStatus_BsConst_Compensation_Line_Slope_m_SafeCopy1
        JobStatus_BsConst_Compensation_Line_Slope_m_SafeCopy2
        JobStatus_BsConst_Derating_Backlight_Disable
        JobStatus_BsConst_Derating_Backlight_Disable_SafeCopy1
        JobStatus_BsConst_Derating_Backlight_Disable_SafeCopy2
        JobStatus_BsConst_Display_Illum_Max_Level
        JobStatus_BsConst_Display_Illum_Max_Level_SafeCopy1
        JobStatus_BsConst_Display_Illum_Max_Level_SafeCopy2
        JobStatus_BsConst_EngOffTimer_Element
        JobStatus_BsConst_FuelGauge_Element
        JobStatus_BsConst_Lookup_Curve_HotSpot_Coef_X
        JobStatus_BsConst_Lookup_Curve_HotSpot_Coef_X_SafeCopy1
        JobStatus_BsConst_Lookup_Curve_HotSpot_Coef_X_SafeCopy2
        JobStatus_BsConst_Lookup_Curve_HotSpot_Coef_Y
        JobStatus_BsConst_Lookup_Curve_HotSpot_Coef_Y_SafeCopy1
        JobStatus_BsConst_Lookup_Curve_HotSpot_Coef_Y_SafeCopy2
        JobStatus_BsConst_OilGauge_Element
        JobStatus_BsConst_PCB_Temperature_Sensor_Conv
        JobStatus_BsConst_PCB_Temperature_Sensor_Conv_SafeCopy1
        JobStatus_BsConst_PCB_Temperature_Sensor_Conv_SafeCopy2
        JobStatus_BsConst_PWM_boost_bypass_duty
        JobStatus_BsConst_PWM_boost_bypass_duty_SafeCopy1
        JobStatus_BsConst_PWM_boost_bypass_duty_SafeCopy2
        JobStatus_BsConst_PowerGauge_Element
        JobStatus_BsConst_Power_Element
        JobStatus_BsConst_RealTimeClock_Element
        JobStatus_BsConst_ServiceReminder_Element
        JobStatus_BsConst_SpeedoGauge_Element
        JobStatus_BsConst_TachoGauge_Element
        JobStatus_BsConst_TempGauge_Element
        JobStatus_BsConst_Temp_Threshold_Hysteresis_Derating
        JobStatus_BsConst_Temp_Threshold_Hysteresis_Derating_SafeCopy1
        JobStatus_BsConst_Temp_Threshold_Hysteresis_Derating_SafeCopy2
        JobStatus_BsConst_Temperature_Sensor_Conv
        JobStatus_BsConst_Temperature_Sensor_Conv_SafeCopy1
        JobStatus_BsConst_Temperature_Sensor_Conv_SafeCopy2
        JobStatus_BsConst_TripComputer_Element
        JobStatus_BsConst_Warning_Element
        JobStatus_BsCys_Certicificate_Element
        JobStatus_BsDiag_Dtc_Element
        JobStatus_BsDiag_ErrorRecord_Element
        JobStatus_BsReten_Audio_Element
        JobStatus_BsReten_Communication_Element
        JobStatus_BsReten_Display_Element
        JobStatus_BsReten_Gauges_Element
        JobStatus_BsReten_Illumination_Element
        JobStatus_BsReten_Odometer_Element
        JobStatus_BsReten_Personalization_Element
        JobStatus_BsReten_Power_Element
        JobStatus_BsReten_RealTimeClock_Element
        JobStatus_BsReten_Tripcomputer_Element
        JobStatus_BsReten_Warning_Element
        JobStatus_BsRt_CusDlt_Element
        JobStatus_BsRt_FuelGauge_Element
        JobStatus_BsRt_Illumination_Element
        JobStatus_BsRt_Odometer_Element
        JobStatus_BsRt_OilGauge_Element
        JobStatus_BsRt_Personalization_Element
        JobStatus_BsRt_PowerGauge_Element
        JobStatus_BsRt_RealTimeClock_Element
        JobStatus_BsRt_SpeedoGauge_Element
        JobStatus_BsRt_TachoGauge_Element
        JobStatus_BsRt_TempGauge_Element
        JobStatus_BsRt_TripComputer_Element
        JobStatus_BsRt_Warning_Element
        JobStatus_BsShare_AssemblyManufacturingDate
        JobStatus_BsShare_AssemblyPlantNumber
        JobStatus_BsShare_EcuPartNumber_Element
        JobStatus_BsShare_HWModification
        JobStatus_BsShare_PCBSerialNumber
        JobStatus_BsShare_ProductSerialNumber
        JobStatus_BsShare_SMTManufacturingDate
        JobStatus_BsShare_SMTPlantNumber
        JobStatus_BsShare_SwUpdFotaFinPrint_Element
        JobStatus_BsShare_SwUpdFotaMode_Element
        JobStatus_BsShare_SwUpdFotaStatus_Element
        JobStatus_BsShare_SwUpdFotadecrypt_Element
        JobStatus_BsShare_SwUpdReflash_Element
        JobStatus_BsShare_VehicleConfig_Element
        JobStatus_BsShare_VisMeet_EOLEntry_Element
        JobStatus_BsShare_VisMeet_Element
        JobStatus_BsShare_VisteonPCBPartNumber
        JobStatus_BsShare_VisteonPartNumber
        JobStatus_RefCys_Certicificate1_Element
        JobStatus_RefCys_Certicificate_Element
      invalidation-policys:
        data-element=JobStatus_BsConst_Audio_Element, handle-invalid=DONT-INVALIDATE
        data-element=JobStatus_BsConst_BsConst_Illumination_ReservedByte, handle-invalid=DONT-INVALIDATE
        data-element=JobStatus_BsConst_BsConst_Illumination_ReservedByte_SafeCopy1, handle-invalid=DONT-INVALIDATE
        data-element=JobStatus_BsConst_BsConst_Illumination_ReservedByte_SafeCopy2, handle-invalid=DONT-INVALIDATE
        data-element=JobStatus_BsConst_Communication_Element, handle-invalid=DONT-INVALIDATE
        data-element=JobStatus_BsConst_Compensation_Line_Shift_b, handle-invalid=DONT-INVALIDATE
        data-element=JobStatus_BsConst_Compensation_Line_Shift_b_SafeCopy1, handle-invalid=DONT-INVALIDATE
        data-element=JobStatus_BsConst_Compensation_Line_Shift_b_SafeCopy2, handle-invalid=DONT-INVALIDATE
        data-element=JobStatus_BsConst_Compensation_Line_Slope_m, handle-invalid=DONT-INVALIDATE
        data-element=JobStatus_BsConst_Compensation_Line_Slope_m_SafeCopy1, handle-invalid=DONT-INVALIDATE
        data-element=JobStatus_BsConst_Compensation_Line_Slope_m_SafeCopy2, handle-invalid=DONT-INVALIDATE
        data-element=JobStatus_BsConst_Derating_Backlight_Disable, handle-invalid=DONT-INVALIDATE
        data-element=JobStatus_BsConst_Derating_Backlight_Disable_SafeCopy1, handle-invalid=DONT-INVALIDATE
        data-element=JobStatus_BsConst_Derating_Backlight_Disable_SafeCopy2, handle-invalid=DONT-INVALIDATE
        data-element=JobStatus_BsConst_Display_Illum_Max_Level, handle-invalid=DONT-INVALIDATE
        data-element=JobStatus_BsConst_Display_Illum_Max_Level_SafeCopy1, handle-invalid=DONT-INVALIDATE
        data-element=JobStatus_BsConst_Display_Illum_Max_Level_SafeCopy2, handle-invalid=DONT-INVALIDATE
        data-element=JobStatus_BsConst_EngOffTimer_Element, handle-invalid=DONT-INVALIDATE
        data-element=JobStatus_BsConst_FuelGauge_Element, handle-invalid=DONT-INVALIDATE
        data-element=JobStatus_BsConst_Lookup_Curve_HotSpot_Coef_X, handle-invalid=DONT-INVALIDATE
        data-element=JobStatus_BsConst_Lookup_Curve_HotSpot_Coef_X_SafeCopy1, handle-invalid=DONT-INVALIDATE
        data-element=JobStatus_BsConst_Lookup_Curve_HotSpot_Coef_X_SafeCopy2, handle-invalid=DONT-INVALIDATE
        data-element=JobStatus_BsConst_Lookup_Curve_HotSpot_Coef_Y, handle-invalid=DONT-INVALIDATE
        data-element=JobStatus_BsConst_Lookup_Curve_HotSpot_Coef_Y_SafeCopy1, handle-invalid=DONT-INVALIDATE
        data-element=JobStatus_BsConst_Lookup_Curve_HotSpot_Coef_Y_SafeCopy2, handle-invalid=DONT-INVALIDATE
        data-element=JobStatus_BsConst_OilGauge_Element, handle-invalid=DONT-INVALIDATE
        data-element=JobStatus_BsConst_PCB_Temperature_Sensor_Conv, handle-invalid=DONT-INVALIDATE
        data-element=JobStatus_BsConst_PCB_Temperature_Sensor_Conv_SafeCopy1, handle-invalid=DONT-INVALIDATE
        data-element=JobStatus_BsConst_PCB_Temperature_Sensor_Conv_SafeCopy2, handle-invalid=DONT-INVALIDATE
        data-element=JobStatus_BsConst_PWM_boost_bypass_duty, handle-invalid=DONT-INVALIDATE
        data-element=JobStatus_BsConst_PWM_boost_bypass_duty_SafeCopy1, handle-invalid=DONT-INVALIDATE
        data-element=JobStatus_BsConst_PWM_boost_bypass_duty_SafeCopy2, handle-invalid=DONT-INVALIDATE
        data-element=JobStatus_BsConst_PowerGauge_Element, handle-invalid=DONT-INVALIDATE
        data-element=JobStatus_BsConst_Power_Element, handle-invalid=DONT-INVALIDATE
        data-element=JobStatus_BsConst_RealTimeClock_Element, handle-invalid=DONT-INVALIDATE
        data-element=JobStatus_BsConst_ServiceReminder_Element, handle-invalid=DONT-INVALIDATE
        data-element=JobStatus_BsConst_SpeedoGauge_Element, handle-invalid=DONT-INVALIDATE
        data-element=JobStatus_BsConst_TachoGauge_Element, handle-invalid=DONT-INVALIDATE
        data-element=JobStatus_BsConst_TempGauge_Element, handle-invalid=DONT-INVALIDATE
        data-element=JobStatus_BsConst_Temp_Threshold_Hysteresis_Derating, handle-invalid=DONT-INVALIDATE
        data-element=JobStatus_BsConst_Temp_Threshold_Hysteresis_Derating_SafeCopy1, handle-invalid=DONT-INVALIDATE
        data-element=JobStatus_BsConst_Temp_Threshold_Hysteresis_Derating_SafeCopy2, handle-invalid=DONT-INVALIDATE
        data-element=JobStatus_BsConst_Temperature_Sensor_Conv, handle-invalid=DONT-INVALIDATE
        data-element=JobStatus_BsConst_Temperature_Sensor_Conv_SafeCopy1, handle-invalid=DONT-INVALIDATE
        data-element=JobStatus_BsConst_Temperature_Sensor_Conv_SafeCopy2, handle-invalid=DONT-INVALIDATE
        data-element=JobStatus_BsConst_TripComputer_Element, handle-invalid=DONT-INVALIDATE
        data-element=JobStatus_BsConst_Warning_Element, handle-invalid=DONT-INVALIDATE
        data-element=JobStatus_BsCys_Certicificate_Element, handle-invalid=DONT-INVALIDATE
        data-element=JobStatus_BsDiag_Dtc_Element, handle-invalid=DONT-INVALIDATE
        data-element=JobStatus_BsDiag_ErrorRecord_Element, handle-invalid=DONT-INVALIDATE
        data-element=JobStatus_BsReten_Audio_Element, handle-invalid=DONT-INVALIDATE
        data-element=JobStatus_BsReten_Communication_Element, handle-invalid=DONT-INVALIDATE
        data-element=JobStatus_BsReten_Display_Element, handle-invalid=DONT-INVALIDATE
        data-element=JobStatus_BsReten_Gauges_Element, handle-invalid=DONT-INVALIDATE
        data-element=JobStatus_BsReten_Illumination_Element, handle-invalid=DONT-INVALIDATE
        data-element=JobStatus_BsReten_Odometer_Element, handle-invalid=DONT-INVALIDATE
        data-element=JobStatus_BsReten_Personalization_Element, handle-invalid=DONT-INVALIDATE
        data-element=JobStatus_BsReten_Power_Element, handle-invalid=DONT-INVALIDATE
        data-element=JobStatus_BsReten_RealTimeClock_Element, handle-invalid=DONT-INVALIDATE
        data-element=JobStatus_BsReten_Tripcomputer_Element, handle-invalid=DONT-INVALIDATE
        data-element=JobStatus_BsReten_Warning_Element, handle-invalid=DONT-INVALIDATE
        data-element=JobStatus_BsRt_CusDlt_Element, handle-invalid=DONT-INVALIDATE
        data-element=JobStatus_BsRt_FuelGauge_Element, handle-invalid=DONT-INVALIDATE
        data-element=JobStatus_BsRt_Illumination_Element, handle-invalid=DONT-INVALIDATE
        data-element=JobStatus_BsRt_Odometer_Element, handle-invalid=DONT-INVALIDATE
        data-element=JobStatus_BsRt_OilGauge_Element, handle-invalid=DONT-INVALIDATE
        data-element=JobStatus_BsRt_Personalization_Element, handle-invalid=DONT-INVALIDATE
        data-element=JobStatus_BsRt_PowerGauge_Element, handle-invalid=DONT-INVALIDATE
        data-element=JobStatus_BsRt_RealTimeClock_Element, handle-invalid=DONT-INVALIDATE
        data-element=JobStatus_BsRt_SpeedoGauge_Element, handle-invalid=DONT-INVALIDATE
        data-element=JobStatus_BsRt_TachoGauge_Element, handle-invalid=DONT-INVALIDATE
        data-element=JobStatus_BsRt_TempGauge_Element, handle-invalid=DONT-INVALIDATE
        data-element=JobStatus_BsRt_TripComputer_Element, handle-invalid=DONT-INVALIDATE
        data-element=JobStatus_BsRt_Warning_Element, handle-invalid=DONT-INVALIDATE
        data-element=JobStatus_BsShare_AssemblyManufacturingDate, handle-invalid=DONT-INVALIDATE
        data-element=JobStatus_BsShare_AssemblyPlantNumber, handle-invalid=DONT-INVALIDATE
        data-element=JobStatus_BsShare_EcuPartNumber_Element, handle-invalid=DONT-INVALIDATE
        data-element=JobStatus_BsShare_HWModification, handle-invalid=DONT-INVALIDATE
        data-element=JobStatus_BsShare_PCBSerialNumber, handle-invalid=DONT-INVALIDATE
        data-element=JobStatus_BsShare_ProductSerialNumber, handle-invalid=DONT-INVALIDATE
        data-element=JobStatus_BsShare_SMTManufacturingDate, handle-invalid=DONT-INVALIDATE
        data-element=JobStatus_BsShare_SMTPlantNumber, handle-invalid=DONT-INVALIDATE
        data-element=JobStatus_BsShare_SwUpdFotaFinPrint_Element, handle-invalid=DONT-INVALIDATE
        data-element=JobStatus_BsShare_SwUpdFotaMode_Element, handle-invalid=DONT-INVALIDATE
        data-element=JobStatus_BsShare_SwUpdFotaStatus_Element, handle-invalid=DONT-INVALIDATE
        data-element=JobStatus_BsShare_SwUpdFotadecrypt_Element, handle-invalid=DONT-INVALIDATE
        data-element=JobStatus_BsShare_SwUpdReflash_Element, handle-invalid=DONT-INVALIDATE
        data-element=JobStatus_BsShare_VehicleConfig_Element, handle-invalid=DONT-INVALIDATE
        data-element=JobStatus_BsShare_VisMeet_EOLEntry_Element, handle-invalid=DONT-INVALIDATE
        data-element=JobStatus_BsShare_VisMeet_Element, handle-invalid=DONT-INVALIDATE
        data-element=JobStatus_BsShare_VisteonPCBPartNumber, handle-invalid=DONT-INVALIDATE
        data-element=JobStatus_BsShare_VisteonPartNumber, handle-invalid=DONT-INVALIDATE
        data-element=JobStatus_RefCys_Certicificate1_Element, handle-invalid=DONT-INVALIDATE
        data-element=JobStatus_RefCys_Certicificate_Element, handle-invalid=DONT-INVALIDATE
    TI_Ctrl_LL_Duty: invalidation-policy{data-element=ILL_Duty, handle-invalid=DONT-INVALIDATE}
      data ILL_Duty: implementation-data-type=DataTypes/UInt8, type=DataTypes/UInt8
    TI_Ctrl_RGB_Dimming: invalidation-policy{data-element=RGB_Dimming, handle-invalid=DONT-INVALIDATE}
      data RGB_Dimming: implementation-data-type=DataTypes/UInt8, type=DataTypes/UInt8
    TI_Ctrl_Starter_Status: invalidation-policy{data-element=Starter_Status, handle-invalid=DONT-INVALIDATE}
      data Starter_Status: implementation-data-type=Boolean, type=Boolean
    TI_Ctrl_Ready_to_sleep: invalidation-policy{data-element=Ready_to_Sleep, handle-invalid=DONT-INVALIDATE}
      data Ready_to_Sleep: implementation-data-type=Boolean, type=Boolean
  impl type IllumCtrl_Op: category=STRUCTURE
    8 x element, all with category=TYPE_REFERENCE, implementation-data-type=UInt16:
      Brightness_Out
      Bulb_PWM_Out
      Illumination_Duty_Out
      RGB_Dimming_Out
      LED_PWM_Out
      Dial_Out
      Display_Out
      Telltale_Out
  sender receiver interface TI_IllumCtrl_Op: invalidation-policy{data-element=IllumCtrl_Op_Data, handle-invalid=DONT-INVALIDATE}
    data IllumCtrl_Op_Data: implementation-data-type=IllumCtrl_Op, type=IllumCtrl_Op
  sender receiver interface TI_SR_IlumDayNightRequired: invalidation-policy{data-element=IlumDayNightRequired, handle-invalid=DONT-INVALIDATE}
    data IlumDayNightRequired: implementation-data-type=DataTypes/UInt8, type=DataTypes/UInt8
  sender receiver interface TI_SR_Day_Night_Status: invalidation-policy{data-element=Day_Night_Status, handle-invalid=DONT-INVALIDATE}
    data Day_Night_Status: implementation-data-type=DataTypes/UInt8, type=DataTypes/UInt8
  client server interface TI_EcumExtInit
    operation Init
  client server interface TI_Pwm_rate_status
    operation PWM_Rate_Status
      arg ChannelID: implementation-data-type=DataTypes/UInt8, type=DataTypes/UInt8, direction=IN
      arg Status: implementation-data-type=UInt16, type=UInt16, direction=OUT
  sender receiver interface TI_Pwm_LCD_BL_Dimming: invalidation-policy{data-element=BL_Dimming, handle-invalid=DONT-INVALIDATE}
    data BL_Dimming: implementation-data-type=DataTypes/UInt8, type=DataTypes/UInt8
  sender receiver interface TI_StopPwmUpdate: invalidation-policy{data-element=channel_id, handle-invalid=DONT-INVALIDATE}
    data channel_id: implementation-data-type=DataTypes/UInt8, type=DataTypes/UInt8
  sender receiver interface TIEtm_Illumination_dummy: invalidation-policy{data-element=IllumStatus, handle-invalid=DONT-INVALIDATE}
    data IllumStatus: implementation-data-type=DataTypes/UInt8, type=DataTypes/UInt8
  impl type IgntionSubstateType: category=VALUE, base-type=uint8, compu {0=IgnOff, 1=IgnOn}, range raw 0..1
  sender receiver interface TI_WSS_IgnitionSubstate: invalidation-policy{data-element=IgnitionSubstate, handle-invalid=DONT-INVALIDATE}
    data IgnitionSubstate: implementation-data-type=IgntionSubstateType, type=IgntionSubstateType
  impl type VehicleActiveModes: category=VALUE, base-type=uint8, compu {0=NETWORK_SLEEP, 1=NETWORK_NORMAL, 2=NETWORK_STANDALONE}, range raw 0..2
  sender receiver interface TI_WSS_VehAppMode: invalidation-policy{data-element=WSSCurrentVehicleState, handle-invalid=DONT-INVALIDATE}
    data WSSCurrentVehicleState: implementation-data-type=VehicleActiveModes, type=VehicleActiveModes
  impl type ClusterModes: category=VALUE, base-type=uint8, compu {0=CLUSTER_INACTIVE, 1=CLUSTER_ACTIVE}, range raw 0..1
  sender receiver interface TI_WSS_ClusterMode: invalidation-policy{data-element=WSSCurrentClusterMode, handle-invalid=DONT-INVALIDATE}
    data WSSCurrentClusterMode: implementation-data-type=ClusterModes, type=ClusterModes
  sender receiver interface TI_Ctrl_Day_Night_mode: invalidation-policy{data-element=Day_Night_mode_Ctrl, handle-invalid=DONT-INVALIDATE}
    data Day_Night_mode_Ctrl: implementation-data-type=DataTypes/UInt8, type=DataTypes/UInt8
  sender receiver interface TI_CVS_EcoRunSystem_State_dummy: invalidation-policy{data-element=EcoRunSystem_Flag, handle-invalid=DONT-INVALIDATE}
    data EcoRunSystem_Flag: implementation-data-type=DataTypes/UInt8, type=DataTypes/UInt8
  impl type eAppMdl: category=VALUE, base-type=uint8, compu {0=eSWCApp_SmartKey_Bzr, 1=eSWCApp_Warn_MFLID, 2=eSWCApp_Head_TT, 3=eSWCApp_Tail_TT, 4=eSWCApp_Fuel, 5=eSWCApp_Illum, 6=eSWCApp_Buzzer, 7=eSWCApp_NVM, 8=eTFTDisplayOnExceptTurn, 9=eTurnL_Status, 10=eTurnR_Status, 11=eSWCApp_End}, range raw 0..11
  impl type eSleepSt: category=VALUE, base-type=uint8, compu {0=eSleep_Inactive, 1=eISleep_Active}, range raw 0..1
  client server interface TI_WSS_SWCAppSleepStatus
    operation SWCSleepStatus
      arg AppModule: implementation-data-type=eAppMdl, type=eAppMdl, direction=IN
      arg SleepStatus: implementation-data-type=eSleepSt, type=eSleepSt, direction=IN
  impl type IllumCtrl_Ip: category=STRUCTURE
    8 x element, all with category=TYPE_REFERENCE:
      Illumination_Mode: implementation-data-type=DataTypes/UInt8
      battery_status: implementation-data-type=DataTypes/UInt8
      Illumination_Sts: implementation-data-type=DataTypes/UInt8
      power_mode: implementation-data-type=DataTypes/UInt8
      step_value: implementation-data-type=DataTypes/UInt8
      step_direction: implementation-data-type=DataTypes/UInt8
      switch_type: implementation-data-type=DataTypes/UInt8
      Derating_Value: implementation-data-type=UInt16
  5 x sender receiver interface:
    TI_IllumCtrl_Ip: invalidation-policy{data-element=IllumCtrl_Ip_Data, handle-invalid=DONT-INVALIDATE}
      data IllumCtrl_Ip_Data: implementation-data-type=IllumCtrl_Ip, type=IllumCtrl_Ip
    TI_DimStepOutput: invalidation-policy{data-element=IllumStepValue, handle-invalid=DONT-INVALIDATE}
      data IllumStepValue: implementation-data-type=DataTypes/UInt8, type=DataTypes/UInt8
    TI_RheostatDayStep: invalidation-policy{data-element=RheostatDayStep, handle-invalid=DONT-INVALIDATE}
      data RheostatDayStep: implementation-data-type=DataTypes/UInt8, type=DataTypes/UInt8
    TI_RheostatNightStep: invalidation-policy{data-element=RheostatNightStep, handle-invalid=DONT-INVALIDATE}
      data RheostatNightStep: implementation-data-type=DataTypes/UInt8, type=DataTypes/UInt8
    TI_SR_RheostatChange: invalidation-policy{data-element=RheoUpdateVal, handle-invalid=DONT-INVALIDATE}
      data RheoUpdateVal: implementation-data-type=DataTypes/UInt8, type=DataTypes/UInt8
  impl type DisplayStatus: category=VALUE, base-type=uint8, compu {0=TFTDisplayOFF, 1=TFTDisplayON}, range raw 0..1
  sender receiver interface TI_TFTDisplayOn: invalidation-policy{data-element=TFTDisplayOn, handle-invalid=DONT-INVALIDATE}
    data TFTDisplayOn: implementation-data-type=DisplayStatus, type=DisplayStatus
  impl type HTimer:
    category=VALUE
    base-type=uint8
    compu {0=eWarningMask_Timerhandle, 1=eOWC_Timerhandle, 2=eNWD_Timerhandle, 3=eWarningBulbCheckMask_Timerhandle, 4=eInitWarning_TimerHandle, 5=eInitChimeTimerHandle, 6=eProgrammingTimerHandle, 7=eStubCounter_TimerHanlde, 8=eModeMgrDisplayPowerDownUp, 9=eModeMgrDisplayFaultAction, 10=eModeMgrDomanResetAction, 11=eModeMgrPowerFaultAction, 12=eEtm4SecTimer, 13=eEtm1200msecTimer, 14=eEtm3SecTimer, 15=eCallbackTimerOdoMdl, 16=eThrottleTimerOdoMdl, 17=eChangeupCallbackTimerodoMdl, 18=eTimerVehicleState, 19=eTimerVariantConfig, 20=WARNING_DISPLAY_TIMER_ID, 21=WARNING_HOLD_TIMER_ID, 22=WARNING_CYCLE_TIMER_ID, 23=WARNING_DISPLAYHOLD_TIMER_ID, 24=WARNING_ACK_TIMER_ID, 25=eTimerHandle_Sleep, 26=eInStartCount_TimerHandle, 27=eVehicleModeCount_TimerHandle, 28=e10secTimer, 29=e3secTimer, 30=e30secTimer, 31=e2_6secTimer, 32=eDcmApp5secTimer, 33=eDcmApp1secTimer, 34=eLidopen_OFFTimer, 35=eLidopen_ONTimer, 36=POPUP_DISPLAY_TIMER_ID, 37=POPUP_GRP_TAB_TIMER_ID, 38=eDrvRec5_6Timer, 39=eDrvRec3_6Timer, 40=eIDS_1SecTimer, 41=eIDS3_1SecTimer, 42=eIDS_3SecTimer, 43=ePerDispSet100msTimer, 44=eDrvRec1_2secTimer, 45=eDrvRec0_8secTimer, 46=eHMI_Initial_Blank_timer_ID, 47=eHMI_Fade_in_delay_timer_ID, 48=eKM6secTimer, 49=eKM5_8secTimer, 50=eKM0_6secTimer, 51=eKM0_2secTimer, 52=eIgnCANMode_3SecTimer, 53=eDem2_6secTimer, 54=eDem5secTimer, 55=e2FRheo5secTimer, 56=e2FSTSW5secTimer, 57=eLSTM3_Timer, 58=eLSTM4_Timer, 59=eDem_AFS_5sec_Timer, 60=WARNING_MSGTIMEOUT_1SEC_TIMER_ID, 61=eDCMApp_30Sec_Timer, 62=WRN_ACK_REDISPLAY_TIMER_ID, 63=eMenuScrollStart1sTimer, 64=eType4_6secTimer, 65=eDcmApp_0_35secTimer, 66=eDcmApp_0_35_1secTimer, 67=eRemoteCarFindCtrlStateTimer, 68=eBrake_Red_100msecTimer, 69=eStreeingSw_ReleaseTimer, 70=POPUP_SETTING_TIMER_ID, 71=eMenu100msTimer, 72=eBuzzerMiddleEast_6secs, 73=eBuzzerMiddleEast_6secs_2, 74=eMaxNumof16BitTimers, 75=eSleepMaxTimer, 76=eRentACarTimer, 77=eDoorWarn_Timer, 78=eTimerHandleGdtCdd, 79=eSample32BitTimer, 80=eTimerMax}
    range raw 0..80
  4 x client server interface:
    TI_If_TmExt_Timer_IsElapsed
      operation Timer_IsElapsed
        arg hTimer: implementation-data-type=HTimer, type=HTimer, direction=IN
        arg Timeout: implementation-data-type=UInt32, type=UInt32, direction=IN
        arg IsElapsed: implementation-data-type=Boolean, type=Boolean, direction=OUT
    TI_If_TmExt_Timer_IsStarted
      operation Timer_IsStarted
        arg hTimer: implementation-data-type=HTimer, type=HTimer, direction=IN
        arg IsStarted: implementation-data-type=Boolean, type=Boolean, direction=OUT
    TI_If_TmExt_Timer_Start
      operation Timer_Start
        arg hTimer: implementation-data-type=HTimer, type=HTimer, direction=IN
    TI_If_TmExt_Timer_Stop
      operation Timer_Stop
        arg hTimer: implementation-data-type=HTimer, type=HTimer, direction=IN
  14 x sender receiver interface:
    TI_Illum_Transstep: invalidation-policy{data-element=Trans_Stepvlaue, handle-invalid=DONT-INVALIDATE}
      data Trans_Stepvlaue: implementation-data-type=DataTypes/UInt8, type=DataTypes/UInt8
    TI_IlluminationDuty: invalidation-policy{data-element=DutyValue, handle-invalid=DONT-INVALIDATE}
      data DutyValue: implementation-data-type=UInt16, type=UInt16
    TI_DayNightRequired: invalidation-policy{data-element=ilumDNRequired, handle-invalid=DONT-INVALIDATE}
      data ilumDNRequired: implementation-data-type=DataTypes/UInt8, type=DataTypes/UInt8
    TI_DayNightStatus: invalidation-policy{data-element=illumDNStatus, handle-invalid=DONT-INVALIDATE}
      data illumDNStatus: implementation-data-type=DataTypes/UInt8, type=DataTypes/UInt8
    TI_RGBStepOutput: invalidation-policy{data-element=RGBStepValue, handle-invalid=DONT-INVALIDATE}
      data RGBStepValue: implementation-data-type=UInt16, type=UInt16
    TI_RHDW_Dbc: invalidation-policy{data-element=RHDW_Dbc, handle-invalid=DONT-INVALIDATE}
      data RHDW_Dbc: implementation-data-type=DataTypes/UInt8, type=DataTypes/UInt8
    TI_RHUP_Dbc: invalidation-policy{data-element=RHUP_Dbc, handle-invalid=DONT-INVALIDATE}
      data RHUP_Dbc: implementation-data-type=DataTypes/UInt8, type=DataTypes/UInt8
    TI_RheoSw_Raw_Status: invalidation-policy{data-element=RawdataStatus, handle-invalid=DONT-INVALIDATE}
      data RawdataStatus: implementation-data-type=DataTypes/UInt8, type=DataTypes/UInt8
    TI_RheoSwStatus: invalidation-policy{data-element=SwitchStatus, handle-invalid=DONT-INVALIDATE}
      data SwitchStatus: implementation-data-type=DataTypes/UInt8, type=DataTypes/UInt8
    TI_RheostatONSStatus: invalidation-policy{data-element=RheostatONSStatus, handle-invalid=DONT-INVALIDATE}
      data RheostatONSStatus: implementation-data-type=DataTypes/UInt8, type=DataTypes/UInt8
    TI_RheostatSwType: invalidation-policy{data-element=RheostatSwType, handle-invalid=DONT-INVALIDATE}
      data RheostatSwType: implementation-data-type=DataTypes/UInt8, type=DataTypes/UInt8
    TI_SR_IllumRheostatONSTimer: invalidation-policy{data-element=Rheostat_OnSTime, handle-invalid=DONT-INVALIDATE}
      data Rheostat_OnSTime: implementation-data-type=UInt16, type=UInt16
    TI_SR_Illum_StarterStatus: invalidation-policy{data-element=StarterStatus_Out, handle-invalid=DONT-INVALIDATE}
      data StarterStatus_Out: implementation-data-type=DataTypes/UInt8, type=DataTypes/UInt8
    TI_Etm_Illum_Sts: invalidation-policy{data-element=Illum_Status, handle-invalid=DONT-INVALIDATE}
      data Illum_Status: implementation-data-type=DataTypes/UInt8, type=DataTypes/UInt8
  impl type WarningId:
    category=VALUE
    base-type=uint16
    compu {0=WRN_NORM_BRLV_02, 1=WRN_NORM_ECB_02, 2=WRN_NORM_BRK_02, 3=WRN_NORM_BRKHLD_10, 4=WRN_NORM_BRKHLD_12, 5=WRN_NORM_BRKHLD_16, 6=WRN_NORM_ABS_02, 7=WRN_NORM_AUTHIG_02, 8=WRN_NORM_ADAHIG_02, 9=WRN_NORM_BRKHLD_02, 10=WRN_NORM_BRKHLD_03, 11..14=WRN_NORM_BRKHLD_05..WRN_NORM_BRKHLD_08, 15=WRN_NORM_BRKHLD_11, 16=WRN_NORM_BRKHLD_13, 17=WRN_NORM_BRKHLD_14, 18=WRN_NORM_BRKHLD_15, 19=WRN_NORM_BRKHLD_17, 20=WRN_NORM_AIRBAG_03, 21=WRN_NORM_AUTHIG_04, 22=WRN_NORM_ADAHIG_04, 23=WRN_NORM_ADASTT_05, 24=WRN_NORM_ADASTT_07, 25=WRN_NORM_ADASTT_09, 26=WRN_NORM_ADASTT_10, 27=WRN_NORM_ADASTT_11, 28=WRN_NORM_TFUEL_01, 29=WRN_NORM_PSC1_02, 30..36=WRN_NORM_PSC1_04..WRN_NORM_PSC1_10, 37=WRN_NORM_PSC1_12, 38=WRN_NORM_PSC1_13, 39=WRN_NORM_EPB_03, 40=WRN_NORM_EPB_04, 41=WRN_NORM_EPB_05, 42=WRN_NORM_EPB_08, 43..51=WRN_NORM_EPB_10..WRN_NORM_EPB_18, 52=WRN_NORM_TRCOFF_02, 53=WRN_NORM_WASLEV_02, 54=WRN_NORM_BVOOPE_02, 55=WRN_NORM_THESEN_02, 56=WRN_NORM_THESEN_03, 57..60=WRN_CUSTMIZE_DIGKEY_04..WRN_CUSTMIZE_DIGKEY_07, 61=WRN_NORM_MLGT_01, 62=WRN_NORM_TPWSR_01, 63=WRN_NORM_TPWSR_02, 64=WRN_NORM_TPWSR_03, 65..76=WRN_NORM_SMASTA_02..WRN_NORM_SMASTA_13, 77..81=WRN_NORM_SMASTA_17..WRN_NORM_SMASTA_21, 82..85=WRN_NORM_SMASTA_23..WRN_NORM_SMASTA_26, 86..92=WRN_NORM_SMASTA_28..WRN_NORM_SMASTA_34, 93..98=WRN_NORM_SMASTA_36..WRN_NORM_SMASTA_41, 99=WRN_NORM_LEDHEA_01, 100=WRN_NORM_HEALEV_02, 101=WRN_NORM_HEALEV_03, 102=WRN_NORM_GRISHU_02, 103=WRN_NORM_AVAS_02, 104=WRN_NORM_ALOA_03, 105=WRN_NORM_PCS2_03, 106=WRN_NORM_PCS2_11, 107=WRN_NORM_TRWIP_01, 108..111=WRN_NORM_RSEREM_02..WRN_NORM_RSEREM_05, 112=WRN_NORM_4WDSYS_03, 113=WRN_NORM_4WDSYS_04, 114=WRN_NORM_4WDSYS_06, 115=WRN_NORM_CVTOIL_02, 116=WRN_NORM_CVTOIL_03, 117=WRN_NORM_ATMAL_02, 118=WRN_NORM_SFTPOS_02, 119=WRN_NORM_SFTPOS_03, 120=WRN_NORM_SFTPOS_04, 121=WRN_NORM_MCBW_02, 122=WRN_NORM_TPWS_01, 123=WRN_NORM_TPWS_02, 124..127=WRN_NORM_OILMIL_02..WRN_NORM_OILMIL_05, 128=WRN_NORM_BRLV0_02, 129=WRN_NORM_OILPRE_01, 130=WRN_NORM_BRK0_02, 131=WRN_NORM_BRK0_03, 132..137=WRN_NORM_EPS_02..WRN_NORM_EPS_07, 138=WRN_NORM_EPS_09, 139=WRN_NORM_EPS_10, 140=WRN_NORM_EPS_11, 141=WRN_NORM_FUECAP_02, 142=WRN_NORM_CHEENG_02, 143=WRN_NORM_CHEENG_03, 144=WRN_NORM_CHEENG_04, 145=WRN_NORM_CHEENG_07, 146=WRN_NORM_ROLAWA_01, 147=WRN_NORM_ROLAWA_02, 148=WRN_NORM_ROLAWA_03, 149..155=WRN_NORM_GPF_05..WRN_NORM_GPF_11, 156=WRN_NORM_OILLEV_02, 157=WRN_NORM_COOTEM_03, 158=WRN_NORM_ONACCN_03, 159=WRN_NORM_BATLOW_02, 160=WRN_NORM_CHAMAL_02, 161=WRN_NORM_CHAMAL_03, 162=WRN_NORM_POWMAN_02, 163=WRN_NORM_SOCLOW_02, 164=WRN_NORM_SOCLOW_03, 165..168=WRN_NORM_BATINS_02..WRN_NORM_BATINS_05, 169=WRN_NORM_ONACCP_02, 170=WRN_NORM_ALMN_02, 171=WRN_NORM_HEAECU_02, 172=WRN_NORM_BOS_02, 173=WRN_NORM_BOS_03, 174..182=WRN_NORM_EVMOD_02..WRN_NORM_EVMOD_10, 183=WRN_NORM_DSC_02, 184=WRN_NORM_DSC_03, 185=WRN_NORM_DSC_04, 186..196=WRN_NORM_ROLAWA1_01..WRN_NORM_ROLAWA1_11, 197..200=WRN_NORM_MAICER_09..WRN_NORM_MAICER_12, 201=WRN_NORM_PKSB_09, 202=WRN_NORM_PKSB_10, 203=WRN_NORM_PKSB_11, 204=WRN_NORM_PKSB_13, 205=WRN_NORM_PKSB_14, 206=WRN_NORM_ISA_02, 207=WRN_NORM_ISA_04, 208=WRN_NORM_TCBM_01, 209=WRN_NORM_TCBM_02, 210=WRN_NORM_ADAFRO_02, 211=WRN_NORM_PDA_03, 212=WRN_NORM_RTAN_03, 213=WRN_NORM_SEA_02, 214=WRN_NORM_T120_01, 215=WRN_POWER_EIGCON_02, 216=WRN_POWER_EIGCON_04, 217..220=WRN_PROSRV_PROSRV_02..WRN_PROSRV_PROSRV_05, 221..226=WRN_PROSRV_PROSRV_08..WRN_PROSRV_PROSRV_13, 227=WRN_PROSRV_PROSRV_22, 228=WRN_PROSRV_PROSRV_23, 229=WRN_NORM_BATCOO_02, 230=WRN_NORM_BATCOO_03, 231=WRN_NORM_LDA_02, 232=WRN_NORM_LDA_03, 233=WRN_NORM_LDA_06, 234=WRN_NORM_LDA_07, 235=WRN_NORM_LTA_02, 236=WRN_NORM_LTA_03, 237=WRN_NORM_LTA_07, 238..241=WRN_NORM_LCA_02..WRN_NORM_LCA_05, 242=WRN_NORM_LCA_15, 243=WRN_NORM_LCA_16, 244=WRN_NORM_LCA_17, 245=WRN_NORM_LCA_20, 246=WRN_NORM_RSA_01, 247=WRN_NORM_RSA_04, 248=WRN_NORM_RSA_05, 249=WRN_NORM_CHADYN_01, 250=WRN_NORM_CHADYN_02, 251=WRN_NORM_TOWWAR_02, 252=WRN_NORM_TOWWAR_03, 253=WRN_NORM_TOWWAR_05, 254=WRN_NORM_DMC_02, 255=WRN_NORM_DMC_03, 256=WRN_NORM_DMC_05, 257=WRN_NORM_DMC_06, 258..261=WRN_NORM_DMC_12..WRN_NORM_DMC_15, 262=WRN_NORM_DMC_17, 263=WRN_NORM_DMC_18, 264=WRN_NORM_ICYRA_01, 265=WRN_NORM_SEA_NCYC_02, 266=WRN_NORM_DRIPOW_02, 267=WRN_NORM_DRIPOW_03, 268=WRN_NORM_DRIPOW_04, 269=WRN_NORM_CCS_02, 270=WRN_NORM_CCS_03, 271..281=WRN_NORM_ACC_02..WRN_NORM_ACC_12, 282=WRN_NORM_ACC_18, 283=WRN_NORM_ACC_19, 284=WRN_NORM_ACC_21, 285..291=WRN_NORM_DESA_02..WRN_NORM_DESA_08, 292=WRN_NORM_PEXI_02, 293..299=WRN_NORM_RESADJ_09..WRN_NORM_RESADJ_15, 300=WRN_NORM_TSMODE_02, 301=WRN_NORM_UNIOVE_02, 302=WRN_NORM_UNIOVE_04, 303=WARN_ADAS_SDG_01, 304=WRN_ADAS_PDA_01, 305=WRN_ADAS_PDA_02, 306=WRN_NORM_TDOOR_01, 307=WRN_NORM_TDOOR_02, 308=WRN_NORM_TDOOR_03, 309=WRN_NORM_ACCHOL_02, 310=WRN_NORM_ACCHOL_03, 311=WRN_NORM_ACCHOL_05, 312..318=WRN_NORM_MAICER_09_RESADJ_09..WRN_NORM_MAICER_09_RESADJ_15, 319..325=WRN_NORM_MAICER_11_RESADJ_09..WRN_NORM_MAICER_11_RESADJ_15, 326=WRN_NORM_CVRS_04, 327=WRN_NORM_CVRS_05, 328..334=WRN_NORM_SMASTA_42..WRN_NORM_SMASTA_48, 335=WRN_MFLID_MFLID_01, 336=WRN_NORM_MFLID_02, 337=WRN_NORM_MFLID_03, 338=WRN_NORM_TMNT_15, 339=WRN_NORM_TMNT_16, 340=WRN_ADAS_LCA1, 341=WRN_ADAS_LCA2, 342=WRN_DOOR_UNLMOD_02, 343=WARN_ADAS_PDA1, 344..350=WRN_ADAS_URSM_01..WRN_ADAS_URSM_07, 351..367=WRN_NORM_SYSMAL_HVIND1..WRN_NORM_SYSMAL_HVIND17, 368=WRN_NORM_FHL_04, 369=WRN_NORM_SMASTA_52, 370=WRN_NORM_SMASTA_53, 371..377=WRN_NORM_GPF_MEV01_02..WRN_NORM_GPF_MEV01_08, 378=WRN_NORM_VCOPE_02, 379=WRN_NORM_VCOPE_03, 380=WRN_ADAS_LCA_01, 381=WRN_ADAS_LCA_03, 382=WRN_ADAS_LCA_04, 383..389=WRN_NORM_FCMDI_01..WRN_NORM_FCMDI_07, 390=WRN_NORM_TSMODE_VM01_02, 391..395=WRN_ADAS_ACC_01..WRN_ADAS_ACC_05, 396..431=WRN_ADAS_ACC_22..WRN_ADAS_ACC_57, 432..439=WRN_NORM_ACC_VM01_GSY07_02..WRN_NORM_ACC_VM01_GSY07_09, 440..443=WRN_NORM_ACC_VM01_EFE02_02..WRN_NORM_ACC_VM01_EFE02_05, 444..447=WRN_NORM_ACC_VM01_EFE01_02..WRN_NORM_ACC_VM01_EFE01_05, 448..455=WRN_NORM_ACC_VM01_GME12_02..WRN_NORM_ACC_VM01_GME12_09, 456=WRN_NORM_FCTA_01, 457=WARN_NORM_GRISHU_02, 458=WRN_NORM_CHEENG_06, 459=WRN_NORM_SFTPOSL_02, 460=WRN_NORM_SFTPOSL_03, 461=WRN_NORM_SFTPOSL_04, 462=WRN_NORM_TPMS_02, 463=WRN_NORM_TPMS_03, 464=WRN_NORM_STOSTA_02, 465=WRN_NORM_RSRDI_02, 466=WRN_NORM_PSSDI_02, 467=WRN_NORM_UNOVE_02, 468=WRN_NORM_UNOVE_04, 469=WRN_CUSTMIZE_PERSET_02, 470=WRN_CUSTMIZE_PERSET_03, 471=WRN_CUSTMIZE_PERSET_04, 472..490=WRN_CUSTMIZE_PERSET_06..WRN_CUSTMIZE_PERSET_24, 491=WRN_NORM_SEA_VM01_02, 492=WRN_NORM_SEA_VM02_02, 493..496=WRN_NORM_PSSDI_03..WRN_NORM_PSSDI_06, 497=WRN_NORM_CLESON_02, 498=WRN_CUTMIZE_DIGKEY_01, 499=WRN_NORM_RSRDI_03, 500=WRN_ADAS_LCA_02, 501..510=WRN_NORM_TPMS_VM02_REQ02..WRN_NORM_TPMS_VM02_REQ11, 511=WRN_NORM_TPMS_VM02_GWM08_REQ02, 512=WRN_NORM_TPMS_VM02_GWM08_REQ01, 513=WRN_NORM_PSSDI_07, 514=WRN_NORM_EXWUOC_04, 515=WRN_NORM_EXWUOC_06, 516=WRN_NORM_EXWUOC_10, 517=WRN_NORM_EXWUOC_16, 518=WRN_NORM_EXWUOC_17, 519=WRN_NORM_EXWUOC_18, 520=WRN_NORM_PBD_02, 521=WRN_NORM_FCTA_02, 522=WRN_NORM_TMN_02, 523=WRN_NORM_TMN_03, 524=WRN_NORM_PEDPRO_03, 525=WRN_NORM_PEDPRO_04, 526=WRN_NORM_LEAUNF_02, 527=WRN_NORM_LEAUNF_04, 528..537=WRN_NORM_HCS_02..WRN_NORM_HCS_11, 538=WRN_NORM_SCB_02, 539=WRN_NORM_ITS_02, 540=WRN_NORM_ITS_06, 541=WRN_NORM_ITS_MEV01_02, 542=WRN_NORM_ITS_MEV01_04, 543=WRN_NORM_ITS_MEV01_05, 544=WRN_NORM_ITS_MEV01_06, 545=WRN_NORM_MAPACC_02, 546=WRN_NORM_OAA_03, 547=WRN_NORM_OAA_04, 548=WRN_NORM_LCA_21, 549..554=WRN_NORM_LCA_26..WRN_NORM_LCA_31, 555=WRN_NORM_NLOCK_02, 556=WRN_NORM_ATFWRN_02, 557=WRN_NORM_LTA_04, 558=WRN_NORM_LTA_05, 559=WRN_NORM_LTA_06, 560..564=WRN_NORM_LTA_08..WRN_NORM_LTA_12, 565=WRN_NORM_PCL_02, 566..573=WRN_ADAS_LCA_05..WRN_ADAS_LCA_12, 574=WRN_NORM_LDA_04, 575=WRN_NORM_LDA_05, 576=WRN_ADAS_OAA_01, 577=WRN_NORM_TPMS_VM02_GWM08_REQ06, 578=WRN_NORM_TPMS_VM02_GWM08_REQ07, 579=WRN_ADAS_ACC_G7, 580=WRN_ADAS_ACC_G11_01, 581=WRN_ADAS_ACC_G11_02, 582=WRN_ADAS_ACC_G11_03, 583=WRN_ADAS_ACC_G20, 584=WRN_ADAS_ACC_G22, 585=WRN_ADAS_ACC_G23, 586=HUD_WRN_NORM_PCS1_05, 587=HUD_WRN_NORM_PCS1_06, 588=HUD_WRN_ADAS_ACC_G20, 589=HUD_WRN_ADAS_ACC_G7, 590=HUD_WRN_ADAS_ACC_G23, 591=HUD_WRN_ADAS_ACC_G22, 592=HUD_WRN_ADAS_LCA_02, 593=HUD_WRN_NORM_DA_02, 594=HUD_WRN_NORM_SCB_02, 595=HUD_WRN_NORM_ITS_MEV01_04, 596=HUD_WRN_NORM_ITS_MEV01_02, 597=HUD_WRN_NORM_ITS_02, 598=HUD_WRN_NORM_BOS_02, 599=HUD_WRN_NORM_DSC_02, 600=HUD_WRN_NORM_PMAR_03, 601=HUD_WRN_ADAS_OAA_01, 602=HUD_WRN_NORM_ACC_19, 603=HUD_WRN_NORM_LCA_29, 604..611=HUD_WRN_ADAS_LCA_05..HUD_WRN_ADAS_LCA_12, 612=HUD_WRN_NORM_RTAN_02, 613=HUD_WRN_NORM_LDA_02, 614=HUD_WRN_ADAS_LCA_03, 615=HUD_WRN_ADAS_LCA_04, 616=HUD_WRN_NORM_ACC_21, 617=HUD_WRN_ADAS_ACC_G11_01, 618=HUD_WRN_ADAS_ACC_G11_02, 619=HUD_WRN_ADAS_ACC_G11_03, 620=HUD_WRN_NORM_DSC_04, 621..629=WRN_NORM_GROUP1..WRN_NORM_GROUP9, 630=TotalNumOfWarnings}
    range raw 0..630
  impl type WarningStatus: category=VALUE, base-type=uint8, compu {0=UI_WARNING_STATUS_OFF, 1=UI_WARNING_STATUS_ON, 2=UI_WARNING_STATUS_UNKNOWN}, range raw 0..2
  impl type WarningEvent: category=VALUE, base-type=uint8, compu {0=UI_WARNING_EVENT_NONE, 1=UI_WARNING_EVENT_RETRIGGER, 2=UI_WARNING_EVENT_FORCED}, range raw 0..2
  client server interface TI_Ctrl_Warning_UpdateWarningStatus
    operation UpdateWarningStatus
      4 x arg, all with direction=IN:
        WarningCurId: implementation-data-type=WarningId, type=WarningId
        WarningCurStatus: implementation-data-type=WarningStatus, type=WarningStatus
        WarningCurEvent: implementation-data-type=WarningEvent, type=WarningEvent
        WarningPayload: implementation-data-type=UInt32, type=UInt32
  client server interface TI_PwmCurrent_Duty
    operation GetPwmCurrentDuty
      arg ChannelID: implementation-data-type=DataTypes/UInt8, type=DataTypes/UInt8, direction=IN
      arg Channel_Duty: implementation-data-type=UInt16, type=UInt16, direction=OUT
  impl type IOCtrl_Type: category=VALUE, base-type=uint8, compu {1=eSPEEDO, 2=eTACHO, 4=eHVSYS_INDICATOR, 8=eSPEAKER, 16=eTELLTALE, 32=eBUTTONEVENT, 64=eMIDDISPALY}, range raw 1..64
  sender receiver interface TI_SR_Dcm_AppStopNotification: invalidation-policy{data-element=AppId, handle-invalid=DONT-INVALIDATE}
    data AppId: implementation-data-type=IOCtrl_Type, type=IOCtrl_Type
  sender receiver interface TI_SR_Diag2F_Rheo: invalidation-policy{data-element=Diag_RheoStat, handle-invalid=DONT-INVALIDATE}
    data Diag_RheoStat: implementation-data-type=DataTypes/UInt8, type=DataTypes/UInt8
  sender receiver interface TI_EcoRunPresenceFlag: invalidation-policy{data-element=EcoRunPresenceFlag, handle-invalid=DONT-INVALIDATE}
    data EcoRunPresenceFlag: implementation-data-type=DataTypes/UInt8, type=DataTypes/UInt8
  client server interface TI_MVC_Get_Variant_State_Dummy
    operation Get_Variant_Config_State
      arg VariantID: implementation-data-type=DataTypes/UInt8, type=DataTypes/UInt8, direction=IN
      arg VariantActiveSt: implementation-data-type=DataTypes/UInt8, type=DataTypes/UInt8, direction=OUT
  sender receiver interface TI_MVC_PowerTrain_State_Dummy: invalidation-policy{data-element=PowerTrain_Flag, handle-invalid=DONT-INVALIDATE}
    data PowerTrain_Flag: implementation-data-type=DataTypes/UInt8, type=DataTypes/UInt8
  4 x client server interface:
    TI_PwmWithTime
      operation GetPwmWithTime
        arg ChannelID: implementation-data-type=IoHwAb_PwmSignalIdType, type=IoHwAb_PwmSignalIdType, direction=IN
        arg TargetDuty: implementation-data-type=UInt16, type=UInt16, direction=IN
        arg TargetTime: implementation-data-type=UInt16, type=UInt16, direction=IN
    TI_PwmWithTimeExp
      operation GetPwmWithTimeExp
        arg ChannelID: implementation-data-type=IoHwAb_PwmSignalIdType, type=IoHwAb_PwmSignalIdType, direction=IN
        arg TargetDuty: implementation-data-type=UInt16, type=UInt16, direction=IN
        arg TargetTime: implementation-data-type=UInt16, type=UInt16, direction=IN
    TI_PwmDirect
      operation GetPwmDirect
        arg ChannelID: implementation-data-type=IoHwAb_PwmSignalIdType, type=IoHwAb_PwmSignalIdType, direction=IN
        arg TargetDuty: implementation-data-type=UInt16, type=UInt16, direction=IN
    TI_Variant_Status
      operation GetVariant_Status
        arg Variant_Ind: implementation-data-type=DataTypes/UInt8, type=DataTypes/UInt8, direction=IN
        arg Variant_Status: implementation-data-type=DataTypes/UInt8, type=DataTypes/UInt8, direction=OUT
  impl type UserIdType: category=VALUE, base-type=uint8, compu {1=USER1, 2=USER2, 3=USER3, 4=GUEST}, range raw 1..4
  impl type CustResetType: category=VALUE, base-type=uint8, compu {0=NO_REQUEST, 1=USER1, 2=USER2, 3=USER3, 4=GUEST}, range raw 0..4
  impl type SettingResetResult_Type: category=VALUE, base-type=uint8, compu {0=INPROGRESS, 1=SUCCESS, 2=FAIL}, range raw 0..2
  sender receiver interface TI_SR_UserID_Data
    data CurrentUserID: implementation-data-type=UserIdType, type=UserIdType
    data CustomizeReset: implementation-data-type=CustResetType, type=CustResetType
    data SettingResetResult: implementation-data-type=SettingResetResult_Type, type=SettingResetResult_Type
    invalidation-policys:
      data-element=CurrentUserID, handle-invalid=DONT-INVALIDATE
      data-element=CustomizeReset, handle-invalid=DONT-INVALIDATE
      data-element=SettingResetResult, handle-invalid=DONT-INVALIDATE
  impl type ModeStatus: category=VALUE, base-type=uint8, compu {0=STATUS_OFF, 1=STATUS_ON}, range raw 0..1
  6 x sender receiver interface:
    TI_WSS_ACCMode: invalidation-policy{data-element=WSSAccState, handle-invalid=DONT-INVALIDATE}
      data WSSAccState: implementation-data-type=ModeStatus, type=ModeStatus
    TI_WSS_BAMode: invalidation-policy{data-element=WSSBaState, handle-invalid=DONT-INVALIDATE}
      data WSSBaState: implementation-data-type=ModeStatus, type=ModeStatus
    TI_WSS_BAOFMode: invalidation-policy{data-element=WSSBaOfState, handle-invalid=DONT-INVALIDATE}
      data WSSBaOfState: implementation-data-type=ModeStatus, type=ModeStatus
    TI_WSS_IgnitionBuzState: invalidation-policy{data-element=IgnitioBuznstate, handle-invalid=DONT-INVALIDATE}
      data IgnitioBuznstate: implementation-data-type=IgntionSubstateType, type=IgntionSubstateType
    TI_WSS_IGP_CANMode: invalidation-policy{data-element=WSSIGPCANState, handle-invalid=DONT-INVALIDATE}
      data WSSIGPCANState: implementation-data-type=ModeStatus, type=ModeStatus
    TI_WSS_IGPMode: invalidation-policy{data-element=WSSIGPState, handle-invalid=DONT-INVALIDATE}
      data WSSIGPState: implementation-data-type=ModeStatus, type=ModeStatus
  client server interface TI_WSS_SWC_EarlyWakeUpHandle
    operation SWCEarlyWakeUpHandle
  impl type HMIReadySts_Type: category=VALUE, base-type=uint8, compu {0=eHMI_NOT_READY, 1=eHMI_READY}, range raw 0..1
  sender receiver interface TI_SR_HMIReadyStatus: invalidation-policy{data-element=HMI_ReadyStatus, handle-invalid=DONT-INVALIDATE}
    data HMI_ReadyStatus: implementation-data-type=HMIReadySts_Type, type=HMIReadySts_Type
  impl type ClusterInitModes: category=VALUE, base-type=uint8, compu {0=CLUSTER_INIT, 1=CLUSTER_RUN, 2=CLUSTER_RUN_READALL}, range raw 0..2
  sender receiver interface TI_WSS_Init_ClusterMode: invalidation-policy{data-element=WSSCurrentClusterInitMode, handle-invalid=DONT-INVALIDATE}
    data WSSCurrentClusterInitMode: implementation-data-type=ClusterInitModes, type=ClusterInitModes
  impl type SleepType: category=VALUE, base-type=uint8, compu {0=SLEEEP_READY, 1=SLEEP_NOT_READY}, range raw 0..1
  sender receiver interface TI_Sleep_Ready_Status: invalidation-policy{data-element=Sleep_Status, handle-invalid=DONT-INVALIDATE}
    data Sleep_Status: implementation-data-type=SleepType, type=SleepType
  sender receiver interface TI_TFTDisplayOnExTurn: invalidation-policy{data-element=TFTDisplayOnExTurn, handle-invalid=DONT-INVALIDATE}
    data TFTDisplayOnExTurn: implementation-data-type=DisplayStatus, type=DisplayStatus
  impl type BOOL_TYPE: category=VALUE, base-type=uint8, compu {0=DBG_TRUE, 1=DBG_FALSE}, range raw 0..1
  5 x sender receiver interface:
    TI_FuelLid_Status: invalidation-policy{data-element=FuelLidStatus, handle-invalid=DONT-INVALIDATE}
      data FuelLidStatus: implementation-data-type=BOOL_TYPE, sw-impl-policy=QUEUED, type=BOOL_TYPE
    TI_Hazard_Status: invalidation-policy{data-element=HazardStatus, handle-invalid=DONT-INVALIDATE}
      data HazardStatus: implementation-data-type=BOOL_TYPE, sw-impl-policy=QUEUED, type=BOOL_TYPE
    if_SR_PhasedRead_Status_phase1readcompleted: invalidation-policy{data-element=PhasedRead_Status_phase1readcompleted, handle-invalid=DONT-INVALIDATE}
      data PhasedRead_Status_phase1readcompleted: implementation-data-type=Boolean, type=Boolean
    if_SR_PhasedRead_Status_phase2readcompleted: invalidation-policy{data-element=PhasedRead_Status_phase2readcompleted, handle-invalid=DONT-INVALIDATE}
      data PhasedRead_Status_phase2readcompleted: implementation-data-type=Boolean, type=Boolean
    if_SR_PhasedRead_Status_phase3readcompleted: invalidation-policy{data-element=PhasedRead_Status_phase3readcompleted, handle-invalid=DONT-INVALIDATE}
      data PhasedRead_Status_phase3readcompleted: implementation-data-type=Boolean, type=Boolean
  impl type TT_ENUM_TYPE:
    category=VALUE
    base-type=uint8
    compu {0=TT_ABS_INDEX, 1=TT_AIRBAG_INDEX, 2=TT_BRAKE_RED_INDEX, 3=TT_BRAKE_HOLD_INDEX, 4=TT_BRAKE_YELLOW_INDEX, 5=TT_PARKING_BRAKE_INDEX, 6=TT_TRACTION_CTRL_INDEX, 7=TT_VCS_OFF_INDEX, 8=TT_ABS_INDEX_US, 9=TT_BRAKE_RED_INDEX_US, 10=TT_PARKING_BRAKE_INDEX_US, 11=TT_SAF_RES4_INDEX, 12=TT_SAF_RES5_INDEX, 13=TT_SAF_RES6_INDEX, 14=TT_SAF_RES7_INDEX, 15=TT_SAF_RES8_INDEX, 16=TT_ADAS_INDEX, 17=TT_AUTO_HIGH_BEAM_INDEX, 18=TT_BRAKE_HOLD_STANDBY_INDEX, 19=TT_FUEL_INDEX, 20=TT_FFOG_INDEX, 21=TT_HEAD_INDEX, 22=TT_HIGH_BEAM_INDEX, 23=TT_PCS_OFF_INDEX, 24=TT_READY_INDEX, 25=TT_RFOG_INDEX, 26=TT_SEAT_BELT_INDEX, 27=TT_TAIL_LIGHT_INDEX, 28=TT_TURN_HAZARD_RIGHT_INDEX, 29=TT_TURN_HAZARD_LEFT_INDEX, 30=TT_EWT_INDEX, 31=TT_AAHB_LO_GREEN, 32=TT_AAHB_SHADED_GREEN, 33=TT_AAHB_HI_GREEN, 34=TT_AAHB_HI_WHITE, 35=TT_ITS_INFRA, 36=TT_ITS_VEHICLE, 37=TT_ITS_COMBINATION, 38=TT_SSS_GREEN, 39=TT_SSS_AMBER, 40=TT_LCA_LEFT_WHITE, 41=TT_LCA_LEFT_GRAY, 42=TT_LCA_LEFT_GREEN, 43=TT_LCA_RIGHT_WHITE, 44=TT_LCA_RIGHT_GRAY, 45=TT_LCA_RIGHT_GREEN, 46=TT_LTA_GREEN, 47=TT_LTA_WHITE, 48=TT_LTA_AMBER, 49=TT_CCT_GREEN, 50=TT_CCT_WHITE, 51=TT_CCT_AMBER, 52=TT_RCCT_GREEN, 53=TT_RCCT_WHITE, 54=TT_RCCT_AMBER, 55=TT_ACCDT_WHITE_LV4, 56=TT_ACCDT_WHITE_LV3, 57=TT_ACCDT_WHITE_LV2, 58=TT_ACCDT_WHITE_LV1, 59=TT_ACCDT_GREEN_LV4, 60=TT_ACCDT_GREEN_LV3, 61=TT_ACCDT_GREEN_LV2, 62=TT_ACCDT_GREEN_LV1, 63=TT_SL_GREEN, 64=TT_SL_WHITE, 65=TT_SL_AMBER, 66=TT_AUTO_LSD_AMBER, 67=TT_DRIVEMODE_SPORT, 68=TT_DRIVEMODE_ECO, 69=TT_DRIVEMODE_CUSTOM, 70=TT_DRIVEMODE_RANGE, 71=TT_DRIVEMODE_REARCOMFORT, 72=TT_DRIVEMODE_SNOW, 73=TT_DRIVEMODE_TRACK, 74=TT_LDA_RED, 75=TT_LDA_AMBER, 76=TT_LDA_WHITE, 77=TT_LDA_OFF_AMBER, 78=TT_LDA_OFF_WHITE, 79=TT_ECOLAMP, 80=TT_PS_GREEN, 81=TT_PKBOPER_TXT, 82=TT_PKBOPER_IMG, 83=TT_TPMS_INDEX, 84=TT_EBPWIND_RED_US, 85=TT_EBPWIND_RED, 86=TT_FMSR_AMBER, 87=TT_FMFR_AMBER, 88=TT_MULWL_GREEN, 89=TT_HCS_ACCESS_GREEN, 90=TT_HCS_LIFT_GREEN, 91=TT_HCS_LIFT_AMBER, 92=TT_TOTAL_NUM_OF_TELLTALES}
    range raw 0..92
  impl type TT_OP_STATES:
    category=VALUE
    base-type=uint8
    compu {0=TT_TURN_OFF, 1=TT_TURN_ON, 2=TT_FLASH_QUARTER_HZ, 3=TT_FLASH_HALF_HZ, 4=TT_FLASH_CSNR_HALF_HZ, 5=TT_FLASH_0_83_HZ, 6=TT_FLASH_1HZ, 7=TT_FLASH_1_33_HZ, 8=TT_FLASH_1_66_HZ, 9=TT_FLASH_2HZ, 10=TT_FLASH_2_5_HZ, 11=TT_FLASH_2_66_HZ, 12=TT_FLASH_TRNHZ_Normal, 13=TT_FLASH_TRNHZ_Fast, 14=TT_FLASH_TRNHZ_FHL, 15=TT_FLASH_3HZ, 16=TT_FLASH_4HZ, 17=TT_FLASH_5HZ, 18=TT_FLASH_SYNC_QUARTER_HZ, 19=TT_FLASH_SYNC_HALF_HZ, 20=TT_FLASH_SYNC_CSNR_HALF_HZ, 21=TT_FLASH_SYNC_0_83_HZ, 22=TT_FLASH_SYNC_1HZ, 23=TT_FLASH_SYNC_1_33_HZ, 24=TT_FLASH_SYNC_1_66_HZ, 25=TT_FLASH_SYNC_2HZ, 26=TT_FLASH_SYNC_2_5_HZ, 27=TT_FLASH_SYNC_2_66_HZ, 28=TT_FLASH_TRNHZ_SYNC_Normal, 29=TT_FLASH_TRNHZ_SYNC_Fast, 30=TT_FLASH_TRNHZ_SYNC_FHL, 31=TT_FLASH_SYNC_4HZ, 32=TT_FLASH_SYNC_5HZ, 255=TT_CONFIGURED_OFF}
    range raw 0..255
  sender receiver interface TI_TelltaleIndexStatus
    data TTIndex: implementation-data-type=TT_ENUM_TYPE, type=TT_ENUM_TYPE
    data TTStatus: implementation-data-type=TT_OP_STATES, type=TT_OP_STATES
    invalidation-policys:
      data-element=TTIndex, handle-invalid=DONT-INVALIDATE
      data-element=TTStatus, handle-invalid=DONT-INVALIDATE
  impl type TT_OP_Type: category=ARRAY
    element ArrayElement: category=VALUE, array-size=92, array-size-semantics=FIXED-SIZE, base-type=uint8
  sender receiver interface TITelltaleStatusOutput: invalidation-policy{data-element=TelltaleOpArray, handle-invalid=DONT-INVALIDATE}
    data TelltaleOpArray: implementation-data-type=TT_OP_Type, type=TT_OP_Type
  impl type SMainHMIReadyStatus: category=STRUCTURE
    element status: implementation-data-type=DataTypes/UInt8
  sender receiver interface MainHMIReadyStatus: invalidation-policy{data-element=MainHMIReadyStatusData, handle-invalid=DONT-INVALIDATE}
    data MainHMIReadyStatusData: implementation-data-type=SMainHMIReadyStatus, sw-impl-policy=QUEUED, type=SMainHMIReadyStatus
  impl type TTBlinkArray: category=ARRAY
    element ArrayElement: category=VALUE, array-size=16, array-size-semantics=FIXED-SIZE, base-type=uint8
  impl type TTFlashMask: category=VALUE, base-type=uint8, compu {0=NOT_IN_SYNCH, 1=FLASH_180DEG_PHASE_SYNCH, 2=FLASH_360DEG_PHASE_SYNCH, 4=FLASH_OFF_PERIOD_MASK}, range raw 0..4
  sender receiver interface TITelltaleBlinkStatusArray
    data TTBlinkStatusArray: implementation-data-type=TTBlinkArray, type=TTBlinkArray
    data TTdummyDataForTypes: implementation-data-type=TTFlashMask, type=TTFlashMask
    invalidation-policys:
      data-element=TTBlinkStatusArray, handle-invalid=DONT-INVALIDATE
      data-element=TTdummyDataForTypes, handle-invalid=DONT-INVALIDATE
  impl type HMI_Odo_Type: category=VALUE, base-type=uint8, compu {0=eODO_TYPE_OFF, 1=eODO_TYPE_BLANK, 2=eODO_TYPE_ODO, 3=eODO_TYPE_TRIPA, 4=eODO_TYPE_TRIPB, 5=eODO_TYPE_OILMIL_DISTANCE, 6=eODO_TYPE_FUEL_OW_ADV_NOTICE, 7=eODO_TYPE_FUEL_OVER_WRITE, 8=eODO_TYPE_POWER_STATUS_ACC, 9=eODO_TYPE_POWER_STATUS_ON, 10=eODO_TYPE_OILMIL_DISTANCE_INT}, range raw 0..10
  sender receiver interface TI_SR_HMI_Odo_Type: invalidation-policy{data-element=HMI_OdoType, handle-invalid=DONT-INVALIDATE}
    data HMI_OdoType: implementation-data-type=HMI_Odo_Type, type=HMI_Odo_Type
